VERSION ""

NS_ :

BS_:

BU_: PowertrainControlModule AtmosphericSensor SafetyRestraintSystem2 Aftertreatment_2_GasOutlet Aftertreatment_2_GasIntake DieselPartFilterControl Turbocharger SafetyRestraintSystem1 CabDisplay2 Aftertreatment_1_GasOutlet Aftertreatment_1_GasIntake OnBoardDataLogger OffBoardDiagnosticTool2 OffBoardDiagnosticTool1 FileServer ParkingBrakeController SeatController2 FanDriveController SteeringColumnUnit CommunicationUnitRadio CommunicationUnitSatellite CommunicationUnitCellular PropulsionBatteryCharger ChassisController2 ChassisController1 EngineValveControl AuxiliaryHeater2 AuxiliaryHeater1 ClutchUnit RampControl InformationSystem1 SuspensionSystemController2 OilSensor VehicleDynamicStability ExhaustEmissionController TransmissionDisplay2 TransmissionDisplay1 ClimateControl2 WaterPumpController RearAxleSteeringController LightingOperatorControl SeatController1 IgnitionController2 IgnitionController1 TirePressureController CabController2 CabController1 PneumaticSystemController SuspensionSystemController1 HydraulicPumpController EnduranceBrakingSystem RetarderExhaustEngine2 OnBoardDiagnosticUnit HeadwayController RetarderExhaustEngine1 CabDisplay1 ManagementComputer VirtualTerminal OffVehicleGateway PowerTakeOffFront HitchControl AuxiliaryValveControl BodyController TractorTrailerBridge1 StarterSystem ElectricalSystem VehicleSecurity VehicleNavigation AerodynamicControl ElectricalChargingSystem ClimateControl1 TripRecorder InstrumentCluster SuspensionDriveAxle2 SuspensionDriveAxle1 SuspensionSteerAxle SteeringController FuelSystem CruiseControl RetarderDriveline RetarderEngine BrakesDriveAxle2 BrakesDriveAxle1 BrakesSystemController BrakesSteerAxle AxleDrive2 AxleDrive1 AxleSteering PowerTakeOff ShiftConsoleSecondary ShiftConsolePrimary Transmission2 Transmission1 Engine2 Engine1
VAL_TABLE_ FMI 22 "Data Drifted Low" 21 "Data Drifted High" 20 "Received Network Data In Error" 0 "Above normal (most severe)" 1 "Below normal (most severe)" 2 "Data erratic" 3 "Voltage above normal" 4 "Voltage below normal" 5 "Current below normal" 6 "Current above normal" 7 "Mechanical system not responding" 8 "Abnormal frequency" 9 "Abnormal update rate" 10 "Abnormal rate of change" 11 "Root cause not known" 12 "Bad intelligent device" 13 "Out of calibration" 14 "Special intstructions" 15 "Above normal (least severe)" 16 "Above normal (moderately severe)" 17 "Below normal (least severe)" 18 "Below normal (moderately severe)" 19 "Received network data in error" 31 "Condition Exists" ;
VAL_TABLE_ TireLocation_MUX 51 "TirePress_33_MUX_51" 50 "TirePress_32_MUX_50" 49 "TirePress_31_MUX_49" 48 "TirePress_30_MUX_48" 35 "TirePress_23_MUX_35" 34 "TirePress_22_MUX_34" 33 "TirePress_21_MUX_33" 32 "TirePress_20_MUX_32" 19 "TirePress_13_MUX_19" 18 "TirePress_12_MUX_18" 17 "TirePress_11_MUX_17" 16 "TirePress_10_MUX_16" 1 "TirePress_01_MUX_1" 0 "TirePress_00_MUX_0" ;

BO_ 3221225472 VECTOR__INDEPENDENT_SIG_MSG: 0 Vector__XXX
 SG_ NumberOfMembersInWorkingSet : 0|8@1+ (1,0) [0|0] "" Vector__XXX
 SG_ SourceAddress : 0|8@1+ (1,0) [0|0] "" Vector__XXX
 SG_ NncntnuslyMonitoredSystemsStatus : 0|16@1+ (1,0) [0|0] "" Vector__XXX
 SG_ NncntnslyMonitoredSystemsSupport : 0|16@1+ (1,0) [0|0] "" Vector__XXX
 SG_ CntnslyMntrdSystmsSupport_Status : 0|8@1+ (1,0) [0|0] "" Vector__XXX
 SG_ AETCTorqueValue : 0|16@1+ (1,0) [0|64255] "Nm" Vector__XXX
 SG_ TrailerWeight : 0|16@1+ (2,0) [0|128510] "kg" Vector__XXX
 SG_ ReferenceTirePressSetting : 0|8@1+ (8,0) [0|2000] "kPa" Vector__XXX
 SG_ ReferenceTirePress : 0|8@1+ (8,0) [0|2000] "kPa" Vector__XXX
 SG_ TirePressThresholdDetection : 0|3@1+ (1,0) [0|7] "" Vector__XXX
 SG_ TireAirLeakageRate : 0|16@1+ (0.1,0) [0|6425.5] "Pa/s" Vector__XXX
 SG_ CTIWheelEndElectricalFault : 0|2@1+ (1,0) [0|3] "" Vector__XXX
 SG_ CTITireStatus : 0|2@1+ (1,0) [0|3] "" Vector__XXX
 SG_ CTIWheelSensorStatus : 0|2@1+ (1,0) [0|3] "" Vector__XXX
 SG_ TireTemp : 0|16@1+ (0.03125,-273) [-273|1734.96875] "deg C" Vector__XXX
 SG_ TirePress : 0|8@1+ (4,0) [0|1000] "kPa" Vector__XXX
 SG_ EngTurningGearEngaged : 0|2@1+ (1,0) [0|3] "" Vector__XXX
 SG_ AETCSpeedValue : 0|16@1+ (0.125,0) [0|8031.875] "rpm" Vector__XXX

BO_ 2566658558 PLST1: 8 Vector__XXX
 SG_ TotalHaulCycleCount : 32|32@1+ (1,0) [0|4211081215] "" Vector__XXX
 SG_ TotalDeliveredPayloadWeight : 0|32@1+ (100,0) [0|421108121500] "kg" Vector__XXX

BO_ 2566658302 PLST2: 8 Vector__XXX
 SG_ TotalPayloadTransactionCount : 0|32@1+ (1,0) [0|4211081215] "" Vector__XXX

BO_ 2499549182 PLT1: 8 Vector__XXX

BO_ 2499548926 PLT2: 8 Vector__XXX

BO_ 2499548670 VEP6: 8 Vector__XXX

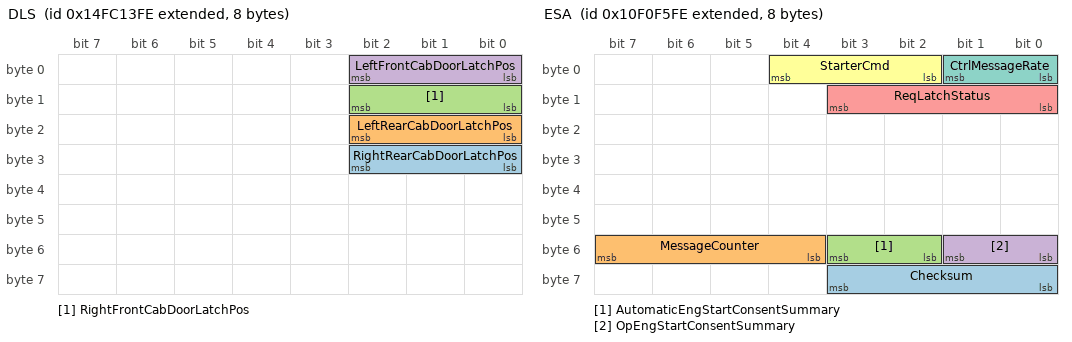
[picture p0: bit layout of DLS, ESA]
BO_ 2499548158 DLS: 8 Vector__XXX
 SG_ RightRearCabDoorLatchPos : 24|3@1+ (1,0) [0|7] "" Vector__XXX
 SG_ LeftRearCabDoorLatchPos : 16|3@1+ (1,0) [0|7] "" Vector__XXX
 SG_ RightFrontCabDoorLatchPos : 8|3@1+ (1,0) [0|7] "" Vector__XXX
 SG_ LeftFrontCabDoorLatchPos : 0|3@1+ (1,0) [0|7] "" Vector__XXX

BO_ 2499547902 CDC: 8 Vector__XXX
 SG_ MirrorRight2HeatCmd : 54|2@1+ (1,0) [0|3] "" Vector__XXX
 SG_ MirrorLeft2HeatCmd : 52|2@1+ (1,0) [0|3] "" Vector__XXX
 SG_ MirrorRight1HeatCmd : 50|2@1+ (1,0) [0|3] "" Vector__XXX
 SG_ MirrorLeft1HeatCmd : 48|2@1+ (1,0) [0|3] "" Vector__XXX
 SG_ MirrorRight2VerticalCmd : 46|2@1+ (1,0) [0|3] "" Vector__XXX
 SG_ MirrorRight2HorizontalCmd : 44|2@1+ (1,0) [0|3] "" Vector__XXX
 SG_ MirrorLeft2VerticalCmd : 42|2@1+ (1,0) [0|3] "" Vector__XXX
 SG_ MirrorLeft2HorizontalCmd : 40|2@1+ (1,0) [0|3] "" Vector__XXX
 SG_ MirrorRight1VerticalCmd : 38|2@1+ (1,0) [0|3] "" Vector__XXX
 SG_ MirrorRight1HorizontalCmd : 36|2@1+ (1,0) [0|3] "" Vector__XXX
 SG_ MirrorLeft1VerticalCmd : 34|2@1+ (1,0) [0|3] "" Vector__XXX
 SG_ MirrorLeft1HorizontalCmd : 32|2@1+ (1,0) [0|3] "" Vector__XXX
 SG_ RightRearWindowPosCmd : 27|3@1+ (1,0) [0|7] "" Vector__XXX
 SG_ LeftRearWindowPosCmd : 24|3@1+ (1,0) [0|7] "" Vector__XXX
 SG_ RightFrontWindowPosCmd : 19|3@1+ (1,0) [0|7] "" Vector__XXX
 SG_ LeftFrontWindowPosCmd : 16|3@1+ (1,0) [0|7] "" Vector__XXX
 SG_ RemoteCabDoorLockReq : 8|3@1+ (1,0) [0|7] "" Vector__XXX
 SG_ DoorsLockActCmd : 0|3@1+ (1,0) [0|7] "" Vector__XXX

BO_ 2566656510 TGFI: 8 Vector__XXX
 SG_ EngTotalGasIdleFuelVolumeUsed : 32|32@1+ (0.5,0) [0|2105540607.5] "m³" Vector__XXX
 SG_ EngTotalGasFuelVolumeUsed : 0|32@1+ (0.5,0) [0|2105540607.5] "m³" Vector__XXX

BO_ 2565929214 ADASIS3: 8 Vector__XXX

BO_ 2565928958 ADASIS2: 8 Vector__XXX

BO_ 2565928702 ADASIS1: 8 Vector__XXX

BO_ 2431710718 ESA: 8 Vector__XXX
 SG_ Checksum : 56|4@1+ (1,0) [0|15] "" Vector__XXX
 SG_ MessageCounter : 52|4@1+ (1,0) [0|15] "" Vector__XXX
 SG_ AutomaticEngStartConsentSummary : 50|2@1+ (1,0) [0|3] "" Vector__XXX
 SG_ OpEngStartConsentSummary : 48|2@1+ (1,0) [0|3] "" Vector__XXX
 SG_ ReqLatchStatus : 8|4@1+ (1,0) [0|15] "" Vector__XXX
 SG_ StarterCmd : 2|3@1+ (1,0) [0|7] "" Vector__XXX
 SG_ CtrlMessageRate : 0|2@1+ (1,0) [0|3] "" Vector__XXX

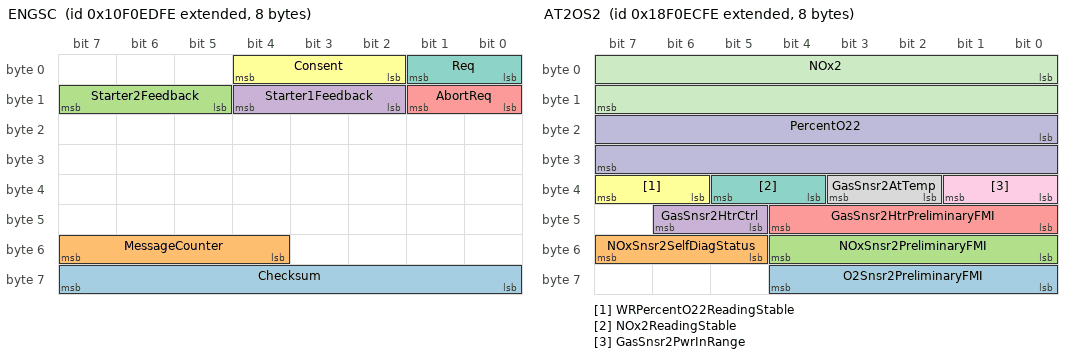
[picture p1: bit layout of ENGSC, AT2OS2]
BO_ 2431708670 ENGSC: 8 Vector__XXX
 SG_ Checksum : 56|8@1+ (1,0) [0|255] "" Vector__XXX
 SG_ MessageCounter : 52|4@1+ (1,0) [0|15] "" Vector__XXX
 SG_ Starter2Feedback : 13|3@1+ (1,0) [0|7] "" Vector__XXX
 SG_ Starter1Feedback : 10|3@1+ (1,0) [0|7] "" Vector__XXX
 SG_ AbortReq : 8|2@1+ (1,0) [0|3] "" Vector__XXX
 SG_ Consent : 2|3@1+ (1,0) [0|7] "" Vector__XXX
 SG_ Req : 0|2@1+ (1,0) [0|3] "" Vector__XXX

BO_ 2566661118 LFC2: 8 Vector__XXX
 SG_ EngTotalDieselFuelDemand : 0|32@1+ (0.5,0) [0|2105540607.5] "L" Vector__XXX

BO_ 2633769726 EEC19: 8 Vector__XXX
 SG_ TotalEngEnergy : 0|32@1+ (1,0) [0|4211081215] "kWh" Vector__XXX

BO_ 2565926142 AT2OS2: 8 Vector__XXX
 SG_ O2Snsr2PreliminaryFMI : 56|5@1+ (1,0) [0|31] "" Vector__XXX
 SG_ NOxSnsr2SelfDiagStatus : 53|3@1+ (1,0) [0|7] "" Vector__XXX
 SG_ NOxSnsr2PreliminaryFMI : 48|5@1+ (1,0) [0|31] "" Vector__XXX
 SG_ GasSnsr2HtrCtrl : 45|2@1+ (1,0) [0|3] "" Vector__XXX
 SG_ GasSnsr2HtrPreliminaryFMI : 40|5@1+ (1,0) [0|31] "" Vector__XXX
 SG_ WRPercentO22ReadingStable : 38|2@1+ (1,0) [0|3] "" Vector__XXX
 SG_ NOx2ReadingStable : 36|2@1+ (1,0) [0|3] "" Vector__XXX
 SG_ GasSnsr2AtTemp : 34|2@1+ (1,0) [0|3] "" Vector__XXX
 SG_ GasSnsr2PwrInRange : 32|2@1+ (1,0) [0|3] "" Vector__XXX
 SG_ PercentO22 : 16|16@1+ (0.000514,-12) [-12|21.02707] "%" Vector__XXX
 SG_ NOx2 : 0|16@1+ (0.05,-200) [-200|3012.75] "ppm" Vector__XXX

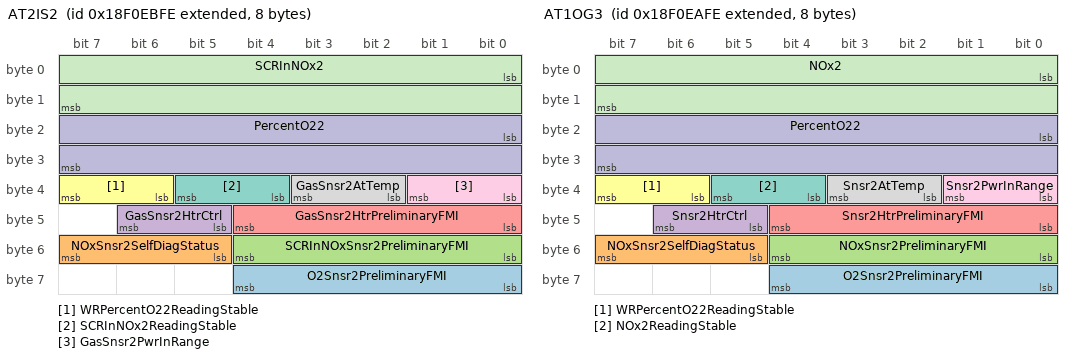
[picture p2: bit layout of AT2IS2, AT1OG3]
BO_ 2565925886 AT2IS2: 8 Vector__XXX
 SG_ O2Snsr2PreliminaryFMI : 56|5@1+ (1,0) [0|31] "" Vector__XXX
 SG_ NOxSnsr2SelfDiagStatus : 53|3@1+ (1,0) [0|7] "" Vector__XXX
 SG_ SCRInNOxSnsr2PreliminaryFMI : 48|5@1+ (1,0) [0|31] "" Vector__XXX
 SG_ GasSnsr2HtrCtrl : 45|2@1+ (1,0) [0|3] "" Vector__XXX
 SG_ GasSnsr2HtrPreliminaryFMI : 40|5@1+ (1,0) [0|31] "" Vector__XXX
 SG_ WRPercentO22ReadingStable : 38|2@1+ (1,0) [0|3] "" Vector__XXX
 SG_ SCRInNOx2ReadingStable : 36|2@1+ (1,0) [0|3] "" Vector__XXX
 SG_ GasSnsr2AtTemp : 34|2@1+ (1,0) [0|3] "" Vector__XXX
 SG_ GasSnsr2PwrInRange : 32|2@1+ (1,0) [0|3] "" Vector__XXX
 SG_ PercentO22 : 16|16@1+ (0.000514,-12) [-12|21.02707] "%" Vector__XXX
 SG_ SCRInNOx2 : 0|16@1+ (0.05,-200) [-200|3012.75] "ppm" Vector__XXX

BO_ 2565925630 AT1OG3: 8 Vector__XXX
 SG_ O2Snsr2PreliminaryFMI : 56|5@1+ (1,0) [0|31] "" Vector__XXX
 SG_ NOxSnsr2SelfDiagStatus : 53|3@1+ (1,0) [0|7] "" Vector__XXX
 SG_ NOxSnsr2PreliminaryFMI : 48|5@1+ (1,0) [0|31] "" Vector__XXX
 SG_ Snsr2HtrCtrl : 45|2@1+ (1,0) [0|3] "" Vector__XXX
 SG_ Snsr2HtrPreliminaryFMI : 40|5@1+ (1,0) [0|31] "" Vector__XXX
 SG_ WRPercentO22ReadingStable : 38|2@1+ (1,0) [0|3] "" Vector__XXX
 SG_ NOx2ReadingStable : 36|2@1+ (1,0) [0|3] "" Vector__XXX
 SG_ Snsr2AtTemp : 34|2@1+ (1,0) [0|3] "" Vector__XXX
 SG_ Snsr2PwrInRange : 32|2@1+ (1,0) [0|3] "" Vector__XXX
 SG_ PercentO22 : 16|16@1+ (0.000514,-12) [-12|21.02707] "%" Vector__XXX
 SG_ NOx2 : 0|16@1+ (0.05,-200) [-200|3012.75] "ppm" Vector__XXX

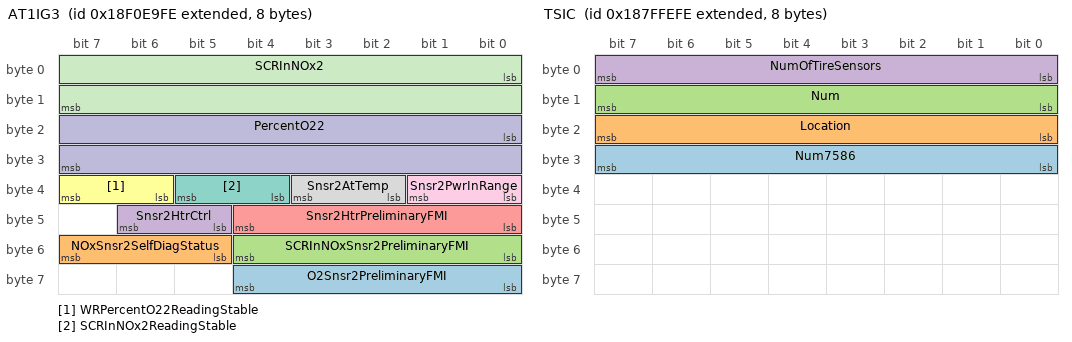
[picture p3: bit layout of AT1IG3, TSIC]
BO_ 2565925374 AT1IG3: 8 Vector__XXX
 SG_ O2Snsr2PreliminaryFMI : 56|5@1+ (1,0) [0|31] "" Vector__XXX
 SG_ NOxSnsr2SelfDiagStatus : 53|3@1+ (1,0) [0|7] "" Vector__XXX
 SG_ SCRInNOxSnsr2PreliminaryFMI : 48|5@1+ (1,0) [0|31] "" Vector__XXX
 SG_ Snsr2HtrCtrl : 45|2@1+ (1,0) [0|3] "" Vector__XXX
 SG_ Snsr2HtrPreliminaryFMI : 40|5@1+ (1,0) [0|31] "" Vector__XXX
 SG_ WRPercentO22ReadingStable : 38|2@1+ (1,0) [0|3] "" Vector__XXX
 SG_ SCRInNOx2ReadingStable : 36|2@1+ (1,0) [0|3] "" Vector__XXX
 SG_ Snsr2AtTemp : 34|2@1+ (1,0) [0|3] "" Vector__XXX
 SG_ Snsr2PwrInRange : 32|2@1+ (1,0) [0|3] "" Vector__XXX
 SG_ PercentO22 : 16|16@1+ (0.000514,-12) [-12|21.02707] "%" Vector__XXX
 SG_ SCRInNOx2 : 0|16@1+ (0.05,-200) [-200|3012.75] "ppm" Vector__XXX

BO_ 2364598526 TFAC2: 8 Vector__XXX
 SG_ FuelAct4CtrlCmd : 48|16@1+ (0.0025,0) [0|160.6375] "%" Vector__XXX
 SG_ FuelAct3CtrlCmd : 32|16@1+ (0.0025,0) [0|100] "%" Vector__XXX

BO_ 2558525182 TSIC: 8 Vector__XXX
 SG_ Num7586 : 24|8@1+ (1,0) [0|255] "" Vector__XXX
 SG_ Location : 16|8@1+ (1,0) [0|0] "" Vector__XXX
 SG_ Num : 8|8@1+ (1,0) [0|250] "" Vector__XXX
 SG_ NumOfTireSensors : 0|8@1+ (1,0) [0|250] "" Vector__XXX

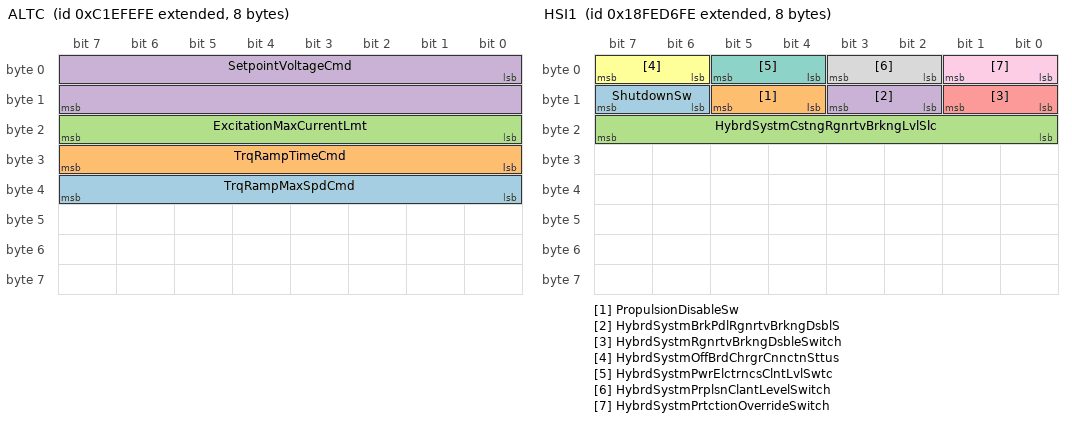
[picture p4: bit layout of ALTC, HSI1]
BO_ 2350841598 ALTC: 8 Vector__XXX
 SG_ TrqRampMaxSpdCmd : 32|8@1+ (32,0) [0|8000] "rpm" Vector__XXX
 SG_ TrqRampTimeCmd : 24|8@1+ (0.1,0) [0.1|25] "s" Vector__XXX
 SG_ ExcitationMaxCurrentLmt : 16|8@1+ (0.25,0) [0|62.5] "A" Vector__XXX
 SG_ SetpointVoltageCmd : 0|16@1+ (0.001,0) [0|64.255] "V" Vector__XXX

BO_ 2566838014 HSI1: 8 Vector__XXX
 SG_ ShutdownSw : 14|2@1+ (1,0) [0|3] "" Vector__XXX
 SG_ PropulsionDisableSw : 12|2@1+ (1,0) [0|3] "" Vector__XXX
 SG_ HybrdSystmCstngRgnrtvBrkngLvlSlc : 16|8@1+ (0.4,0) [0|100] "%" Vector__XXX
 SG_ HybrdSystmBrkPdlRgnrtvBrkngDsblS : 10|2@1+ (1,0) [0|3] "" Vector__XXX
 SG_ HybrdSystmRgnrtvBrkngDsbleSwitch : 8|2@1+ (1,0) [0|3] "" Vector__XXX
 SG_ HybrdSystmOffBrdChrgrCnnctnSttus : 6|2@1+ (1,0) [0|3] "" Vector__XXX
 SG_ HybrdSystmPwrElctrncsClntLvlSwtc : 4|2@1+ (1,0) [0|3] "" Vector__XXX
 SG_ HybrdSystmPrplsnClantLevelSwitch : 2|2@1+ (1,0) [0|3] "" Vector__XXX
 SG_ HybrdSystmPrtctionOverrideSwitch : 0|2@1+ (1,0) [0|3] "" Vector__XXX

BO_ 2566761726 EFI: 8 Vector__XXX
 SG_ EngIdleFuelFlowRateThreshold : 8|32@1+ (0.001,0) [0|4211081.215] "L/h" Vector__XXX
 SG_ NmbrOfFlCnsmptnMntrngTransducers : 0|8@1+ (1,0) [0|250] "" Vector__XXX

BO_ 2566756350 LFI3: 8 Vector__XXX
 SG_ EngFuelReturnTemp : 8|8@1+ (1,-40) [-40|210] "°C" Vector__XXX
 SG_ EngFuelSupplyTemp : 0|8@1+ (1,-40) [-40|210] "°C" Vector__XXX

BO_ 2566756094 LFI2: 8 Vector__XXX
 SG_ EngFuelReturnFlowRate : 32|32@1+ (0.001,0) [0|4211081.215] "L/h" Vector__XXX
 SG_ EngFuelSupplyFlowRate : 0|32@1+ (0.001,0) [0|4211081.215] "L/h" Vector__XXX

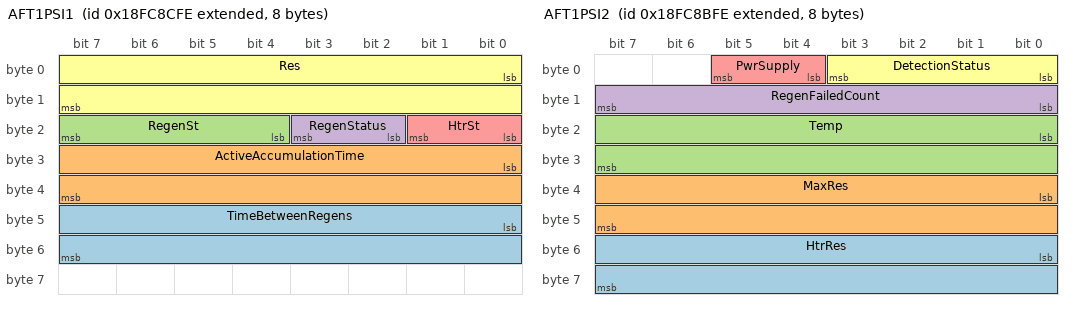
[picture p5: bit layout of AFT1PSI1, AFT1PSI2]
BO_ 2566687998 AFT1PSI1: 8 Vector__XXX
 SG_ TimeBetweenRegens : 40|16@1+ (6,0) [0|385530] "s" Vector__XXX
 SG_ ActiveAccumulationTime : 24|16@1+ (6,0) [0|385530] "s" Vector__XXX
 SG_ RegenSt : 20|4@1+ (1,0) [0|15] "" Vector__XXX
 SG_ RegenStatus : 18|2@1+ (1,0) [0|3] "" Vector__XXX
 SG_ HtrSt : 16|2@1+ (1,0) [0|3] "" Vector__XXX
 SG_ Res : 0|16@1+ (1,0) [0|62500] "kohm" Vector__XXX

BO_ 2566687742 AFT1PSI2: 8 Vector__XXX
 SG_ HtrRes : 48|16@1+ (0.1,0) [0|6425.5] "ohm" Vector__XXX
 SG_ MaxRes : 32|16@1+ (250,0) [0|62500] "kohm" Vector__XXX
 SG_ Temp : 16|16@1+ (0.03125,-273) [-273|1734.96875] "°C" Vector__XXX
 SG_ RegenFailedCount : 8|8@1+ (1,0) [0|250] "" Vector__XXX
 SG_ PwrSupply : 4|2@1+ (1,0) [0|3] "" Vector__XXX
 SG_ DetectionStatus : 0|4@1+ (1,0) [0|15] "" Vector__XXX

BO_ 2365348350 ELS: 8 Vector__XXX
 SG_ EngLoadShareStatus : 2|4@1+ (1,0) [0|15] "" Vector__XXX
 SG_ EngUnloadStatus : 0|2@1+ (1,0) [0|3] "" Vector__XXX

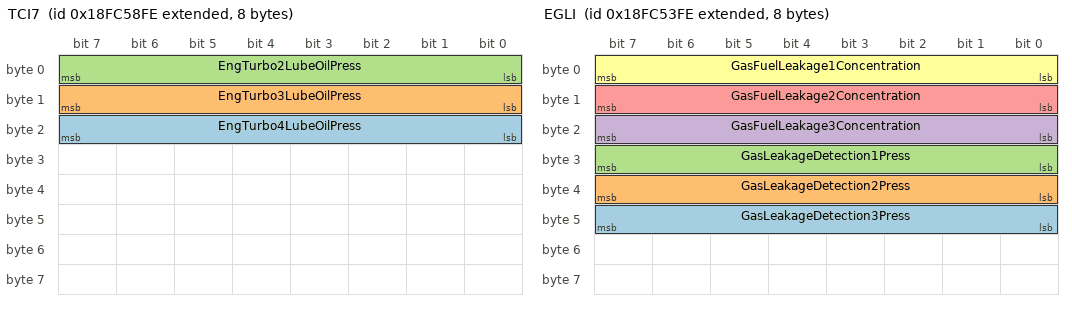
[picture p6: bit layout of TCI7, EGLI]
BO_ 2566674686 TCI7: 8 Vector__XXX
 SG_ EngTurbo4LubeOilPress : 16|8@1+ (4,0) [0|1000] "kPa" Vector__XXX
 SG_ EngTurbo3LubeOilPress : 8|8@1+ (4,0) [0|1000] "kPa" Vector__XXX
 SG_ EngTurbo2LubeOilPress : 0|8@1+ (4,0) [0|1000] "kPa" Vector__XXX

BO_ 2566674430 SCROII1: 8 Vector__XXX
 SG_ DslExhstFldQalityMalfunctionTime : 32|32@1+ (1,0) [0|4211081215] "s" Vector__XXX
 SG_ DieselExhaustFluidTank1EmptyTime : 0|32@1+ (1,0) [0|4211081215] "s" Vector__XXX

BO_ 2566674174 SCROII2: 8 Vector__XXX
 SG_ SCROperatorInducementTotalTime : 32|32@1+ (1,0) [0|4211081215] "s" Vector__XXX
 SG_ AFTSCRMalfunctionTime : 0|32@1+ (1,0) [0|4211081215] "s" Vector__XXX

BO_ 2566673406 EGLI: 8 Vector__XXX
 SG_ GasLeakageDetection3Press : 40|8@1+ (4,0) [0|100] "kPa" Vector__XXX
 SG_ GasLeakageDetection2Press : 32|8@1+ (4,0) [0|100] "kPa" Vector__XXX
 SG_ GasLeakageDetection1Press : 24|8@1+ (4,0) [0|100] "kPa" Vector__XXX
 SG_ GasFuelLeakage3Concentration : 16|8@1+ (0.5,0) [0|100] "%" Vector__XXX
 SG_ GasFuelLeakage2Concentration : 8|8@1+ (0.5,0) [0|100] "%" Vector__XXX
 SG_ GasFuelLeakage1Concentration : 0|8@1+ (0.5,0) [0|100] "%" Vector__XXX

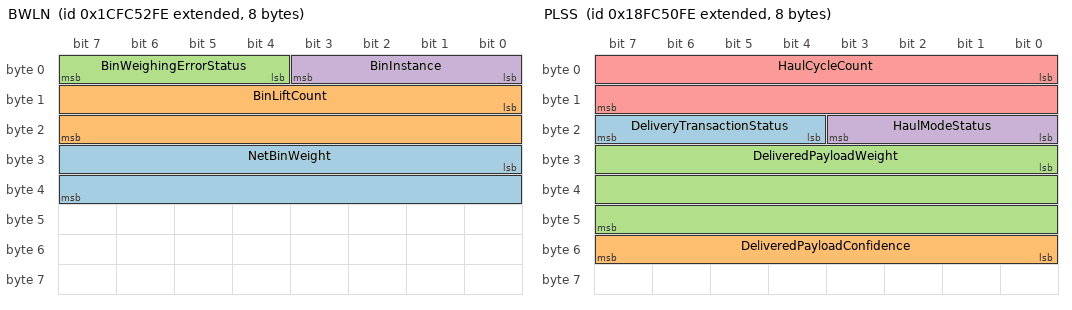
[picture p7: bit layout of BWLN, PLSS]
BO_ 2633782014 BWLN: 8 Vector__XXX
 SG_ NetBinWeight : 24|16@1+ (2,0) [0|128510] "kg" Vector__XXX
 SG_ BinLiftCount : 8|16@1+ (1,0) [0|64255] "" Vector__XXX
 SG_ BinWeighingErrorStatus : 4|4@1+ (1,0) [0|15] "" Vector__XXX
 SG_ BinInstance : 0|4@1+ (1,0) [0|15] "" Vector__XXX

BO_ 2365346302 ASC7: 8 Vector__XXX
 SG_ LiftAxle2Status : 3|3@1+ (1,0) [0|7] "" Vector__XXX
 SG_ LiftAxle1Status : 0|3@1+ (1,0) [0|7] "" Vector__XXX

BO_ 2566672638 PLSS: 8 Vector__XXX
 SG_ DeliveryTransactionStatus : 20|4@1+ (1,0) [0|15] "" Vector__XXX
 SG_ DeliveredPayloadConfidence : 48|8@1+ (0.5,0) [0|100] "%" Vector__XXX
 SG_ DeliveredPayloadWeight : 24|24@1+ (2,0) [0|32899070] "kg" Vector__XXX
 SG_ HaulModeStatus : 16|4@1+ (1,0) [0|15] "" Vector__XXX
 SG_ HaulCycleCount : 0|16@1+ (1,0) [0|64255] "" Vector__XXX

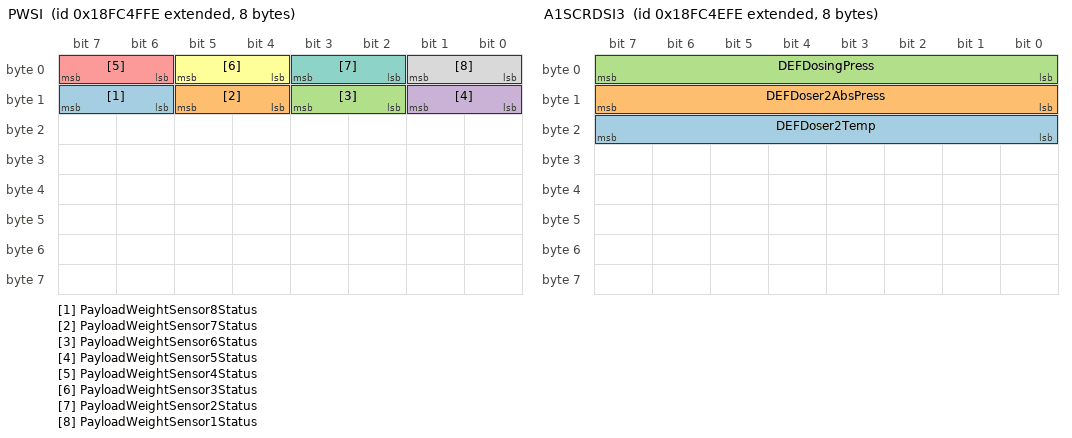
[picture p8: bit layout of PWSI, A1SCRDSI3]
BO_ 2566672382 PWSI: 8 Vector__XXX
 SG_ PayloadWeightSensor8Status : 14|2@1+ (1,0) [0|3] "" Vector__XXX
 SG_ PayloadWeightSensor7Status : 12|2@1+ (1,0) [0|3] "" Vector__XXX
 SG_ PayloadWeightSensor6Status : 10|2@1+ (1,0) [0|3] "" Vector__XXX
 SG_ PayloadWeightSensor5Status : 8|2@1+ (1,0) [0|3] "" Vector__XXX
 SG_ PayloadWeightSensor4Status : 6|2@1+ (1,0) [0|3] "" Vector__XXX
 SG_ PayloadWeightSensor3Status : 4|2@1+ (1,0) [0|3] "" Vector__XXX
 SG_ PayloadWeightSensor2Status : 2|2@1+ (1,0) [0|3] "" Vector__XXX
 SG_ PayloadWeightSensor1Status : 0|2@1+ (1,0) [0|3] "" Vector__XXX

BO_ 2566672126 A1SCRDSI3: 8 Vector__XXX
 SG_ DEFDoser2Temp : 16|8@1+ (1,-40) [-40|210] "°C" Vector__XXX
 SG_ DEFDoser2AbsPress : 8|8@1+ (8,0) [0|2000] "kPa" Vector__XXX
 SG_ DEFDosingPress : 0|8@1+ (4,0) [0|1000] "kPa" Vector__XXX

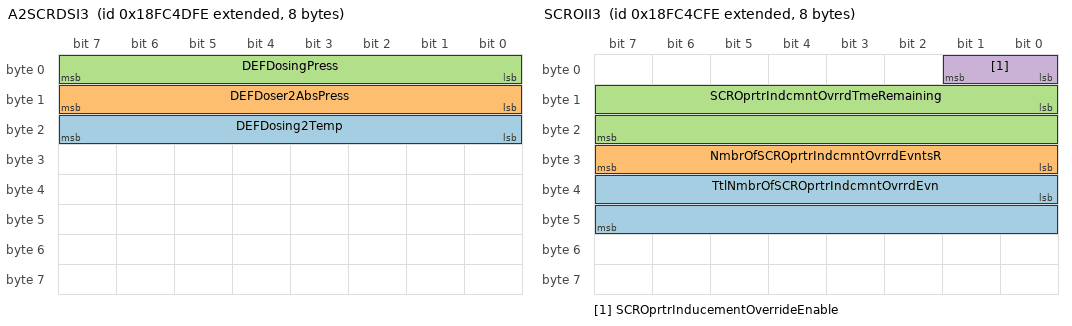
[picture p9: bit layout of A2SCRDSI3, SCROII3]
BO_ 2566671870 A2SCRDSI3: 8 Vector__XXX
 SG_ DEFDosing2Temp : 16|8@1+ (1,-40) [-40|210] "°C" Vector__XXX
 SG_ DEFDoser2AbsPress : 8|8@1+ (8,0) [0|2000] "kPa" Vector__XXX
 SG_ DEFDosingPress : 0|8@1+ (4,0) [0|1000] "kPa" Vector__XXX

BO_ 2566671614 SCROII3: 8 Vector__XXX
 SG_ TtlNmbrOfSCROprtrIndcmntOvrrdEvn : 32|16@1+ (1,0) [0|64255] "" Vector__XXX
 SG_ NmbrOfSCROprtrIndcmntOvrrdEvntsR : 24|8@1+ (1,0) [0|250] "" Vector__XXX
 SG_ SCROprtrIndcmntOvrrdTmeRemaining : 8|16@1+ (1,0) [0|64255] "s" Vector__XXX
 SG_ SCROprtrInducementOverrideEnable : 0|2@1+ (1,0) [0|3] "" Vector__XXX

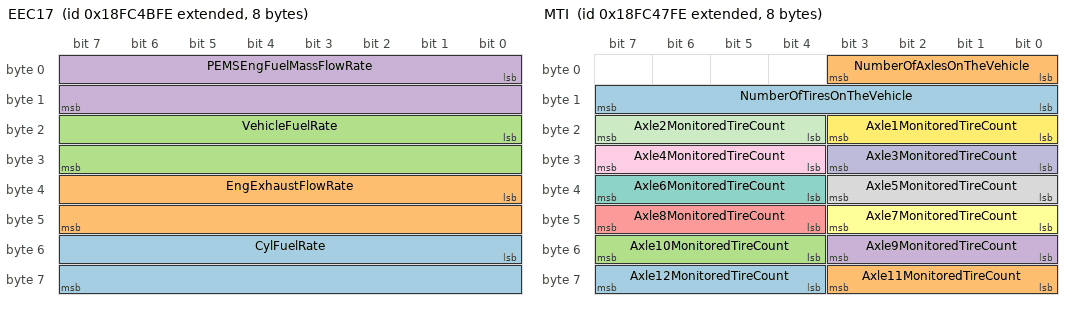
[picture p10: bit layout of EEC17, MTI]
BO_ 2566671358 EEC17: 8 Vector__XXX
 SG_ CylFuelRate : 48|16@1+ (0.03125,0) [0|2007.96875] "mg/stroke" Vector__XXX
 SG_ EngExhaustFlowRate : 32|16@1+ (0.2,0) [0|12851] "kg/h" Vector__XXX
 SG_ VehicleFuelRate : 16|16@1+ (0.02,0) [0|1285.1] "g/s" Vector__XXX
 SG_ PEMSEngFuelMassFlowRate : 0|16@1+ (0.02,0) [0|1285.1] "g/s" Vector__XXX

BO_ 2566671102 SCRSC: 8 Vector__XXX
 SG_ SCRSystemCleaningForcedStatus : 53|3@1+ (1,0) [0|7] "" Vector__XXX
 SG_ SCRSystmClnngAtmtcIntationConfig : 48|2@1+ (1,0) [0|3] "" Vector__XXX
 SG_ SCRSystmClnngInhbtdDTVhclSpdBlwA : 46|2@1+ (1,0) [0|3] "" Vector__XXX
 SG_ SCRSystmClnngInhbtdDTEngNtWrmdUp : 44|2@1+ (1,0) [0|3] "" Vector__XXX
 SG_ SCRSystmClnngInhbtdDTPrmnntSystm : 42|2@1+ (1,0) [0|3] "" Vector__XXX
 SG_ SCRSystmClnngInhbtdDTTmprrySystm : 40|2@1+ (1,0) [0|3] "" Vector__XXX
 SG_ SCRSystmClnngInhbtdDTSystmTmeout : 38|2@1+ (1,0) [0|3] "" Vector__XXX
 SG_ SCRSystmClnngInhbtdDTSystmFltAct : 36|2@1+ (1,0) [0|3] "" Vector__XXX
 SG_ SCRSystmClnngInhbtdDTLwExhstTemp : 34|2@1+ (1,0) [0|3] "" Vector__XXX
 SG_ SCRSystmClnngInhbtdDTPrkngBrkNtS : 32|2@1+ (1,0) [0|3] "" Vector__XXX
 SG_ SCRSystmClnngInhbtdDTVhclSpdAbvA : 30|2@1+ (1,0) [0|3] "" Vector__XXX
 SG_ SCRSystmClnngInhbtdDTOtOfNeutral : 28|2@1+ (1,0) [0|3] "" Vector__XXX
 SG_ SCRSystmClnngInhbtdDTAcclPdlOffI : 26|2@1+ (1,0) [0|3] "" Vector__XXX
 SG_ SCRSystmClnngInhbtdDeToPTOActive : 24|2@1+ (1,0) [0|3] "" Vector__XXX
 SG_ SCRSystmClnngInhbtdDTSrvcBrkActv : 22|2@1+ (1,0) [0|3] "" Vector__XXX
 SG_ SCRSystmClnngInhbtdDTCltchDsnggd : 20|2@1+ (1,0) [0|3] "" Vector__XXX
 SG_ SCRSystmClnngInhbtdDTInhbtSwitch : 18|2@1+ (1,0) [0|3] "" Vector__XXX
 SG_ SCRSystemCleaningInhibitedStatus : 16|2@1+ (1,0) [0|3] "" Vector__XXX
 SG_ SCRSystemCleaningStatus : 10|2@1+ (1,0) [0|3] "" Vector__XXX
 SG_ SCRSystemCleaningLampCmd : 0|3@1+ (1,0) [0|7] "" Vector__XXX

BO_ 2566670846 AT1HI2: 8 Vector__XXX
 SG_ SCRSysAvgDistBetweenCleanEvents : 160|32@1+ (0.125,0) [0|526385151.875] "km" Vector__XXX
 SG_ SCRSysAvgTimeBetweenCleanEvents : 128|32@1+ (1,0) [0|4211081215] "s" Vector__XXX
 SG_ SCRSysTotalSysCleanManReq : 96|32@1+ (1,0) [0|4211081215] "" Vector__XXX
 SG_ SCRSysTotalSysCleanInhReq : 64|32@1+ (1,0) [0|4211081215] "" Vector__XXX
 SG_ SCRSysTotalSysCleanEvents : 32|32@1+ (1,0) [0|4211081215] "" Vector__XXX
 SG_ SCRSysTotalCleanTime : 0|32@1+ (1,0) [0|4211081215] "s" Vector__XXX

BO_ 2566670590 AT2HI2: 8 Vector__XXX
 SG_ SCRSysAvgDistBetweenCleanEvents : 160|32@1+ (0.125,0) [0|526385151.875] "km" Vector__XXX
 SG_ SCRSysAvgTimeBetweenCleanEvents : 128|32@1+ (1,0) [0|4211081215] "s" Vector__XXX
 SG_ SCRSysTotalSysCleanManReq : 96|32@1+ (1,0) [0|4211081215] "" Vector__XXX
 SG_ SCRSysTotalSysCleanInhReq : 64|32@1+ (1,0) [0|4211081215] "" Vector__XXX
 SG_ SCRSysTotalSysCleanEvents : 32|32@1+ (1,0) [0|4211081215] "" Vector__XXX
 SG_ SCRSysTotalSysCleanTime : 0|32@1+ (1,0) [0|4211081215] "s" Vector__XXX

BO_ 2566670334 MTI: 8 Vector__XXX
 SG_ Axle12MonitoredTireCount : 60|4@1+ (1,0) [0|13] "" Vector__XXX
 SG_ Axle11MonitoredTireCount : 56|4@1+ (1,0) [0|13] "" Vector__XXX
 SG_ Axle10MonitoredTireCount : 52|4@1+ (1,0) [0|13] "" Vector__XXX
 SG_ Axle9MonitoredTireCount : 48|4@1+ (1,0) [0|13] "" Vector__XXX
 SG_ Axle8MonitoredTireCount : 44|4@1+ (1,0) [0|13] "" Vector__XXX
 SG_ Axle7MonitoredTireCount : 40|4@1+ (1,0) [0|13] "" Vector__XXX
 SG_ Axle6MonitoredTireCount : 36|4@1+ (1,0) [0|13] "" Vector__XXX
 SG_ Axle5MonitoredTireCount : 32|4@1+ (1,0) [0|13] "" Vector__XXX
 SG_ Axle4MonitoredTireCount : 28|4@1+ (1,0) [0|13] "" Vector__XXX
 SG_ Axle3MonitoredTireCount : 24|4@1+ (1,0) [0|13] "" Vector__XXX
 SG_ Axle2MonitoredTireCount : 20|4@1+ (1,0) [0|13] "" Vector__XXX
 SG_ Axle1MonitoredTireCount : 16|4@1+ (1,0) [0|13] "" Vector__XXX
 SG_ NumberOfTiresOnTheVehicle : 8|8@1+ (1,0) [0|250] "" Vector__XXX
 SG_ NumberOfAxlesOnTheVehicle : 0|4@1+ (1,0) [0|13] "" Vector__XXX

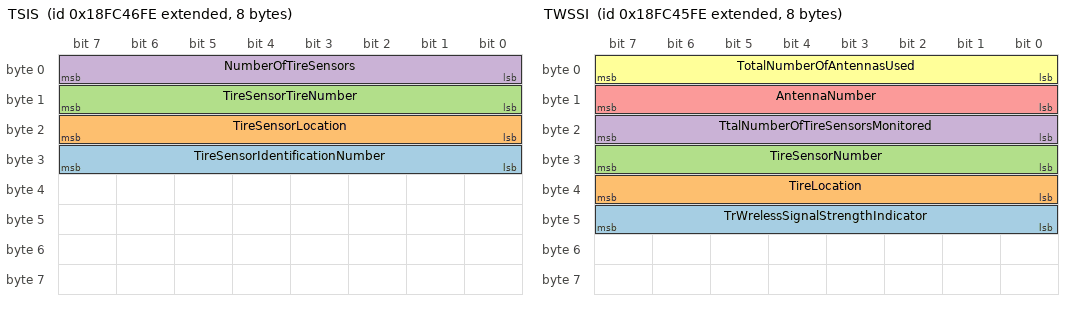
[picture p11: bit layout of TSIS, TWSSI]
BO_ 2566670078 TSIS: 8 Vector__XXX
 SG_ TireSensorIdentificationNumber : 24|8@1+ (1,0) [0|255] "" Vector__XXX
 SG_ TireSensorLocation : 16|8@1+ (1,0) [0|255] "" Vector__XXX
 SG_ TireSensorTireNumber : 8|8@1+ (1,0) [0|250] "" Vector__XXX
 SG_ NumberOfTireSensors : 0|8@1+ (1,0) [0|250] "" Vector__XXX

BO_ 2566669822 TWSSI: 8 Vector__XXX
 SG_ TrWrelessSignalStrengthIndicator : 40|8@1+ (0.5,-125) [-125|0] "dBm" Vector__XXX
 SG_ TireLocation : 32|8@1+ (1,0) [0|0] "" Vector__XXX
 SG_ TireSensorNumber : 24|8@1+ (1,0) [0|250] "" Vector__XXX
 SG_ TtalNumberOfTireSensorsMonitored : 16|8@1+ (1,0) [0|250] "" Vector__XXX
 SG_ AntennaNumber : 8|8@1+ (1,0) [0|250] "" Vector__XXX
 SG_ TotalNumberOfAntennasUsed : 0|8@1+ (1,0) [0|250] "" Vector__XXX

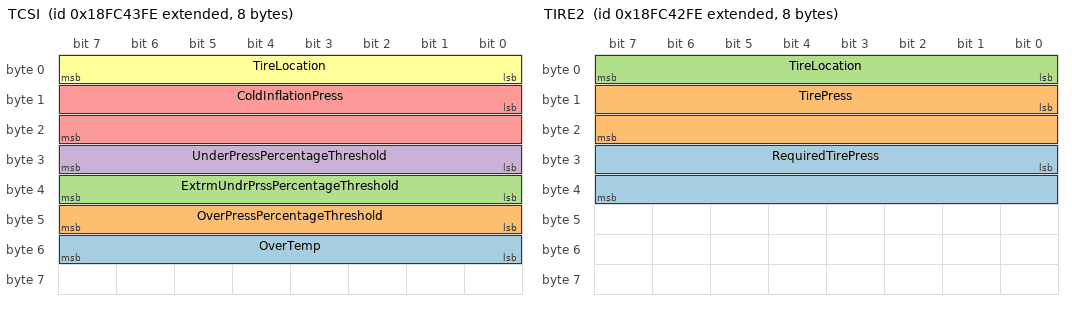
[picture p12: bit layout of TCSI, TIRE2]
BO_ 2566669310 TCSI: 8 Vector__XXX
 SG_ OverTemp : 48|8@1+ (1,-40) [-40|210] "°C" Vector__XXX
 SG_ OverPressPercentageThreshold : 40|8@1+ (0.5,0) [0|125] "%" Vector__XXX
 SG_ ExtrmUndrPrssPercentageThreshold : 32|8@1+ (0.5,0) [0|125] "%" Vector__XXX
 SG_ UnderPressPercentageThreshold : 24|8@1+ (0.5,0) [0|125] "%" Vector__XXX
 SG_ ColdInflationPress : 8|16@1+ (1,0) [0|64255] "kPa" Vector__XXX
 SG_ TireLocation : 0|8@1+ (1,0) [0|0] "" Vector__XXX

BO_ 2566669054 TIRE2: 8 Vector__XXX
 SG_ RequiredTirePress : 24|16@1+ (1,0) [0|64255] "kPa" Vector__XXX
 SG_ TirePress : 8|16@1+ (1,0) [0|64255] "kPa" Vector__XXX
 SG_ TireLocation : 0|8@1+ (1,0) [0|0] "" Vector__XXX

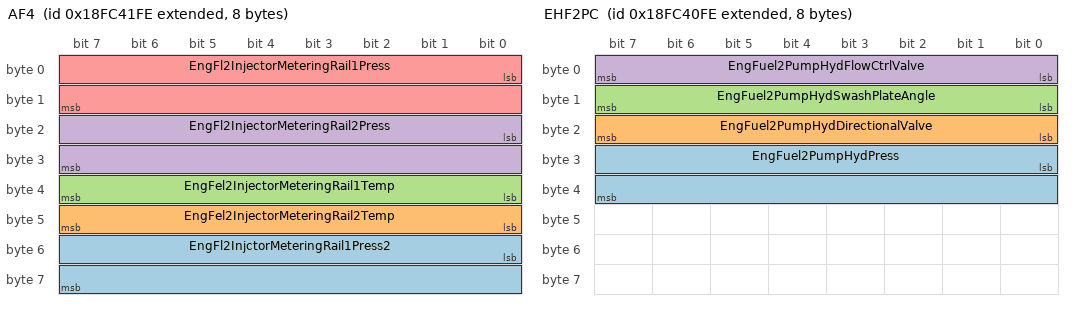
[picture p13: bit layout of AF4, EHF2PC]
BO_ 2566668798 AF4: 8 Vector__XXX
 SG_ EngFl2InjctorMeteringRail1Press2 : 48|16@1+ (2,0) [0|128510] "kPa" Vector__XXX
 SG_ EngFel2InjectorMeteringRail2Temp : 40|8@1+ (1,-40) [-40|210] "°C" Vector__XXX
 SG_ EngFel2InjectorMeteringRail1Temp : 32|8@1+ (1,-40) [-40|210] "°C" Vector__XXX
 SG_ EngFl2InjectorMeteringRail2Press : 16|16@1+ (2,0) [0|128510] "kPa" Vector__XXX
 SG_ EngFl2InjectorMeteringRail1Press : 0|16@1+ (2,0) [0|128510] "kPa" Vector__XXX

BO_ 2566668542 EHF2PC: 8 Vector__XXX
 SG_ EngFuel2PumpHydPress : 24|16@1+ (2,0) [0|128510] "kPa" Vector__XXX
 SG_ EngFuel2PumpHydDirectionalValve : 16|8@1+ (0.4,0) [0|100] "%" Vector__XXX
 SG_ EngFuel2PumpHydSwashPlateAngle : 8|8@1+ (0.4,0) [0|100] "%" Vector__XXX
 SG_ EngFuel2PumpHydFlowCtrlValve : 0|8@1+ (0.4,0) [0|100] "%" Vector__XXX

BO_ 2566668286 ETCC2: 8 Vector__XXX
 SG_ EngStagedTurboSolenoidStatus : 0|8@1+ (0.4,0) [0|100] "%" Vector__XXX

BO_ 2566668030 HEDPI: 8 Vector__XXX
 SG_ HtExchngerDebrisPurgeApproaching : 2|2@1+ (1,0) [0|3] "" Vector__XXX
 SG_ HeatExchangerDebrisPurgeStatus : 0|2@1+ (1,0) [0|3] "" Vector__XXX

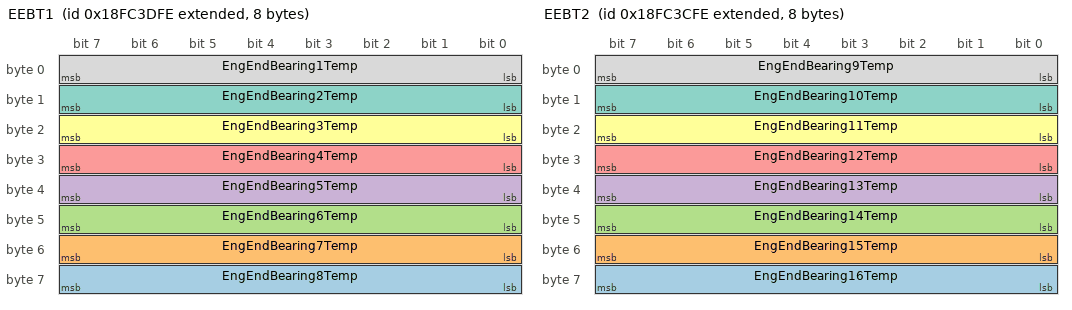
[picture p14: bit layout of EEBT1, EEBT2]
BO_ 2566667774 EEBT1: 8 Vector__XXX
 SG_ EngEndBearing8Temp : 56|8@1+ (1,-40) [-40|210] "°C" Vector__XXX
 SG_ EngEndBearing7Temp : 48|8@1+ (1,-40) [-40|210] "°C" Vector__XXX
 SG_ EngEndBearing6Temp : 40|8@1+ (1,-40) [-40|210] "°C" Vector__XXX
 SG_ EngEndBearing5Temp : 32|8@1+ (1,-40) [-40|210] "°C" Vector__XXX
 SG_ EngEndBearing4Temp : 24|8@1+ (1,-40) [-40|210] "°C" Vector__XXX
 SG_ EngEndBearing3Temp : 16|8@1+ (1,-40) [-40|210] "°C" Vector__XXX
 SG_ EngEndBearing2Temp : 8|8@1+ (1,-40) [-40|210] "°C" Vector__XXX
 SG_ EngEndBearing1Temp : 0|8@1+ (1,-40) [-40|210] "°C" Vector__XXX

BO_ 2566667518 EEBT2: 8 Vector__XXX
 SG_ EngEndBearing16Temp : 56|8@1+ (1,-40) [-40|210] "°C" Vector__XXX
 SG_ EngEndBearing15Temp : 48|8@1+ (1,-40) [-40|210] "°C" Vector__XXX
 SG_ EngEndBearing14Temp : 40|8@1+ (1,-40) [-40|210] "°C" Vector__XXX
 SG_ EngEndBearing13Temp : 32|8@1+ (1,-40) [-40|210] "°C" Vector__XXX
 SG_ EngEndBearing12Temp : 24|8@1+ (1,-40) [-40|210] "°C" Vector__XXX
 SG_ EngEndBearing11Temp : 16|8@1+ (1,-40) [-40|210] "°C" Vector__XXX
 SG_ EngEndBearing10Temp : 8|8@1+ (1,-40) [-40|210] "°C" Vector__XXX
 SG_ EngEndBearing9Temp : 0|8@1+ (1,-40) [-40|210] "°C" Vector__XXX

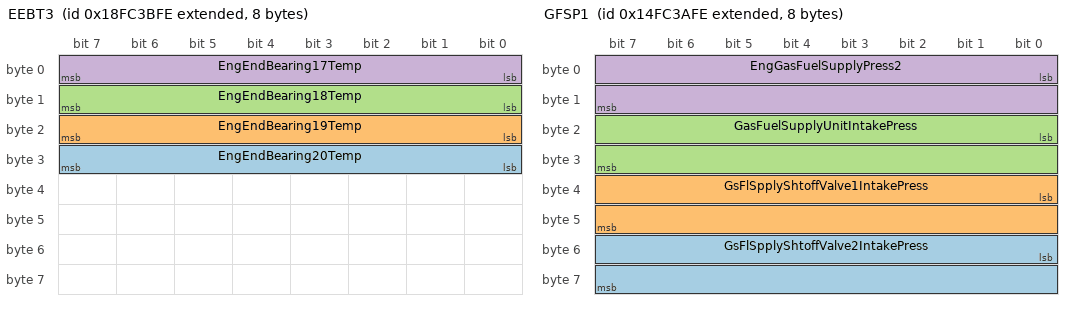
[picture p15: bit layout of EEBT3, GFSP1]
BO_ 2566667262 EEBT3: 8 Vector__XXX
 SG_ EngEndBearing20Temp : 24|8@1+ (1,-40) [-40|210] "°C" Vector__XXX
 SG_ EngEndBearing19Temp : 16|8@1+ (1,-40) [-40|210] "°C" Vector__XXX
 SG_ EngEndBearing18Temp : 8|8@1+ (1,-40) [-40|210] "°C" Vector__XXX
 SG_ EngEndBearing17Temp : 0|8@1+ (1,-40) [-40|210] "°C" Vector__XXX

BO_ 2499558142 GFSP1: 8 Vector__XXX
 SG_ GsFlSpplyShtoffValve2IntakePress : 48|16@1+ (0.5,0) [0|32127.5] "kPa" Vector__XXX
 SG_ GsFlSpplyShtoffValve1IntakePress : 32|16@1+ (0.5,0) [0|32127.5] "kPa" Vector__XXX
 SG_ GasFuelSupplyUnitIntakePress : 16|16@1+ (0.5,0) [0|32127.5] "kPa" Vector__XXX
 SG_ EngGasFuelSupplyPress2 : 0|16@1+ (0.5,0) [0|32127.5] "kPa" Vector__XXX

BO_ 2499557886 GFSP2: 8 Vector__XXX
 SG_ PlantInertGasSupplyOutletPress : 16|16@1+ (0.5,0) [0|32127.5] "kPa" Vector__XXX
 SG_ PlantGasFuelSupplyOutletPress : 0|16@1+ (0.5,0) [0|32127.5] "kPa" Vector__XXX

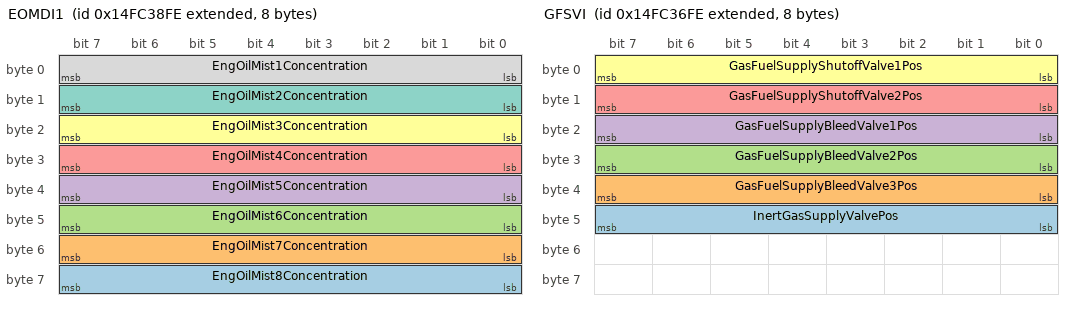
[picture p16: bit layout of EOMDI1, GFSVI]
BO_ 2499557630 EOMDI1: 8 Vector__XXX
 SG_ EngOilMist8Concentration : 56|8@1+ (1,0) [0|250] "%" Vector__XXX
 SG_ EngOilMist7Concentration : 48|8@1+ (1,0) [0|250] "%" Vector__XXX
 SG_ EngOilMist6Concentration : 40|8@1+ (1,0) [0|250] "%" Vector__XXX
 SG_ EngOilMist5Concentration : 32|8@1+ (1,0) [0|250] "%" Vector__XXX
 SG_ EngOilMist4Concentration : 24|8@1+ (1,0) [0|250] "%" Vector__XXX
 SG_ EngOilMist3Concentration : 16|8@1+ (1,0) [0|250] "%" Vector__XXX
 SG_ EngOilMist2Concentration : 8|8@1+ (1,0) [0|250] "%" Vector__XXX
 SG_ EngOilMist1Concentration : 0|8@1+ (1,0) [0|250] "%" Vector__XXX

BO_ 2499557374 EOMDI2: 8 Vector__XXX
 SG_ EngOilMist10Concentration : 8|8@1+ (1,0) [0|250] "%" Vector__XXX
 SG_ EngOilMist9Concentration : 0|8@1+ (1,0) [0|250] "%" Vector__XXX

BO_ 2499557118 GFSVI: 8 Vector__XXX
 SG_ InertGasSupplyValvePos : 40|8@1+ (0.4,0) [0|100] "%" Vector__XXX
 SG_ GasFuelSupplyBleedValve3Pos : 32|8@1+ (0.4,0) [0|100] "%" Vector__XXX
 SG_ GasFuelSupplyBleedValve2Pos : 24|8@1+ (0.4,0) [0|100] "%" Vector__XXX
 SG_ GasFuelSupplyBleedValve1Pos : 16|8@1+ (0.4,0) [0|100] "%" Vector__XXX
 SG_ GasFuelSupplyShutoffValve2Pos : 8|8@1+ (0.4,0) [0|100] "%" Vector__XXX
 SG_ GasFuelSupplyShutoffValve1Pos : 0|8@1+ (0.4,0) [0|100] "%" Vector__XXX

BO_ 2566665726 AT2P1I: 8 Vector__XXX
 SG_ TwoMotorSpd : 8|16@1+ (0.5,0) [0|32127.5] "rpm" Vector__XXX
 SG_ Htr : 0|8@1+ (0.4,0) [0|100] "%" Vector__XXX

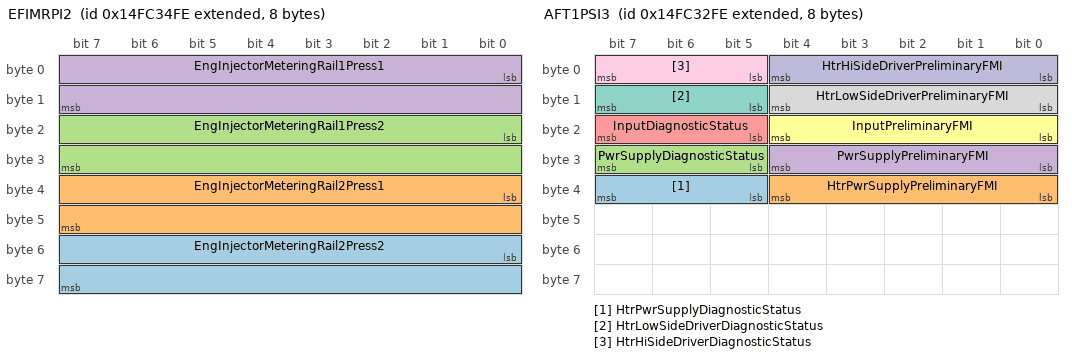
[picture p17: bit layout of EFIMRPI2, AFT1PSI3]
BO_ 2499556606 EFIMRPI2: 8 Vector__XXX
 SG_ EngInjectorMeteringRail2Press2 : 48|16@1+ (5,0) [0|321275] "kPa" Vector__XXX
 SG_ EngInjectorMeteringRail2Press1 : 32|16@1+ (5,0) [0|321275] "kPa" Vector__XXX
 SG_ EngInjectorMeteringRail1Press2 : 16|16@1+ (5,0) [0|321275] "kPa" Vector__XXX
 SG_ EngInjectorMeteringRail1Press1 : 0|16@1+ (5,0) [0|321275] "kPa" Vector__XXX

BO_ 2499556350 EFIMRPI3: 8 Vector__XXX
 SG_ EngInjctrMtringRail2DesiredPress : 16|16@1+ (5,0) [0|321275] "kPa" Vector__XXX
 SG_ EngInjctrMtringRail1DesiredPress : 0|16@1+ (5,0) [0|321275] "kPa" Vector__XXX

BO_ 2499556094 AFT1PSI3: 8 Vector__XXX
 SG_ HtrPwrSupplyDiagnosticStatus : 37|3@1+ (1,0) [0|7] "" Vector__XXX
 SG_ HtrPwrSupplyPreliminaryFMI : 32|5@1+ (1,0) [0|31] "" Vector__XXX
 SG_ PwrSupplyDiagnosticStatus : 29|3@1+ (1,0) [0|7] "" Vector__XXX
 SG_ PwrSupplyPreliminaryFMI : 24|5@1+ (1,0) [0|31] "" Vector__XXX
 SG_ InputDiagnosticStatus : 21|3@1+ (1,0) [0|7] "" Vector__XXX
 SG_ InputPreliminaryFMI : 16|5@1+ (1,0) [0|31] "" Vector__XXX
 SG_ HtrLowSideDriverDiagnosticStatus : 13|3@1+ (1,0) [0|7] "" Vector__XXX
 SG_ HtrLowSideDriverPreliminaryFMI : 8|5@1+ (1,0) [0|31] "" Vector__XXX
 SG_ HtrHiSideDriverDiagnosticStatus : 5|3@1+ (1,0) [0|7] "" Vector__XXX
 SG_ HtrHiSideDriverPreliminaryFMI : 0|5@1+ (1,0) [0|31] "" Vector__XXX

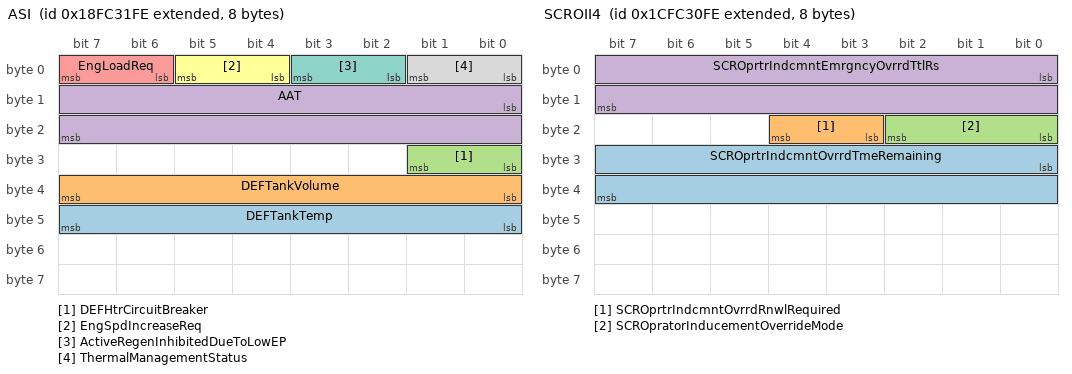
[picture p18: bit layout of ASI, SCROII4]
BO_ 2566664702 ASI: 8 Vector__XXX
 SG_ DEFTankTemp : 40|8@1+ (1,-40) [-40|210] "°C" Vector__XXX
 SG_ DEFTankVolume : 32|8@1+ (0.4,0) [0|100] "%" Vector__XXX
 SG_ DEFHtrCircuitBreaker : 24|2@1+ (1,0) [0|3] "" Vector__XXX
 SG_ AAT : 8|16@1+ (0.03125,-273) [-273|1734.96875] "°C" Vector__XXX
 SG_ EngLoadReq : 6|2@1+ (1,0) [0|3] "" Vector__XXX
 SG_ EngSpdIncreaseReq : 4|2@1+ (1,0) [0|3] "" Vector__XXX
 SG_ ActiveRegenInhibitedDueToLowEP : 2|2@1+ (1,0) [0|3] "" Vector__XXX
 SG_ ThermalManagementStatus : 0|2@1+ (1,0) [0|3] "" Vector__XXX

BO_ 2633773310 SCROII4: 8 Vector__XXX
 SG_ SCROprtrIndcmntOvrrdTmeRemaining : 24|16@1+ (1,0) [0|64255] "min" Vector__XXX
 SG_ SCROprtrIndcmntOvrrdRnwlRequired : 19|2@1+ (1,0) [0|3] "" Vector__XXX
 SG_ SCROpratorInducementOverrideMode : 16|3@1+ (1,0) [0|7] "" Vector__XXX
 SG_ SCROprtrIndcmntEmrgncyOvrrdTtlRs : 0|16@1+ (1,0) [0|64255] "" Vector__XXX

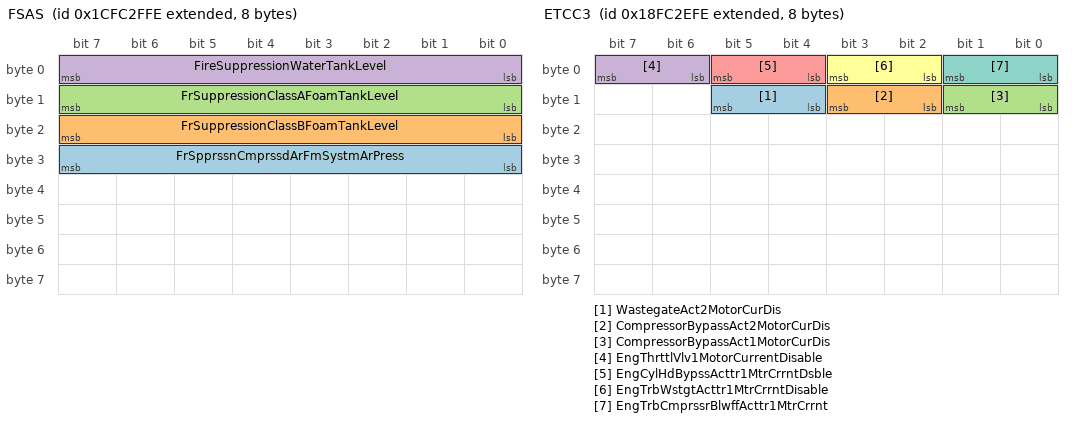
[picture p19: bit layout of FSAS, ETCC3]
BO_ 2633773054 FSAS: 8 Vector__XXX
 SG_ FrSpprssnCmprssdArFmSystmArPress : 24|8@1+ (8,0) [0|2000] "kPa" Vector__XXX
 SG_ FrSuppressionClassBFoamTankLevel : 16|8@1+ (0.4,0) [0|100] "%" Vector__XXX
 SG_ FrSuppressionClassAFoamTankLevel : 8|8@1+ (0.4,0) [0|100] "%" Vector__XXX
 SG_ FireSuppressionWaterTankLevel : 0|8@1+ (0.4,0) [0|100] "%" Vector__XXX

BO_ 2566663934 ETCC3: 8 Vector__XXX
 SG_ WastegateAct2MotorCurDis : 12|2@1+ (1,0) [0|3] "" Vector__XXX
 SG_ CompressorBypassAct2MotorCurDis : 10|2@1+ (1,0) [0|3] "" Vector__XXX
 SG_ CompressorBypassAct1MotorCurDis : 8|2@1+ (1,0) [0|3] "" Vector__XXX
 SG_ EngThrttlVlv1MotorCurrentDisable : 6|2@1+ (1,0) [0|3] "" Vector__XXX
 SG_ EngCylHdBypssActtr1MtrCrrntDsble : 4|2@1+ (1,0) [0|3] "" Vector__XXX
 SG_ EngTrbWstgtActtr1MtrCrrntDisable : 2|2@1+ (1,0) [0|3] "" Vector__XXX
 SG_ EngTrbCmprssrBlwffActtr1MtrCrrnt : 0|2@1+ (1,0) [0|3] "" Vector__XXX

BO_ 2566663678 AF5: 8 Vector__XXX
 SG_ EngFl2InjectorMeteringRail1Temp2 : 32|8@1+ (1,-40) [-40|210] "°C" Vector__XXX
 SG_ LNGTank2VaporPress : 16|16@1+ (0.1,0) [0|6425.5] "kPa" Vector__XXX
 SG_ LNGTank1VaporPress : 0|16@1+ (0.1,0) [0|6425.5] "kPa" Vector__XXX

CM_ BU_ PowertrainControlModule "Electronic control module in charge of controlling and coordinating the operation of a hybrid propulsion system.";
CM_ BU_ HitchControl "Straight truck hitch (NOT Agricultural hitch – it is in IG 2) ";
CM_ BO_ 3221225472 "This is a message for not used signals, created by Vector CANdb++ DBC OLE DB Provider.";
CM_ SG_ 3221225472 NumberOfMembersInWorkingSet "The number of members in a particular Working Set.";
CM_ SG_ 3221225472 SourceAddress "Instance of a Source Address listed a Network Message data field.";
CM_ SG_ 3221225472 NncntnuslyMonitoredSystemsStatus "Identifies the non-continuously monitored systems status. Each bit identifies whether a particular test is complete for a given controller.
";
CM_ SG_ 3221225472 NncntnslyMonitoredSystemsSupport "Identifies the non-continuously monitored systems support.
";
CM_ SG_ 3221225472 CntnslyMntrdSystmsSupport_Status "Identifies the continuously monitored system support and status.
";
CM_ SG_ 3221225472 AETCTorqueValue "Engine torque value of the data points in PGN 64912 – Advertised Engine Torque Curve (AETC).";
CM_ SG_ 3221225472 TrailerWeight "Total mass of freight-carrying vehicle designed to be pulled by truck, including the weight of the contents.";
CM_ SG_ 3221225472 ReferenceTirePressSetting "Reference value of the tire pressure setting as basis for the tire pressure monitoring ...";
CM_ SG_ 3221225472 ReferenceTirePress "Reference value of the tire pressure as basis for the tire pressure monitoring ...";
CM_ SG_ 3221225472 TirePressThresholdDetection "Signal indicating the pressure level of the tire.  The levels defined represent different pressure conditions of the tire: 000 Extreme over pressure - The tire pressure is at a level where the safety of the vehicle may be jeopardised.";
CM_ SG_ 3221225472 TireAirLeakageRate "The pressure loss rate of a tire.";
CM_ SG_ 3221225472 CTIWheelEndElectricalFault "Indicates the status of electrical fault on CTI wheel interface.";
CM_ SG_ 3221225472 CTITireStatus "Indicates the status of the tire.";
CM_ SG_ 3221225472 CTIWheelSensorStatus "Indicates whether the wheel is being monitored by the CTI controller.";
CM_ SG_ 3221225472 TireTemp "Temperature at the surface of the tire sidewall.";
CM_ SG_ 3221225472 TirePress "Pressure at which air is contained in cavity formed by tire and rim.";
CM_ SG_ 3221225472 EngTurningGearEngaged "Status signal which indicates that the turning gear is engaged.  The turning gear is used to turn the flywheel/crankshaft, ...";
CM_ SG_ 3221225472 AETCSpeedValue "Engine speed value of the data points in PGN 64912 – Advertised Engine Torque Curve (AETC).";
CM_ BO_ 2566658558 "Payload System Totals 1
Payload measurement system accumulators related to the haul cycle productivity.";
CM_ SG_ 2566658558 TotalHaulCycleCount "The total accumulated number of haul cycles over the life of the product.
This should be a monotonically increasing number that sums Haul Cycle Count (SPN 6847). If transactions are supported via Payload Delivery Transaction Status (SPN 7702) then ...";
CM_ SG_ 2566658558 TotalDeliveredPayloadWeight "The accumulated delivered payload mass over the life of the product.
This should be a monotonically increasing number that sums delivered payload weights (SPN 6849) If transactions are supported (Payload Delivery Transaction Status, SPN 7702) then ...";
CM_ BO_ 2566658302 "Payload System Totals 2
Payload measurement system accumulators.";
CM_ SG_ 2566658302 TotalPayloadTransactionCount "The accumulated number of completed payload delivery transactions over the life of the product.
If transaction status monitoring is supported via Payload Delivery Transaction Status (SPN 7702) then total payload transaction count may increment when ...";
CM_ BO_ 2499549182 "Payload Temperature 1
Payload temperatures";
CM_ BO_ 2499548926 "Payload Temperature 2
Payload temperatures";
CM_ BO_ 2499548670 "Vehicle Electrical Power 6
Voltage and current measurements for batteries 3 and 4.";
CM_ BO_ 2499548158 "Door Latch Status
This message provides status of the cabin door  latches. Doors are numbered left to right, front to back.";
CM_ SG_ 2499548158 RightRearCabDoorLatchPos "Status of the right rear cab door latch. Door latches may have 3 positions indicating fully open, 1st detent or 'ajar', and 2nd detent or fully closed.
000 = Door Latch Open
001 = Door Latch Fully Closed/Latched
010 = Door Latch Ajar
011 = ...";
CM_ SG_ 2499548158 LeftRearCabDoorLatchPos "Status of the left rear cab door latch. Door latches may have 3 positions indicating fully open, 1st detent or 'ajar', and 2nd detent or fully closed.
000 = Door Latch Open
001 = Door Latch Fully Closed/Latched
010 = Door Latch Ajar
011 = ...";
CM_ SG_ 2499548158 RightFrontCabDoorLatchPos "Status of the right front cab door latch (passenger door for left-hand steer vehicles). Door latches may have 3 positions indicating fully open, 1st detent or 'ajar', and 2nd detent or fully closed.
000 = Door Latch Open
001 = Door Latch Fully ...";
CM_ SG_ 2499548158 LeftFrontCabDoorLatchPos "Status of the left front cab door latch (driver door for left-hand steer vehicles). Door latches may have 3 positions indicating fully open, 1st detent or 'ajar', and 2nd detent or fully closed.
000 = Door Latch Open
001 = Door Latch Fully ...";
CM_ BO_ 2499547902 "Cab Door Control
This message requests or commands the cabin door functionality; door latches, windows, and mirrors. Doors are numbered left to right, front to back.";
CM_ SG_ 2499547902 MirrorRight2HeatCmd "Command to activate heater for second mirror on the right side (passenger side for left-hand steer vehicle).  Mirror heat may be expected to latch in the 'on' state upon receipt of the command, stay on while the command is 'take no action' and turn ...";
CM_ SG_ 2499547902 MirrorLeft2HeatCmd "Command to activate heater for second mirror on the left side (driver side for left-hand steer vehicle).  Mirror heat may be expected to latch in the 'on' state upon receipt of the command, stay on while the command is 'take no action' and turn off ...";
CM_ SG_ 2499547902 MirrorRight1HeatCmd "Command to activate heater for primary mirror on the right side (passenger side for left-hand steer vehicle).  Mirror heat may be expected to latch in the 'on' state upon receipt of the command, stay on while the command is 'take no action' and turn ...";
CM_ SG_ 2499547902 MirrorLeft1HeatCmd "Command to activate heater for primary mirror on the left side (driver side for left-hand steer vehicle).  Mirror heat may be expected to latch in the 'on' state upon receipt of the command, stay on while the command is 'take no action' and turn off ...";
CM_ SG_ 2499547902 MirrorRight2VerticalCmd "Commands vertical position change of the second mirror on the right side (passenger side for lefthand steer vehicles).

00 = Move up
01 = Move down
10 = Reserved
11 = Take no action";
CM_ SG_ 2499547902 MirrorRight2HorizontalCmd "Commands horizontal position change of the second mirror on the right side (passenger side for lefthand steer vehicles).

00 = Move left
01 = Move right
10 = Reserved
11 = Take no action";
CM_ SG_ 2499547902 MirrorLeft2VerticalCmd "Commands vertical position change of the second mirror on the left side (driver side for left-hand steer vehicles). 

00 = Move up
01 = Move down
10 = Reserved
11 = Take no action";
CM_ SG_ 2499547902 MirrorLeft2HorizontalCmd "Commands horizontal position change of the second mirror on the left side (driver side for left-hand steer vehicles).

00 = Move left
01 = Move right
10 = Reserved
11 = Take no action";
CM_ SG_ 2499547902 MirrorRight1VerticalCmd "Commands vertical position change of the primary mirror on the right side (passenger side for lefthand steer vehicles).

00 = Move up
01 = Move down
10 = Reserved
11 = Take no action";
CM_ SG_ 2499547902 MirrorRight1HorizontalCmd "Commands horizontal position change of the primary mirror on the right side (passenger side for lefthand steer vehicles).

00 = Move left
01 = Move right
10 = Reserved
11 = Take no action";
CM_ SG_ 2499547902 MirrorLeft1VerticalCmd "Commands vertical position change of the primary mirror on the left side (driver side for left-hand steer vehicles).

00 = Move up
01 = Move down
10 = Reserved
11 = Take no action";
CM_ SG_ 2499547902 MirrorLeft1HorizontalCmd "Commands horizontal position change of the primary mirror on the left side (driver side for left-hand steer vehicles).

00 = Move left
01 = Move right
10 = Reserved
11 = Take no action";
CM_ SG_ 2499547902 RightRearWindowPosCmd "Commands position change of the right rear window.

000 = Window move up
001 = Window move down
010 = Window auto up
011 = Window auto down
100 = Reserved
101 = Reserved
110 = Reserved
111 = Take no action";
CM_ SG_ 2499547902 LeftRearWindowPosCmd "Commands position change of left rear window.

000 = Window move up
001 = Window move down
010 = Window auto up
011 = Window auto down
100 = Reserved
101 = Reserved
110 = Reserved
111 = Take no action";
CM_ SG_ 2499547902 RightFrontWindowPosCmd "Commands position change of right front window (passenger door window on left-hand steer vehicles).
000 = Window move up
001 = Window move down
010 = Window auto up
011 = Window auto down
100 = Reserved
101 = Reserved
110 = Reserved
111 = ...";
CM_ SG_ 2499547902 LeftFrontWindowPosCmd "Commands position change of left front window (driver door window on left-hand steer vehicles).
000 = Window move up
001 = Window move down
010 = Window auto up
011 = Window auto down
100 = Reserved
101 = Reserved
110 = Reserved
111 = Take ...";
CM_ SG_ 2499547902 RemoteCabDoorLockReq "Request to the cab door lock controller from Remote Keyless Entry or or other external device to lock or unlock doors.
This parameter is different from Cab Doors Lock Actuation Command (SPN xxxx) because this is a request to actuate door locks ...";
CM_ SG_ 2499547902 DoorsLockActCmd "Commands cab door latch state change: lock or unlock.
000 = Unlock left front cab door latch (driver door on LH steer vehicles)
001 = Unlock right front cab door latch (front passenger door for LH steer vehicles)
010 = Unlock left rear cab door ...";
CM_ BO_ 2566656510 "Total Gaseous Fuel Information
Reports the total fuel information of systems using gaseous fuel.";
CM_ SG_ 2566656510 EngTotalGasIdleFuelVolumeUsed "Accumulated volume of engine gaseous fuel used during vehicle operation under idle conditions, in standard cubic meters.";
CM_ SG_ 2566656510 EngTotalGasFuelVolumeUsed "Accumulated volume of engine gaseous fuel used during vehicle operation, in standard cubic meters.

See SPN 1040 for alternate units.";
CM_ BO_ 2565929214 "Advanced Driver Assistance Systems Interface Specification 3
Refer to ADASIS for specific message and parameter definitions. See the ADASIS1  (PGN xxx) for more information.";
CM_ BO_ 2565928958 "Advanced Driver Assistance Systems Interface Specification 2
Refer to ADASIS for specific message and parameter  definitions. See ADASIS1 (PGN 61686) for more information.";
CM_ BO_ 2565928702 "Advanced Driver Assistance Systems Interface Specification 1
Advanced Driver Assistance Systems Interface Specification (ADASIS) defines parameters that describe the upcoming vehicle's environment, including the attributes about the current ...";
CM_ BO_ 2431710718 "Engine Start Arbitrator
Message from the engine start arbitrator, used to manage engine starts.
Default broadcast rate of 20 ms unless the arbitrator is transmitting Engine Start Control Message Rate (SPN 7752) indicating a switch to 250 ms or on ...";
CM_ SG_ 2431710718 Checksum "Checksum to allow detection of data integrity issues. The receiving node shall calculate the checksum and compare its calculated value with the received checksum. In case of a mismatch the message shall be discarded.
The message checksum is ...";
CM_ SG_ 2431710718 MessageCounter "Message counter to allow detection of data integrity issues. The counter is incremented every time a device sends out the Engine Start Control message. When the counter has reached a value of 15 it starts over at 0 for the next message cycle ...";
CM_ SG_ 2431710718 AutomaticEngStartConsentSummary "Arbitrator's summary of the consent statuses of all devices which the arbitrator considers for automatic start requests. The purpose of this parameter is for requesters to determine if an automatic start request would be honored at the current time.
 ...";
CM_ SG_ 2431710718 OpEngStartConsentSummary "Arbitrator's summary of the consent statuses of all devices which the arbitrator considers for operator start requests. The purpose of this parameter is for requesters to determine if an operator start request would be honored at the current time.
 ...";
CM_ SG_ 2431710718 ReqLatchStatus "Indicates the arbitrator's latch status for engine start requests. All 'unlatched' states shall transition to state '0 - Start Request not received' after 1000 ms unless a different state becomes more appropriate in the meantime. While this time may ...";
CM_ SG_ 2431710718 StarterCmd "Command from the arbitrator to the engine starter controller(s).
The arbitrator takes input from consenters and requesters to initiate an engine start. This signal is used by the arbitrator to command the first or second starter instance.
Starter ...";
CM_ SG_ 2431710718 CtrlMessageRate "This signal is sent by the arbitrator to control the rate at which other participants send the Engine Start Control Message (ENGSC). The arbitrator sets this signal to the slower rate after the first engine start attempt after initial power-up is ...";
CM_ BO_ 2431708670 "Engine Start Control
Message used to manage engine starts.
Default broadcast rate of 20 ms unless the sending  device has received Engine Start Control Message Rate (SPN 7752j) from the engine start arbitrator indicating a  switch to 250 ms or on ...";
CM_ SG_ 2431708670 Checksum "Checksum to allow detection of data integrity issues. The receiving node shall calculate the checksum and compare its calculated value with the received checksum. In case of a mismatch the message shall be discarded.
The message checksum is ...";
CM_ SG_ 2431708670 MessageCounter "Message counter to allow detection of data integrity issues. The counter is incremented every time a device sends out the Engine Start Control message. When the counter has reached a value of 15 it starts over at 0 for the next message cycle ...";
CM_ SG_ 2431708670 Starter2Feedback "Feedback of the current state of second engine starter. This signal is intended to be used by the arbitrator as feedback to its command signal (SPN 7753).
Additional details regarding the starter state may be available in SPN 1675.
000 = Starter ...";
CM_ SG_ 2431708670 Starter1Feedback "Feedback of the current state of first engine starter. This signal is intended to be used by the arbitrator as feedback to its command signal (SPN 7753).
Additional details regarding the starter state may be available in SPN 1675.
000 = Starter ...";
CM_ SG_ 2431708670 AbortReq "Indicates the sender's desire to abort an engine start. This signal is used by requesters and consenters to request that the arbitrator cancel an engine start that is in progress.
The sender of this signal may increase the broadcast rate ...";
CM_ SG_ 2431708670 Consent "Indicates the sender's consent to start the engine for different start types. An operator-requested engine start is a start that is initiated directly by the operator (i.e. via the key switch). An automatic engine start is one that is initiated by a ...";
CM_ SG_ 2431708670 Req "Indicates the sender's desire to start the engine. The engine start arbitrator latches this signal and, if possible, completes the engine start regardless of a change of state of this signal. Use Engine Start Abort Request (SPN 7747) to un-latch the ...";
CM_ BO_ 2566661118 "Fuel Consumption (Liquid) 2
Engine fuel consumption accumulators.";
CM_ SG_ 2566661118 EngTotalDieselFuelDemand "Accumulated amount of liquid fuel that would have been used during engine operation, including actual diesel fuel used and the diesel fuel that was displaced by gaseous fuel.

This is the cumulative value of SPN 7596.";
CM_ BO_ 2633769726 "Electronic Engine Controller 19
Engine related parameters";
CM_ SG_ 2633769726 TotalEngEnergy "The total amount of energy delivered by the engine. It is accumulated over the life of the engine.";
CM_ BO_ 2565926142 "Aftertreatment 2 Outlet Sensor 2
The purpose of this PGN is to group the aftertreatment outlet sensor data for bank 2.  These values include the NOx, %O2, status of the sensors with respect to the power being supplied and the heating element, ...";
CM_ SG_ 2565926142 O2Snsr2PreliminaryFMI "Used to identify the applicable J1939-73 FMI detected in the aftertreatment outlet oxygen second sensor by the manufacturer's sensor control software in exhaust bank 2.  When there is no failure FMI 31 is sent.  In the case of multiple failures the ...";
CM_ SG_ 2565926142 NOxSnsr2SelfDiagStatus "Self-diagnosis result status for second NOx sensor ATO2 (Aftertreatment Outlet Bank 2)
000 Diagnosis not active
001 NOx Sensor ATO2 Self Diagnosis active flag
010 NOx Sensor ATO2 Self Diagnosis Result Complete
011 NOx Sensor ATO2 Self Diagnosis ...";
CM_ SG_ 2565926142 NOxSnsr2PreliminaryFMI "Used to identify the applicable J1939-73 FMI detected in the aftertreatment outlet NOx second sensor by the manufacturer's sensor control software in exhaust bank 2.  When there is no failure FMI 31 is sent.  In the case of multiple failures the ...";
CM_ SG_ 2565926142 GasSnsr2HtrCtrl "Indicates the heater status in the warm-up process.  Upon receiving a power-up command, the gas second sensor ramps up according to a manufacturer defined profile.  The Preheat 1, Preheat 2, and Automatic messages are regions within this profile in ...";
CM_ SG_ 2565926142 GasSnsr2HtrPreliminaryFMI "Used to identify the applicable J1939-73 FMI detected in the heater of the outlet exhaust gas second sensor, either NOx or O2, by the manufacturer's sensor control software in exhaust bank 2.  When there is no failure FMI 31 is sent.  In the case of ...";
CM_ SG_ 2565926142 WRPercentO22ReadingStable "Indicates that the percent oxygen reading of the aftertreatment outlet gas second sensor, either NOx or O2, is stable as determined by the manufacturer's control software in exhaust bank 2.
For a single exhaust bank system, refer to parameters in ...";
CM_ SG_ 2565926142 NOx2ReadingStable "Indicates that the NOx reading of the aftertreatment outlet NOx second sensor is stable as determined by the manufacturer's control software in exhaust bank 2.
For a single exhaust bank system, refer to parameters in PGNs 61454, 61455, 64946, ...";
CM_ SG_ 2565926142 GasSnsr2AtTemp "Indicates that the heater element of the aftertreatment outlet gas second sensor, either NOx or O2, is within the manufacturer's specified range for accurate measurements in exhaust bank 2.
For a single exhaust bank system, refer to parameters in ...";
CM_ SG_ 2565926142 GasSnsr2PwrInRange "Indicates that the power supplied to the aftertreatment outlet gas second sensor, either NOx or O2, is within the manufacturer's specification in exhaust bank 2.
For a single exhaust bank system, refer to parameters in PGNs 61454, 61455, 64946, ...";
CM_ SG_ 2565926142 PercentO22 "The actual oxidation factor (percent oxygen) of the gas within the exhaust stream.  For positive values, the parameter represents the percent oxygen in excess of the amount required for stoichiometric combustion.  For negative values, the parameter ...";
CM_ SG_ 2565926142 NOx2 "The amount of combined NO and NO2 in the exhaust entering the aftertreatment system measured by the second NOx sensor at the aftertreatment outlet, represented in NOx molecule parts per million non-NOx molecules in exhaust bank 2.
For a single ...";
CM_ BO_ 2565925886 "Aftertreatment 2 Intake Sensor 2
The purpose of this PGN is to group the aftertreatment intake sensor data for bank 2.  These values include the NOx, %O2, status of the sensors with respect to the power being supplied and the heating element, ...";
CM_ SG_ 2565925886 O2Snsr2PreliminaryFMI "Used to identify the applicable J1939-73 FMI detected in the aftertreatment intake oxygen second sensor by the manufacturer's sensor control software in exhaust bank 2.  When there is no failure FMI 31 is sent.  In the case of multiple failures the ...";
CM_ SG_ 2565925886 NOxSnsr2SelfDiagStatus "Self-diagnosis result status for NOx second sensor ATI2 (Aftertreatment Intake Bank 2)
000 Diagnosis not active
001 NOx Sensor ATI2 Self Diagnosis active flag
010 NOx Sensor ATI2 Self Diagnosis Result Complete
011 NOx Sensor ATI2 Self Diagnosis ...";
CM_ SG_ 2565925886 SCRInNOxSnsr2PreliminaryFMI "Used to identify the applicable J1939-73 FMI detected in the aftertreatment intake NOx second sensor by the manufacturer's sensor control software in exhaust bank 2.  When there is no failure FMI 31 is sent.  In the case of multiple failures the ...";
CM_ SG_ 2565925886 GasSnsr2HtrCtrl "Indicates the heater status in the warm-up process.  Upon receiving a power-up command, the second gas sensor ramps up according to a manufacturer defined profile.  The Preheat 1, Preheat 2, and Automatic messages are regions within this profile in ...";
CM_ SG_ 2565925886 GasSnsr2HtrPreliminaryFMI "Used to identify the applicable J1939-73 FMI detected in the heater of the intake exhaust gas second sensor, either NOx or O2, by the manufacturer's sensor control software in exhaust bank 2.  When there is no failure FMI 31 is sent.  In the case of ...";
CM_ SG_ 2565925886 WRPercentO22ReadingStable "Indicates that the percent oxygen reading of the aftertreatment intake gas second sensor, either NOx or O2, is stable as determined by the manufacturer's control software in exhaust bank 2.
For a single exhaust bank system, refer to parameters in ...";
CM_ SG_ 2565925886 SCRInNOx2ReadingStable "Indicates that the NOx reading of the aftertreatment intake NOx second sensor is stable as determined by the manufacturer's control software in exhaust bank 2.
For a single exhaust bank system, refer to parameters in PGNs 61454, 61455, 64946, ...";
CM_ SG_ 2565925886 GasSnsr2AtTemp "Indicates that the heater element of the aftertreatment intake gas second sensor, either NOx or O2, is within the manufacturer's specified range for accurate measurements in exhaust bank 2.
For a single exhaust bank system, refer to parameters in ...";
CM_ SG_ 2565925886 GasSnsr2PwrInRange "Indicates that the power supplied to the aftertreatment intake gas second sensor, either NOx or O2, is within the manufacturer's specification in exhaust bank 2.
For a single exhaust bank system, refer to parameters in PGNs 61454, 61455, 64946, ...";
CM_ SG_ 2565925886 PercentO22 "The actual oxidation factor (percent oxygen) of the gas within the exhaust stream.  For positive values, the parameter represents the percent oxygen in excess of the amount required for stoichiometric combustion.  For negative values, the parameter ...";
CM_ SG_ 2565925886 SCRInNOx2 "The amount of combined NO and NO2 in the exhaust entering the aftertreatment system measured by the second NOx sensor at the aftertreatment intake, represented in NOx molecule parts per million non-NOx molecules in exhaust bank 2.
For a single ...";
CM_ BO_ 2565925630 "Aftertreatment 1 Outlet Gas 3
The purpose of this PGN is to group the aftertreatment outlet sensor data for bank 1.  These values include the NOx, %O2, Status of the sensors with respect to the power being supplied and the heating element, errors ...";
CM_ SG_ 2565925630 O2Snsr2PreliminaryFMI "Used to identify the applicable J1939-73 FMI detected in the aftertreatment outlet oxygen second sensor by the manufacturer's sensor control software in exhaust bank 1.  When there is no failure FMI 31 is sent.  In the case of multiple failures the ...";
CM_ SG_ 2565925630 NOxSnsr2SelfDiagStatus "Self-diagnosis result status for NOx second sensor ATO1 (Aftertreatment Outlet Bank 1)
000 Diagnosis not active
001 NOx Sensor ATO1 Self Diagnosis active flag
010 NOx Sensor ATO1 Self Diagnosis Result Complete
011 NOx Sensor ATO1 Self Diagnosis ...";
CM_ SG_ 2565925630 NOxSnsr2PreliminaryFMI "Used to identify the applicable J1939-73 FMI detected in the aftertreatment outlet NOx second sensor by the manufacturer's sensor control software in exhaust bank 1.  When there is no failure FMI 31 is sent.  In the case of multiple failures the ...";
CM_ SG_ 2565925630 Snsr2HtrCtrl "Indicates the heater status in the warm-up process.  Upon receiving a power-up command, the gas second sensor ramps up according to a manufacturer defined profile.  The Preheat 1, Preheat 2, and Automatic messages are regions within this profile in ...";
CM_ SG_ 2565925630 Snsr2HtrPreliminaryFMI "Used to identify the applicable J1939-73 FMI detected in the heater of the outlet exhaust gas second sensor, either NOx or O2, by the manufacturer's sensor control software in exhaust bank 1.  When there is no failure FMI 31 is sent.  In the case of ...";
CM_ SG_ 2565925630 WRPercentO22ReadingStable "Indicates that the percent oxygen reading of the aftertreatment outlet gas second sensor, either NOx or O2, is stable as determined by the manufacturer's control software in exhaust bank 1.
00 - Not stable
01 - Stable
10 - Error
11 - Not ...";
CM_ SG_ 2565925630 NOx2ReadingStable "Indicates that the NOx reading of the aftertreatment outlet NOx second sensor is stable as determined by the manufacturer's control software in exhaust bank 1.

00 - Not stable
01 - Stable
10 - Error
11 - Not available";
CM_ SG_ 2565925630 Snsr2AtTemp "Indicates that the heater element of the aftertreatment outlet gas second sensor, either NOx or O2, is within the manufacturer's specified range for accurate measurements in exhaust bank 1.
00 - Not in range
01 - In range
10 - Error
11 - Not ...";
CM_ SG_ 2565925630 Snsr2PwrInRange "Indicates that the second measurement of power supplied to the aftertreatment outlet gas sensor, either NOx or O2, is within the manufacturer's specification in exhaust bank 1. This parameter reports the status as reported by the sensor.
00 - Not ...";
CM_ SG_ 2565925630 PercentO22 "The second measurement of the actual oxidation factor (percent oxygen) of the gas within the exhaust stream.  For positive values, the parameter represents the percent oxygen in excess of the amount required for stoichiometric combustion.  For ...";
CM_ SG_ 2565925630 NOx2 "The second measurement of the amount of combined NO and NO2 in the exhaust exiting the aftertreatment system measured by a NOx sensor at the aftertreatment outlet, represented in NOx molecule parts per million non-NOx molecules in exhaust bank 1.";
CM_ BO_ 2565925374 "Aftertreatment 1 Intake Gas 3
The purpose of this PGN is to group the aftertreatment intake sensor data for bank 1.  These values include the NOx, %O2, Status of the sensors with respect to the power being supplied and the heating element, errors ...";
CM_ SG_ 2565925374 O2Snsr2PreliminaryFMI "Used to identify the second applicable J1939-73 FMI detected in the aftertreatment intake oxygen sensor by the manufacturer's sensor control software in exhaust bank 1.  When there is no failure FMI 31 is sent.  In the case of multiple failures the ...";
CM_ SG_ 2565925374 NOxSnsr2SelfDiagStatus "Self-diagnosis result status for the second NOx sensor ATI1 (Aftertreatment Intake Bank 1)
000 Diagnosis not active
001 NOx Sensor ATI1 Self Diagnosis active flag
010 NOx Sensor ATI1 Self Diagnosis Result Complete
011 NOx Sensor ATI1 Self ...";
CM_ SG_ 2565925374 SCRInNOxSnsr2PreliminaryFMI "Used to identify the applicable J1939-73 FMI detected in the aftertreatment intake NOx second sensor by the manufacturer's sensor control software in exhaust bank 1.  When there is no failure FMI 31 is sent.  In the case of multiple failures the ...";
CM_ SG_ 2565925374 Snsr2HtrCtrl "Indicates the heater status in the warm-up process.  Upon receiving a power-up command, the second gas sensor ramps up according to a manufacturer defined profile.  The Preheat 1, Preheat 2, and Automatic messages are regions within this profile in ...";
CM_ SG_ 2565925374 Snsr2HtrPreliminaryFMI "Used to identify the second applicable J1939-73 FMI detected in the heater of the intake exhaust gas sensor, either NOx or O2, by the manufacturer's sensor control software in exhaust bank 1.  When there is no failure FMI 31 is sent.  In the case of ...";
CM_ SG_ 2565925374 WRPercentO22ReadingStable "Indicates that the second measurement of the percent oxygen reading of the aftertreatment intake gas sensor, either NOx or O2, is stable as determined by the manufacturer's control software in exhaust bank 1.
00 - Not stable
01 - Stable
10 - ...";
CM_ SG_ 2565925374 SCRInNOx2ReadingStable "Indicates that the NOx reading of the aftertreatment intake NOx second sensor is stable as determined by the manufacturer's control software in exhaust bank 1.

00 - Not stable
01 - Stable
10 - Error
11 - Not available";
CM_ SG_ 2565925374 Snsr2AtTemp "Indicates that the heater element of the aftertreatment intake gas second sensor, either NOx or O2, is within the manufacturer's specified range for accurate measurements in exhaust bank 1.
00 - Not in range
01 - In range
10 - Error
11 - Not ...";
CM_ SG_ 2565925374 Snsr2PwrInRange "Indicates that the second measurement of power supplied to the aftertreatment intake gas sensor, either NOx or O2, is within the manufacturer's specification in exhaust bank 1.  This parameter reports the status as reported by the sensor.
00 - Not ...";
CM_ SG_ 2565925374 PercentO22 "The second measurement of the actual oxidation factor (Percent Oxygen) of the gas within the exhaust stream. For positive values, the parameter represents the percent oxygen in excess of the amount required for stoichiometric combustion. For ...";
CM_ SG_ 2565925374 SCRInNOx2 "The second measurement of the amount of combined NO and NO2 in the exhaust entering the aftertreatment system measured by a NOx sensor at the aftertreatment intake, represented in NOx molecule parts per million non-NOx molecules in exhaust bank 1 ...";
CM_ BO_ 2364598526 "Engine Throttle / Fuel Actuator Control Command 2
Used to control networked electronic throttle control actuator and/or fuel control actuator valves.
Otherwise, this PGN can be used to monitor commanded % positioning to electronic throttle control ...";
CM_ SG_ 2364598526 FuelAct4CtrlCmd "The control command to fuel actuator 4, normalized to percent, where 0% represents fully closed and 100% represents fully open.  Typically, this fuel actuator is used to regulate low pressure natural gas flow rate, mixing into the air flow, which ...";
CM_ SG_ 2364598526 FuelAct3CtrlCmd "The control command to fuel actuator 3, normalized to percent, where 0% represents fully closed and 100% represents fully open.  Typically, this fuel actuator is used to regulate low pressure natural gas flow rate, mixing into the air flow, which ...";
CM_ BO_ 2558525182 "Tire Sensor Identification Command
The tire sensor identification number command for each monitored tire.
The command will be used to program sensor identification numbers for individual tire. Since there are multiple tire sensors to report, the ...";
CM_ SG_ 2558525182 Num7586 "The identification number of tire sensor for the tire specified in the tire sensor tire number (SPN 7584) or tire sensor location (SPN 7585).";
CM_ SG_ 2558525182 Location "The location of monitored tire that corresponds with the tire sensor identification number SPN 7586. In order to specify the monitored tire by tire number, use the tire number SPN 7584.
The high order 4 bits indicate the vehicle axle position of ...";
CM_ SG_ 2558525182 Num "The number of the monitored tire that corresponds with the tire sensor identification number SPN 7586. In order to specify the monitored tire by location, use the tire location SPN 7585.

The value 0xFF indicates this SPN is not used.";
CM_ SG_ 2558525182 NumOfTireSensors "Total count of monitored tire sensor identification numbers represented in this instance of the parameter group.";
CM_ BO_ 2350841598 "Alternator Control
Parameters to control the alternator.";
CM_ SG_ 2350841598 TrqRampMaxSpdCmd "The Alternator Torque Ramp Time Command (SPN 7591) is applied if the alternator speed is less than Alternator Torque Ramp Maximum Speed Command (SPN 7592). If the alternator speed is greater than Alternator Torque Ramp Maximum Speed Command, then ...";
CM_ SG_ 2350841598 TrqRampTimeCmd "Sets the torque ramp rate in which the alternator can respond to a change in electrical load. 100% represents the reference engine torque (SPN 544).
This value will be applied if the alternator speed is less than Alternator Torque Ramp Maximum ...";
CM_ SG_ 2350841598 ExcitationMaxCurrentLmt "Command sent to alternator to set the maximum excitation current of the alternator.";
CM_ SG_ 2350841598 SetpointVoltageCmd "Setpoint voltage command to alternator. The setpoint voltage is the point that is regulated by the alternator. This may or may not be the output of the alternator.";
CM_ BO_ 2566838014 "Hybrid System Inputs 1
This message can be sent by any controller that has hybrid system related information.";
CM_ SG_ 2566838014 ShutdownSw "When the operator enables this switch, all hybrid system functionality is disabled including propulsion, regenerative braking, and hybrid powered accessories.  For electric hybrids, the hybrid system shall be placed in an electrically off state ...";
CM_ SG_ 2566838014 PropulsionDisableSw "When the operator enables this switch, the propulsion aspect of hybrid system operation will be disabled.  However, hybrid powered accessories may be on and the engine may still run.  Regenerative braking is allowed unless disabled by SPN 7552 ...";
CM_ SG_ 2566838014 HybrdSystmCstngRgnrtvBrkngLvlSlc "Indicates the coasting regenerative braking level selector position.  Coasting regenerative braking occurs when neither the accelerator nor the brake pedal are depressed.
The coasting regenerative braking level is the position of the driver's ...";
CM_ SG_ 2566838014 HybrdSystmBrkPdlRgnrtvBrkngDsblS "Indicates the brake pedal regenerative braking disable switch position.  This switch allows the operator to disable regenerative braking (e.g. such as during slippery road conditions) that is controlled by brake pedal application.   Regenerative ...";
CM_ SG_ 2566838014 HybrdSystmRgnrtvBrkngDsbleSwitch "Indicates the regenerative braking disable switch position.  This switch gives the operator the ability to disable all regenerative braking from all inputs (e.g. such as during slippery road conditions).
00 = Regenerative Braking Disable Switch is ...";
CM_ SG_ 2566838014 HybrdSystmOffBrdChrgrCnnctnSttus "Indicates the off-board plug-in charger connection status.  One of the uses of this signal is to protect against vehicle motion while a charger is plugged in.
00 = Off-board charger is not connected
01 = Off-board charger is connected
10 = Error
 ...";
CM_ SG_ 2566838014 HybrdSystmPwrElctrncsClntLvlSwtc "Indicates the coolant level switch position in the hybrid system power electronics (e.g. Inverters, DC/DC converters) cooling system.

00 = Coolant Level is not sufficient
01 = Coolant Level is sufficient
10 = Error
11 = Not Available";
CM_ SG_ 2566838014 HybrdSystmPrplsnClantLevelSwitch "Indicates the coolant level switch position in the hybrid system propulsion (e.g. electric motor, generator) cooling system.

00 = Coolant Level is not sufficient
01 = Coolant Level is sufficient
10 = Error
11 = Not Available";
CM_ SG_ 2566838014 HybrdSystmPrtctionOverrideSwitch "Indicates the Protection Override switch position.  This switch allows the operator to override hybrid system protection features and failure modes allowing hybrid system to continue to operate if possible.
00 = Not Active
01 = Active
10 = Error
 ...";
CM_ BO_ 2566761726 "Engine Fuel Information
Configuration information for engine fuel system.";
CM_ SG_ 2566761726 EngIdleFuelFlowRateThreshold "A configuration value that indicates the maximum flow rate for engine idle operation.";
CM_ SG_ 2566761726 NmbrOfFlCnsmptnMntrngTransducers "The number of fuel consumption monitoring transducers installed in the fuel consumption monitoring system.";
CM_ BO_ 2566756350 "Fuel Information 3 (Liquid)
Message for reporting information associated with liquid fuel.";
CM_ SG_ 2566756350 EngFuelReturnTemp "The temperature of the fuel flowing through a fuel return line from the engine back to the fuel tank.";
CM_ SG_ 2566756350 EngFuelSupplyTemp "The temperature of the fuel flowing through a fuel supply line from the fuel tank to the engine.";
CM_ BO_ 2566756094 "Fuel Information 2 (Liquid)
Message for reporting information associated with liquid fuel.";
CM_ SG_ 2566756094 EngFuelReturnFlowRate "The rate of fuel flowing through a fuel return line carrying fuel from the engine back to fuel tank.";
CM_ SG_ 2566756094 EngFuelSupplyFlowRate "The rate of fuel flowing through a fuel supply line carrying fuel from the fuel tank to the engine.";
CM_ BO_ 2566687998 "Aftertreatment 1 Particulate Sensor Information 1
This message contains information for the particulate sensor in bank 1 of a 2 bank system or the particulate sensor in a single bank system.

This sensor is downstream of the DPF.";
CM_ SG_ 2566687998 TimeBetweenRegens "This is the time between the last two successful regenerations of the particulate sensor for the current power cycle. This parameter reflects the time when the engine was running, not a duration based on a real time clock. If two successful ...";
CM_ SG_ 2566687998 ActiveAccumulationTime "This is the amount of time since the last successful regeneration completed.  The sensor has been accumulating particulate matter since that time.";
CM_ SG_ 2566687998 RegenSt "Indicates if the particulate sensor regeneration is currently active, and if so, the reason for the regeneration.
0000 - Regeneration is not active
0001 - Regneration is active and has been initiated by request via SPN 6783
0010 - Regeneration is ...";
CM_ SG_ 2566687998 RegenStatus "The status of the most recent attempt of this power cycle to activate the particulate sensor regeneration process. This will not be updated until the regeneration is no longer active, as indicated by SPN 6774.
Power cycle refers to the time that ...";
CM_ SG_ 2566687998 HtrSt "The states of the particulate sensor heater.  The heater will change states from 11 to 10, 10 to 01, and 01 to 00 in a typical heating event.
00 - Heater is in closed loop control
01 - Heater is being held at a specified level
10 - Heater is in ...";
CM_ SG_ 2566687998 Res "This sensor is located in the exhaust stream somewhere after the DPF, but not necessarily immediately after the DPF.  It provides a resistance value that can be used to determine particulate matter in the exhaust stream. The value in this parameter ...";
CM_ BO_ 2566687742 "Aftertreatment 1 Particulate Sensor Information 2
This message contains information for the particulate sensor in bank 1 of a 2 bank system or the particulate sensor in a single bank system.

This sensor is downstream of the DPF.";
CM_ SG_ 2566687742 HtrRes "The resistance of the particulate sensor heater.";
CM_ SG_ 2566687742 MaxRes "This is the maximum resistance that the particulate sensor can measure.";
CM_ SG_ 2566687742 Temp "Temperature of the particulate sensor.";
CM_ SG_ 2566687742 RegenFailedCount "This is the number of times that the particulate sensor regeneration process has been attempted but failed to complete this power cycle.";
CM_ SG_ 2566687742 PwrSupply "State signal which indicates when the Aftertreatment 1 particulate sensor has power applied to it. Note that this is referring to the power supplied to the sensor, not the power supplied to the controller connected to the sensor.
00 - Off
01 - On
 ...";
CM_ SG_ 2566687742 DetectionStatus "Detection status of the particulate sensor
0000 - Initialization for particulate matter detection
0001 - Waiting for dew point (see SPN 6784)
0010 - Particulate matter detection
0011 - Heater is active for particulate sensor regeneration
0100 - ...";
CM_ BO_ 2365348350 "Engine Load Sharing Information
This PGN contains information relating to integrated engine load sharing status values.";
CM_ SG_ 2365348350 EngLoadShareStatus "This signal indicates that the status of an engine load sharing feature.

0000 - Offline
0001 - Master
0010 - Slave
0011 - Loading
0100 - Unloading
0101 -1101 - Reserved
1110 - Error
1111 - Unavailable";
CM_ SG_ 2365348350 EngUnloadStatus "This signal indicates the status of an external request to unload the engine, such as the external unload request switch.

00 - Not Requested
01 - Requested
10 - Error
11 - Not Available";
CM_ BO_ 2566674686 "Turbocharger Information 7
Turbocharger Information";
CM_ SG_ 2566674686 EngTurbo4LubeOilPress "Gage pressure of oil in the lubrication system for the 4th turbocharger.";
CM_ SG_ 2566674686 EngTurbo3LubeOilPress "Gage pressure of oil in the lubrication system for the 3rd turbocharger.";
CM_ SG_ 2566674686 EngTurbo2LubeOilPress "Gage pressure of oil in the lubrication system for the 2nd turbocharger.";
CM_ BO_ 2566674430 "SCR Operator Inducement Information 1
Contains timers that indicate how long specific causes for inducement have been active.";
CM_ SG_ 2566674430 DslExhstFldQalityMalfunctionTime "Indicates the amount of time an error has been active due to detection of low Diesel Exhaust Fluid Quality. This will accumulate over the life of the product and will never be reset.";
CM_ SG_ 2566674430 DieselExhaustFluidTank1EmptyTime "Indicates the time the Diesel Exhaust Fluid Tank 1 Level is indicated as empty. This will accumulate over the life of the product and will never be reset.";
CM_ BO_ 2566674174 "SCR Operator Inducement Information 2
Contains parameters that are related to SCR inducement.";
CM_ SG_ 2566674174 SCROperatorInducementTotalTime "Indicates the time that operator inducement has been active. This will accumulate over the life of the product and will never be reset.";
CM_ SG_ 2566674174 AFTSCRMalfunctionTime "Indicates the amount of time an error condition has been active due to a malfunction in the Aftertreatment SCR system.
The source of the malfunction condition could be a component failure, detection of tampering, or other reason that prevents ...";
CM_ BO_ 2566673406 "Engine Gaseous Leakage Information
Used to transmit the gaseous fuel leakage information determined by the engine monitoring system.";
CM_ SG_ 2566673406 GasLeakageDetection3Press "Pressure measured in gas leakage detection point 3. Measured media is of the gas, meaning it could be air, inert gas, fuel air mixture or charge air mixture, depending on the failure mode detected. The third measurement point is in a separate leak ...";
CM_ SG_ 2566673406 GasLeakageDetection2Press "Pressure measured in gas leakage detection point 2. Measured media is of the gas, meaning it could be air, inert gas, fuel air mixture or charge air mixture, depending on the failure mode detected. The second measurement point is either another ...";
CM_ SG_ 2566673406 GasLeakageDetection1Press "Pressure measured in gas leakage detection point 1. Measured media is of the gas, meaning it could be air, inert gas, fuel air mixture or charge air mixture, depending on the failure mode detected. The measurement point is typically in the engine ...";
CM_ SG_ 2566673406 GasFuelLeakage3Concentration "Percentage of detected gaseous fuel leak compared to the lower explosion limit (LEL). 100% means the measured value is on the lower explosion limit. 0% means no detected gaseous fuel in measurement point. The third measurement point is in a separate ...";
CM_ SG_ 2566673406 GasFuelLeakage2Concentration "Percentage of detected gaseous fuel leak compared to the lower explosion limit (LEL). 100% means the measured value is on the lower explosion limit. 0% means no detected gaseous fuel in measurement point. The second  measurement point is either ...";
CM_ SG_ 2566673406 GasFuelLeakage1Concentration "Percentage of detected gaseous fuel leak compared to the lower explosion limit (LEL). 100% means the measured value is on the lower explosion limit. 0% means no detected gaseous fuel in measurement point. The measurement point is typically in the ...";
CM_ BO_ 2633782014 "Bin Weight and Lift Count
Used to transmit bin weights.

Note:  This PGN is transmitted for as many Bin Instances as exist on the vehicle.";
CM_ SG_ 2633782014 NetBinWeight "Mass of bin contents at most recent unload";
CM_ SG_ 2633782014 BinLiftCount "Increments with each lift, whether or not net bin weight changes.  The count rolls over at data range limit.

The count can be reset using SPN 6898 in PGN 56832.";
CM_ SG_ 2633782014 BinWeighingErrorStatus "Bin weighing error status

0 = No error
1 = Bad lift cycle
2 = Weighing error: bin lifted, not emptied
3 = Weighing error: empty bin lifted, emptied
4 - 14 = Reserved
15 = Not available / not applicable";
CM_ SG_ 2633782014 BinInstance "Gives the instance of the bin on the vehicle whose parameters are transmitted in the remainder of the PGN, with the first or only bin as instance 1.";
CM_ BO_ 2365346302 "Air Suspension Control 7
Used for suspension control information";
CM_ SG_ 2365346302 LiftAxle2Status "Indicates the status of a tag axle 2.  Numbering of lift/tag axles starts at front axle.  SPN 1822 may be used if less detail is acceptable.
000 - Down (tag axle is laden)
001 - Unloading (load is being transferred from the tag axle)
010 - ...";
CM_ SG_ 2365346302 LiftAxle1Status "Indicates the status of a tag axle 1.  Numbering of lift/tag axles starts at front axle.  SPN 1743 may be used if less detail is acceptable.
000 - Down (tag axle is laden)
001 - Unloading (load is being transferred from the tag axle)
010 - ...";
CM_ BO_ 2566672638 "Payload System Status
Status Information for Payload Measurement Systems.
 
This provides the last haul cycle payload information to the operator.";
CM_ SG_ 2566672638 DeliveryTransactionStatus "The current state of the payload delivery transaction.
When a transaction is in progress, a receiving node may monitor Haul Cycle Count (SPN 6847) and Delivered Payload Weight (SPN 6849) in order to track the progress of a transaction, where the ...";
CM_ SG_ 2566672638 DeliveredPayloadConfidence "The level of confidence of the delivered payload weight measurement. Higher confidence values indicate greater probability the delivered payload weight is the actual weight and providing feedback on the potential for improving system accuracy.";
CM_ SG_ 2566672638 DeliveredPayloadWeight "The delivered payload mass during the last haul cycle. This is the amount of material moved and delivered by a machine is a key work cycle parameter.
Delivered payload weight is defined as the last loaded weight less the carry back weight (material ...";
CM_ SG_ 2566672638 HaulModeStatus "The current operating state of the haul cycle.
0000 - Not in Haul Mode
0001 - Loading -- Payload is being added to the machine
0010 - Approaching Loaded -- Machine is near its maximum capacity
0011 - Loaded -- Loading operation has been ...";
CM_ SG_ 2566672638 HaulCycleCount "A counter incremented by 1 with each instance of a new haul cycle, defined as a dump to dump cycle. The counter shall increment from 0 to 64255, rolling over to 0 on the next increment after 64255.";
CM_ BO_ 2566672382 "Payload Weight Sensor Information
Staus Information on each Payload sensor in a payload measurement system";
CM_ SG_ 2566672382 PayloadWeightSensor8Status "Status of the payload system sensor 8 measurement.

00 = Sensor fully functional
01 = Sensor degraded
10 = Error (Sensor failed)
11 = Not available";
CM_ SG_ 2566672382 PayloadWeightSensor7Status "Status of the payload system sensor 7 measurement.

00 = Sensor fully functional
01 = Sensor degraded
10 = Error (Sensor failed)
11 = Not available";
CM_ SG_ 2566672382 PayloadWeightSensor6Status "Status of the payload system sensor 6 measurement.

00 = Sensor fully functional
01 = Sensor degraded
10 = Error (Sensor failed)
11 = Not available";
CM_ SG_ 2566672382 PayloadWeightSensor5Status "Status of the payload system sensor 5 measurement.

00 = Sensor fully functional
01 = Sensor degraded
10 = Error (Sensor failed)
11 = Not available";
CM_ SG_ 2566672382 PayloadWeightSensor4Status "Status of the payload system sensor 4 measurement.

00 = Sensor fully functional
01 = Sensor degraded
10 = Error (Sensor failed)
11 = Not available";
CM_ SG_ 2566672382 PayloadWeightSensor3Status "Status of the payload system sensor 3 measurement.

00 = Sensor fully functional
01 = Sensor degraded
10 = Error (Sensor failed)
11 = Not available";
CM_ SG_ 2566672382 PayloadWeightSensor2Status "Status of the payload system sensor 2 measurement.

00 = Sensor fully functional
01 = Sensor degraded
10 = Error (Sensor failed)
11 = Not available";
CM_ SG_ 2566672382 PayloadWeightSensor1Status "Status of the payload system sensor 1 measurement.

00 = Sensor fully functional
01 = Sensor degraded
10 = Error (Sensor failed)
11 = Not available";
CM_ BO_ 2566672126 "Aftertreatment 1 SCR Dosing System Information 3
This message contains additional  SCR dosing system information for aftertreatment system 1 (or bank 1).";
CM_ SG_ 2566672126 DEFDoser2Temp "The temperature (measured closest to dosing valve) of the second DEF dosing unit for aftertreatment system 1 (exhaust bank 1).";
CM_ SG_ 2566672126 DEFDoser2AbsPress "The SCR doser 2 diesel exhaust fluid absolute pressure (measured closest to dosing valve) for aftertreatment system 1 (exhaust bank 1).";
CM_ SG_ 2566672126 DEFDosingPress "The SCR dosing diesel exhaust fluid gage pressure (measured closest to dosing valve) for aftertreatment system 1 (exhaust bank 1). This is the gage equivalent to SPN 4334.";
CM_ BO_ 2566671870 "Aftertreatment 2 SCR Dosing System Information 3
This message contains additional  SCR dosing system information for aftertreatment system 2 (or bank 2).";
CM_ SG_ 2566671870 DEFDosing2Temp "The temperature (measured closest to dosing valve) of the second DEF dosing unit for aftertreatment system 2 (exhaust bank 2).";
CM_ SG_ 2566671870 DEFDoser2AbsPress "The SCR doser 2 diesel exhaust fluid absolute pressure (measured closest to dosing valve) for aftertreatment system 2 (exhaust bank 2).";
CM_ SG_ 2566671870 DEFDosingPress "The SCR dosing diesel exhaust fluid gage pressure (measured closest to dosing valve) for aftertreatment system 2 (exhaust bank 2). This is the gage equivalent to SPN 4387.";
CM_ BO_ 2566671614 "SCR Operator Inducement Information 3
Contains parameters related to overriding the operator inducement.";
CM_ SG_ 2566671614 TtlNmbrOfSCROprtrIndcmntOvrrdEvn "Indicates total number of operator inducement override events activated throughout the lifetime of engine operation.
This number will remain at the maximum value once it is reached.
See EU Commission directive 2012/46/EU. Appendix 1 Section 5.5 ...";
CM_ SG_ 2566671614 NmbrOfSCROprtrIndcmntOvrrdEvntsR "During an operator inducement event, the operator may be able to override the inducement multiple times. This parameter indicates the remaining number of times that the currently active inducement can be overridden during an operator inducement ...";
CM_ SG_ 2566671614 SCROprtrIndcmntOvrrdTmeRemaining "This parameter is used to indicate the time remaining during an operator inducement override event.  See also SPN 7344 for an alternate SLOT.
When an operator inducement is not active, this parameter indicates the maximum time that an operator ...";
CM_ SG_ 2566671614 SCROprtrInducementOverrideEnable "Indicates if an operator inducement derate is allowed to be overridden.

Note: Inducement override is only allowed under certain conditions approved by EPA/ARB.

00 Override not allowed
01 Override allowed
10 SAE Reserved
11 Not available";
CM_ BO_ 2566671358 "Electronic Engine Controller 17
This message includes some parameters that are used to support PEMS.
Manufacturers that support this PGN shall support both PEMS Engine Fuel Mass Flow Rate (SPN 6893) and Vehicle Fuel Rate (SPN 6894) even if the ...";
CM_ SG_ 2566671358 CylFuelRate "Cylinder fuel rate shall indicate the amount of fuel injected into the cylinder for combustion during the most recent intake stroke of the engine.

NOTE: Cylinder fuel rate shall indicate zero mg/stroke when the engine is not running.";
CM_ SG_ 2566671358 EngExhaustFlowRate "Engine Exhaust Flow Rate shall indicate the measured/calculated exhaust gas mass flow upstream of the aftertreatment system.
Engine Exhaust Flow Rate shall be calculated as the average exhaust flow rate over the last 1000 milliseconds prior to the ...";
CM_ SG_ 2566671358 VehicleFuelRate "Vehicle Fuel Rate shall indicate the amount of fuel consumed by the engine and fuel injected directly into the aftertreatment system per unit of time, in grams per second.
Vehicle Fuel Rate shall be calculated as the sum of the fuel consumed over ...";
CM_ SG_ 2566671358 PEMSEngFuelMassFlowRate "PEMS Engine Fuel Mass Flow Rate shall indicate the amount of fuel consumed by the engine per unit of time (does not include fuel injected directly into the aftertreatment system, but does include fuel injected into the engine cylinders for the ...";
CM_ BO_ 2566671102 "SCR System Cleaning
Contains information about cleaning the SCR system in the aftertreatment system.
If there are aftertreatment systems on two banks, this PGN represents the composite information from both banks.
NOTE: This message will be ...";
CM_ SG_ 2566671102 SCRSystemCleaningForcedStatus "Indicates the forced execution status of SCR system cleaning.
000 Not Active
001 Active - Forced by Switch (See SPN 3696)
010 Active - Forced by Service Tool
011 Reserved for SAE Assignment
100 Reserved for SAE Assignment
101 Reserved for SAE ...";
CM_ SG_ 2566671102 SCRSystmClnngAtmtcIntationConfig "Indicates the configuration of SCR system cleaning automatic initiation.

00 not enabled
01 enabled
10 reserved for SAE assignment
11 not available";
CM_ SG_ 2566671102 SCRSystmClnngInhbtdDTVhclSpdBlwA "Indicates the state of SCR system cleaning inhibition due to the vehicle speed being less than the allowed vehicle speed.
00 not inhibited
01 inhibited
10 reserved for SAE assignment
11 not available
This SPN indicates the reason for the SCR ...";
CM_ SG_ 2566671102 SCRSystmClnngInhbtdDTEngNtWrmdUp "Indicates the state of SCR system cleaning inhibition due to the engine not being warmed up.
00 not inhibited
01 inhibited
10 reserved for SAE assignment
11 not available
This SPN indicates the reason for the SCR system cleaning event not being ...";
CM_ SG_ 2566671102 SCRSystmClnngInhbtdDTPrmnntSystm "Indicates the state of SCR system cleaning inhibition due to a permanent system lockout.
00 not inhibited
01 inhibited
10 reserved for SAE assignment
11 not available
This SPN indicates the reason for the SCR system cleaning event not being ...";
CM_ SG_ 2566671102 SCRSystmClnngInhbtdDTTmprrySystm "Indicates the state of SCR system cleaning inhibition due to a temporary system lockout.
00 not inhibited
01 inhibited
10 reserved for SAE assignment
11 not available
This SPN indicates the reason for the SCR system cleaning event not being ...";
CM_ SG_ 2566671102 SCRSystmClnngInhbtdDTSystmTmeout "Indicates the state of SCR system cleaning inhibition due to a system timeout.
00 not inhibited
01 inhibited
10 reserved for SAE assignment
11 not available
This SPN indicates the reason for the SCR system cleaning event not being initiated or ...";
CM_ SG_ 2566671102 SCRSystmClnngInhbtdDTSystmFltAct "Indicates the state of SCR system cleaning inhibition due to a system fault being active.
00 not inhibited
01 inhibited
10 reserved for SAE assignment
11 not available
This SPN indicates the reason for the SCR system cleaning event not being ...";
CM_ SG_ 2566671102 SCRSystmClnngInhbtdDTLwExhstTemp "Indicates the state of SCR system cleaning inhibition due to the exhaust temperature being too low.  This implies that the SCR system is too cold for cleaning.
00 not inhibited
01 inhibited
10 reserved for SAE assignment
11 not available
This ...";
CM_ SG_ 2566671102 SCRSystmClnngInhbtdDTPrkngBrkNtS "Indicates the state of SCR system cleaning inhibition due to the parking brake being not set.
00 not inhibited
01 inhibited
10 reserved for SAE assignment
11 not available
This SPN indicates the reason for the SCR system cleaning event not ...";
CM_ SG_ 2566671102 SCRSystmClnngInhbtdDTVhclSpdAbvA "Indicates the state of SCR system cleaning inhibition due to the vehicle speed being above an allowed limit.
00 not inhibited
01 inhibited
10 reserved for SAE assignment
11 not available
This SPN indicates the reason for the SCR system cleaning ...";
CM_ SG_ 2566671102 SCRSystmClnngInhbtdDTOtOfNeutral "Indicates the state of SCR system cleaning inhibition due to the accelerator pedal being out of neutral.
00 not inhibited
01 inhibited
10 reserved for SAE assignment
11 not available
This SPN indicates the reason for the SCR system cleaning ...";
CM_ SG_ 2566671102 SCRSystmClnngInhbtdDTAcclPdlOffI "Indicates the state of SCR system cleaning inhibition due to the accelerator pedal being off idle.
00 not inhibited
01 inhibited
10 reserved for SAE assignment
11 not available
This SPN indicates the reason for the SCR system cleaning event not ...";
CM_ SG_ 2566671102 SCRSystmClnngInhbtdDeToPTOActive "Indicates the state of SCR system cleaning inhibition due to the PTO being active.
00 not inhibited
01 inhibited
10 reserved for SAE assignment
11 not available
This SPN indicates the reason for the SCR system cleaning event not being initiated ...";
CM_ SG_ 2566671102 SCRSystmClnngInhbtdDTSrvcBrkActv "Indicates the state of SCR system cleaning inhibition due to the service brake being active.
00 not inhibited
01 inhibited
10 reserved for SAE assignment
11 not available
This SPN indicates the reason for the SCR system cleaning event not being ...";
CM_ SG_ 2566671102 SCRSystmClnngInhbtdDTCltchDsnggd "Indicates the state of SCR system cleaning event inhibition due to the clutch being disengaged.
00 not inhibited
01 inhibited
10 reserved for SAE assignment
11 not available
This SPN indicates the reason for the SCR system cleaning event not ...";
CM_ SG_ 2566671102 SCRSystmClnngInhbtdDTInhbtSwitch "Indicates the state of SCR system cleaning inhibition due to the SCR system cleaning Inhibit Switch.
00 not inhibited
01 inhibited
10 reserved for SAE assignment
11 not available
This SPN indicates the reason for the SCR system cleaning event ...";
CM_ SG_ 2566671102 SCRSystemCleaningInhibitedStatus "Indicates the state of SCR system cleaning inhibition.
00 not inhibited
01 inhibited
10 reserved for SAE assignment
11 not available
This SPN indicates the reason for the SCR system cleaning event not being initiated or being exited prior to ...";
CM_ SG_ 2566671102 SCRSystemCleaningStatus "Indicates the state of SCR system cleaning.  This is an aggregate of bank 1 and bank 2.  It is a system status and not individual bank status.
00 not active
01 active
10 SCR system cleaning is needed - automatically initiated SCR system cleaning ...";
CM_ SG_ 2566671102 SCRSystemCleaningLampCmd "Command to control the SCR system cleaning lamp.
000 Off
001 On - solid
010 reserved for SAE assignment
011 reserved for SAE assignment
100 On - fast blink (1 HZ)
101 reserved for SAE assignment
110 reserved for SAE assignment
111 not ...";
CM_ BO_ 2566670846 "Aftertreatment 1 Historical Information 2
Contains information about the history of the aftertreatment 1 system";
CM_ SG_ 2566670846 SCRSysAvgDistBetweenCleanEvents "Indicates the average distance since last reset between cleaning events for the SCR system in bank 1.

If the manufacturer allows this parameter to be reset, this distance is the average since last reset.";
CM_ SG_ 2566670846 SCRSysAvgTimeBetweenCleanEvents "Indicates the average time since last reset between cleaning events for the SCR system in bank 1.
 
If the manufacturer allows this parameter to be reset, this time is the average since last reset.";
CM_ SG_ 2566670846 SCRSysTotalSysCleanManReq "Total number of manual cleaning requests on the SCR system in bank 1 by the operator over the lifetime of the device.";
CM_ SG_ 2566670846 SCRSysTotalSysCleanInhReq "Total number of cleaning inhibit requests on the SCR system in bank 1 by the operator over the lifetime of the device.";
CM_ SG_ 2566670846 SCRSysTotalSysCleanEvents "Total number of cleaning events that have occurred on the SCR system in bank 1 over the lifetime of the device.";
CM_ SG_ 2566670846 SCRSysTotalCleanTime "Total amount of time that a cleaning event has been active in the SCR system in bank 1 over the lifetime of the device.";
CM_ BO_ 2566670590 "Aftertreatment 2 Historical Information 2
Contains information about the history of the aftertreatment 2 system";
CM_ SG_ 2566670590 SCRSysAvgDistBetweenCleanEvents "Indicates the average distance since last reset between cleaning events for the SCR system in bank 2.

If the manufacturer allows this parameter to be reset, this distance is the average since last reset.";
CM_ SG_ 2566670590 SCRSysAvgTimeBetweenCleanEvents "Indicates the average time since last reset between cleaning events for the SCR system in bank 2.

If the manufacturer allows this parameter to be reset, this time is the average since last reset.";
CM_ SG_ 2566670590 SCRSysTotalSysCleanManReq "Total number of manual cleaning requests on the SCR system in bank 2 by the operator over the lifetime of the device.";
CM_ SG_ 2566670590 SCRSysTotalSysCleanInhReq "Total number of cleaning inhibit requests on the SCR system in bank 2 by the operator over the lifetime of the device.";
CM_ SG_ 2566670590 SCRSysTotalSysCleanEvents "Total number of cleaning events that have occurred on the SCR system in bank 2 over the lifetime of the device.";
CM_ SG_ 2566670590 SCRSysTotalSysCleanTime "Total amount of time that a cleaning event has been active in the SCR system in bank 2 over the lifetime of the device.";
CM_ BO_ 2566670334 "Monitored Tire Information
Used by the tire monitoring system to report the number of tires, number of axles and number of tires on each axle it is monitoring on a specific vehicle. The axle number increments from front to rear of the vehicle per ...";
CM_ SG_ 2566670334 Axle12MonitoredTireCount "The number of tires on Axle 12 which are monitored by the tire monitor controller. The axle number increments from front to rear of the vehicle when facing the vehicle in the forward vehicle travel orientation. If the axle is not monitored by the ...";
CM_ SG_ 2566670334 Axle11MonitoredTireCount "The number of tires on Axle 11 which are monitored by the tire monitor controller. The axle number increments from front to rear of the vehicle when facing the vehicle in the forward vehicle travel orientation. If the axle is not monitored by the ...";
CM_ SG_ 2566670334 Axle10MonitoredTireCount "The number of tires on Axle 10 which are monitored by the tire monitor controller. The axle number increments from front to rear of the vehicle when facing the vehicle in the forward vehicle travel orientation. If the axle is not monitored by the ...";
CM_ SG_ 2566670334 Axle9MonitoredTireCount "The number of tires on Axle 9 which are monitored by the tire monitor controller. The axle number increments from front to rear of the vehicle when facing the vehicle in the forward vehicle travel orientation. If the axle is not monitored by the ...";
CM_ SG_ 2566670334 Axle8MonitoredTireCount "The number of tires on Axle 8 which are monitored by the tire monitor controller. The axle number increments from front to rear of the vehicle when facing the vehicle in the forward vehicle travel orientation. If the axle is not monitored by the ...";
CM_ SG_ 2566670334 Axle7MonitoredTireCount "The number of tires on Axle 7 which are monitored by the tire monitor controller. The axle number increments from front to rear of the vehicle when facing the vehicle in the forward vehicle travel orientation. If the axle is not monitored by the ...";
CM_ SG_ 2566670334 Axle6MonitoredTireCount "The number of tires on Axle 6 which are monitored by the tire monitor controller. The axle number increments from front to rear of the vehicle when facing the vehicle in the forward vehicle travel orientation. If the axle is not monitored by the ...";
CM_ SG_ 2566670334 Axle5MonitoredTireCount "The number of tires on Axle 5 which are monitored by the tire monitor controller. The axle number increments from front to rear of the vehicle when facing the vehicle in the forward vehicle travel orientation. If the axle is not monitored by the ...";
CM_ SG_ 2566670334 Axle4MonitoredTireCount "The number of tires on Axle 4 which are monitored by the tire monitor controller. The axle number increments from front to rear of the vehicle when facing the vehicle in the forward vehicle travel orientation. If the axle is not monitored by the ...";
CM_ SG_ 2566670334 Axle3MonitoredTireCount "The number of tires on Axle 3 which are monitored by the tire monitor controller. The axle number increments from front to rear of the vehicle when facing the vehicle in the forward vehicle travel orientation. If the axle is not monitored by the ...";
CM_ SG_ 2566670334 Axle2MonitoredTireCount "The number of tires on Axle 2 which are monitored by the tire monitor controller. The axle number increments from front to rear of the vehicle when facing the vehicle in the forward vehicle travel orientation. If the axle is not monitored by the ...";
CM_ SG_ 2566670334 Axle1MonitoredTireCount "The number of tires on Axle 1 which are monitored by the tire monitor controller. The axle number increments from front to rear of the vehicle when facing the vehicle in the forward vehicle travel orientation. If the axle is not monitored by the ...";
CM_ SG_ 2566670334 NumberOfTiresOnTheVehicle "The total number of tires monitored for tire parameters. A maximum of 250 tires is defined.";
CM_ SG_ 2566670334 NumberOfAxlesOnTheVehicle "The number of axles monitored for tire parameters. A maximum of 12 axles is defined.";
CM_ BO_ 2566670078 "Tire Sensor Identification Status
The tire sensor identification number for each monitored tire.
Since there are multiple tire sensors to report, the message format will be a,b,c,d,b,c,d,b,c,d,b,c,d,...etc. where
a = Number of Tire Sensors
b = ...";
CM_ SG_ 2566670078 TireSensorIdentificationNumber "The identification number of the tire specified in the tire number (SPN 6964) or tire location (SPN 6965).";
CM_ SG_ 2566670078 TireSensorLocation "The location of monitored tire that corresponds with the Tire Sensor Identification Number (SPN 6966). In order to specify the monitored tire by tire number, use the Tire Number SPN 6964.
The high order 4 bits indicate the vehicle axle position of ...";
CM_ SG_ 2566670078 TireSensorTireNumber "The number of the monitored tire that corresponds with the Tire Sensor Identification Number (SPN 6966).  In order to specify the monitored tire by location, use the Tire Location SPN 6965.

The value 0xFF indicates this SPN is not used.";
CM_ SG_ 2566670078 NumberOfTireSensors "Total count of monitored tire sensor identification numbers represented in this instance of the parameter group.";
CM_ BO_ 2566669822 "Tire Wireless Signal Strength Indicator
The tire wireless signal strength indicator for each monitored tire. If there are multiple tire sensors with multiple antennas to report, the message format will be ...";
CM_ SG_ 2566669822 TrWrelessSignalStrengthIndicator "The wireless signal strength between the tire pressure sensor and the specified antenna, for the tire specified in the tire sensor number or tire sensor Location.";
CM_ SG_ 2566669822 TireLocation "The location of monitored tire on the vehicle.
The high order 4 bits indicate the vehicle axle position of the tire sensor, counting front to back on the vehicle, with the value 0 representing the front axle on the vehicle.
The low order 4 bits ...";
CM_ SG_ 2566669822 TireSensorNumber "The number of the monitored tire sensor that corresponds with the tire wireless signal strength indicator. The location of the numbered tire is reported in the tire sensor location SPN (SPN 6965). The value 0xFF indicates this SPN is not used.";
CM_ SG_ 2566669822 TtalNumberOfTireSensorsMonitored "Total number of tire sensors monitored for the specified antenna in this instance of the parameter group.";
CM_ SG_ 2566669822 AntennaNumber "Number of the antenna used to communicate signal strength of a group of sensors.  If a single antenna is used this will default to 0x01. When multiple antennas are used, the first antenna will have a value of 1, 2nd antenna will be 2, 3rd antenna ...";
CM_ SG_ 2566669822 TotalNumberOfAntennasUsed "Total count of antennas used in the specified vehicle system.";
CM_ BO_ 2566669310 "Tire Configuration Status Information
Details the attributes for the tire monitoring configuration status of the tires.
NOTE – Multiple instances of this message will be required to transmit data for all tire locations.  When reporting data for ...";
CM_ SG_ 2566669310 OverTemp "The temperature above which the over temperature alert will trigger.";
CM_ SG_ 2566669310 OverPressPercentageThreshold "The percentage deviation from the set cold inflation pressure, for the over tire pressure alert.";
CM_ SG_ 2566669310 ExtrmUndrPrssPercentageThreshold "The percentage deviation from the set cold inflation pressure, for the extreme under tire pressure alert.";
CM_ SG_ 2566669310 UnderPressPercentageThreshold "The percentage deviation from the set cold inflation pressure, for the under tire pressure alert.";
CM_ SG_ 2566669310 ColdInflationPress "The cold inflation pressure of the tire. Cold inflation pressure is the default/reference inflation pressure suggested by the manufacturer for a specific tire.";
CM_ SG_ 2566669310 TireLocation "The location of monitored tire on the vehicle.
The high order 4 bits indicate the vehicle axle position of the tire sensor, counting front to back on the vehicle, with the value 0 representing the front axle on the vehicle.
The low order 4 bits ...";
CM_ BO_ 2566669054 "Tire Condition Message 2
Tire Condition Message 2
NOTE – Multiple instances of this message will be required to transmit data for all tire locations.  When reporting data for multiple tire locations, each successive message, which provides data ...";
CM_ SG_ 2566669054 RequiredTirePress "The required tire pressure at which air is contained in cavity formed by tire and rim.

This pressure of the tire is compensated to meet the specific physical environmental conditions (temperature) of the vehicle.";
CM_ SG_ 2566669054 TirePress "Pressure at which air is contained in cavity formed by tire and rim. See SPN 241 for alternate tire pressure with a lower range and coarser resolution.";
CM_ SG_ 2566669054 TireLocation "Identifies which tire is associated with the parametric data in PGN 64578. Refer to SPN 929 for further details and examples. The low order 4 bits represent a position number, counting left to right when facing in the direction of normal vehicle ...";
CM_ BO_ 2566668798 "Alternate Fuel 4";
CM_ SG_ 2566668798 EngFl2InjctorMeteringRail1Press2 "The second pressure of fuel 2 measured by first rail pressure sensor in the primary, or first, metering rail as delivered from the supply pump to the injector metering intake.";
CM_ SG_ 2566668798 EngFel2InjectorMeteringRail2Temp "The temperature of fuel 2 measured by first rail temperature sensor in the metering rail 2 as delivered from the supply pump to the injector metering intake.";
CM_ SG_ 2566668798 EngFel2InjectorMeteringRail1Temp "The temperature of fuel 2 measured by first rail temperature sensor in the primary, or first, metering rail as delivered from the supply pump to the injector metering intake.";
CM_ SG_ 2566668798 EngFl2InjectorMeteringRail2Press "The pressure of fuel 2 measured by first rail pressure sensor in the metering rail 2 as delivered from the supply pump to the injector metering intake.";
CM_ SG_ 2566668798 EngFl2InjectorMeteringRail1Press "The pressure of fuel 2 measured by first rail pressure sensor in the primary, or first, metering rail as delivered from the supply pump to the injector metering intake.";
CM_ BO_ 2566668542 "Engine Hydraulic Fuel 2 Pump Status
Hydraulically driven engine fuel 2 pump messages.";
CM_ SG_ 2566668542 EngFuel2PumpHydPress "Hydraulic pressure in the lines of the hydraulically driven fuel 2 pump.";
CM_ SG_ 2566668542 EngFuel2PumpHydDirectionalValve "Position of hydraulic directional valve to control application of hydraulic oil flow.  0% is no flow to the appliance; 100% is full flow to the appliance.";
CM_ SG_ 2566668542 EngFuel2PumpHydSwashPlateAngle "Position of hydraulic swash plate angle within hydraulic pump.  0% represents the lowest possible flow, 100% represents the maximum flow.";
CM_ SG_ 2566668542 EngFuel2PumpHydFlowCtrlValve "Position of hydraulic pump flow control valve opening; 0% = fully closed, 100% = fully open.";
CM_ BO_ 2566668286 "Engine Turbocharger Control 2
This PGN contains information on turbocharger commands.";
CM_ SG_ 2566668286 EngStagedTurboSolenoidStatus "Current state of the staged turbocharger solenoid, normalized to percent, 0% represents not actuated and 100% represents fully actuated.";
CM_ BO_ 2566668030 "Heat Exchanger Debris Purge Information
Contains information about purging debris from the heat exchanger.";
CM_ SG_ 2566668030 HtExchngerDebrisPurgeApproaching "Status signal which indicates that purging the debris from the heat exchanger is imminent.

00     Not approaching
01     Approaching
10     SAE reserved
11     Not available";
CM_ SG_ 2566668030 HeatExchangerDebrisPurgeStatus "Indicates whether the system is currently purging debris from the heat exchanger.

00    Inactive
01    Active
10    SAE reserved
11    Not available";
CM_ BO_ 2566667774 "Engine End Bearing Temperature 1
Used to transmit temperature values at end bearings for connecting rods in the engine cylinder";
CM_ SG_ 2566667774 EngEndBearing8Temp "Temperature of end bearing of the connecting rod for cylinder 8 on the engine";
CM_ SG_ 2566667774 EngEndBearing7Temp "Temperature of end bearing of the connecting rod for cylinder 7 on the engine";
CM_ SG_ 2566667774 EngEndBearing6Temp "Temperature of end bearing of the connecting rod for cylinder 6 on the engine";
CM_ SG_ 2566667774 EngEndBearing5Temp "Temperature of end bearing of the connecting rod for cylinder 5 on the engine";
CM_ SG_ 2566667774 EngEndBearing4Temp "Temperature of end bearing of the connecting rod for cylinder 4 on the engine";
CM_ SG_ 2566667774 EngEndBearing3Temp "Temperature of end bearing of the connecting rod for cylinder 3 on the engine";
CM_ SG_ 2566667774 EngEndBearing2Temp "Temperature of end bearing of the connecting rod for cylinder 2 on the engine";
CM_ SG_ 2566667774 EngEndBearing1Temp "Temperature of end bearing of the connecting rod for cylinder 1 on the engine";
CM_ BO_ 2566667518 "Engine End Bearing Temperature 2
Used to transmit temperature values at end bearings for connecting rods in the engine cylinder";
CM_ SG_ 2566667518 EngEndBearing16Temp "Temperature of end bearing of the connecting rod for cylinder 16 on the engine";
CM_ SG_ 2566667518 EngEndBearing15Temp "Temperature of end bearing of the connecting rod for cylinder 15 on the engine";
CM_ SG_ 2566667518 EngEndBearing14Temp "Temperature of end bearing of the connecting rod for cylinder 14 on the engine";
CM_ SG_ 2566667518 EngEndBearing13Temp "Temperature of end bearing of the connecting rod for cylinder 13 on the engine";
CM_ SG_ 2566667518 EngEndBearing12Temp "Temperature of end bearing of the connecting rod for cylinder 12 on the engine";
CM_ SG_ 2566667518 EngEndBearing11Temp "Temperature of end bearing of the connecting rod for cylinder 11 on the engine";
CM_ SG_ 2566667518 EngEndBearing10Temp "Temperature of end bearing of the connecting rod for cylinder 10 on the engine";
CM_ SG_ 2566667518 EngEndBearing9Temp "Temperature of end bearing of the connecting rod for cylinder 9 on the engine";
CM_ BO_ 2566667262 "Engine End Bearing Temperature 3
Used to transmit temperature values at end bearings for connecting rods in the engine cylinder";
CM_ SG_ 2566667262 EngEndBearing20Temp "Temperature of end bearing of the connecting rod for cylinder 20 on the engine";
CM_ SG_ 2566667262 EngEndBearing19Temp "Temperature of end bearing of the connecting rod for cylinder 19 on the engine";
CM_ SG_ 2566667262 EngEndBearing18Temp "Temperature of end bearing of the connecting rod for cylinder 18 on the engine";
CM_ SG_ 2566667262 EngEndBearing17Temp "Temperature of end bearing of the connecting rod for cylinder 17 on the engine";
CM_ BO_ 2499558142 "Gaseous Fuel Supply Pressure 1
Used to transmit information on pressures at various points of Gaseous fuel supplied to the engine.";
CM_ SG_ 2499558142 GsFlSpplyShtoffValve2IntakePress "Pressure of gaseous fuel supply measured at shutoff valve 2 in gaseous fuel supply unit. Shutoff valves are used to regulate gaseous fuel supply to engine.";
CM_ SG_ 2499558142 GsFlSpplyShtoffValve1IntakePress "Pressure of gaseous fuel supply measured at shutoff valve 1 in gaseous fuel supply unit. Shutoff valves are used to regulate gaseous fuel supply to engine.";
CM_ SG_ 2499558142 GasFuelSupplyUnitIntakePress "Pressure of gaseous fuel supply measured at the intake of gaseous fuel supply unit. Gaseous fuel valve unit contains block and bleed valves to regulate the flow of gaseous fuel from the plant to engine.

Gas Supply Unit Intake Pressure";
CM_ SG_ 2499558142 EngGasFuelSupplyPress2 "Second gage pressure measurement of gaseous fuel supply to fuel metering device. If only one sensor is used for gas supply pressure measurement, use SPN 159 instead.";
CM_ BO_ 2499557886 "Gaseous Fuel Supply Pressure 2
Used to transmit information on pressures at various points of Gaseous fuel supplied to the engine.";
CM_ SG_ 2499557886 PlantInertGasSupplyOutletPress "Pressure of the purge gas supplied to the engine. Inert gas is used to remove gaseous fuel build-up in the engines and in the fuel supply lines when gaseous fuel is not in operation.";
CM_ SG_ 2499557886 PlantGasFuelSupplyOutletPress "Pressure of the gaseous fuel supplied from the plant room for one or more engines.  Based on the application, plant room will contain fuel tank for gas, vaporizer and heater and cooler compartments.";
CM_ BO_ 2499557630 "Engine Oil Mist Detection Information 1
Used to transmit oil mist information determined by the engine monitoring system";
CM_ SG_ 2499557630 EngOilMist8Concentration "Percentage of detected oil mist in compartment 8 compared to the lower explosion limit (LEL). 100% means the measured value is on the lower explosion limit,whereas 0% means no detected oil mist in the air.";
CM_ SG_ 2499557630 EngOilMist7Concentration "Percentage of detected oil mist in compartment 7 compared to the lower explosion limit (LEL). 100% means the measured value is on the lower explosion limit,whereas 0% means no detected oil mist in the air.";
CM_ SG_ 2499557630 EngOilMist6Concentration "Percentage of detected oil mist in compartment 6 compared to the lower explosion limit (LEL). 100% means the measured value is on the lower explosion limit,whereas 0% means no detected oil mist in the air.";
CM_ SG_ 2499557630 EngOilMist5Concentration "Percentage of detected oil mist in compartment 5 compared to the lower explosion limit (LEL). 100% means the measured value is on the lower explosion limit,whereas 0% means no detected oil mist in the air.";
CM_ SG_ 2499557630 EngOilMist4Concentration "Percentage of detected oil mist in compartment 4 compared to the lower explosion limit (LEL). 100% means the measured value is on the lower explosion limit,whereas 0% means no detected oil mist in the air.";
CM_ SG_ 2499557630 EngOilMist3Concentration "Percentage of detected oil mist in compartment 3 compared to the lower explosion limit (LEL). 100% means the measured value is on the lower explosion limit,whereas 0% means no detected oil mist in the air.";
CM_ SG_ 2499557630 EngOilMist2Concentration "Percentage of detected oil mist in compartment 2 compared to the lower explosion limit (LEL). 100% means the measured value is on the lower explosion limit,whereas 0% means no detected oil mist in the air.";
CM_ SG_ 2499557630 EngOilMist1Concentration "Percentage of detected oil mist in compartment 1 compared to the lower explosion limit (LEL). 100% means the measured value is on the lower explosion limit, whereas 0% means no detected oil mist in the air. This measurement is typically taken in ...";
CM_ BO_ 2499557374 "Engine Oil Mist Detection Information 2
Used to transmit oil mist information determined by the engine monitoring system";
CM_ SG_ 2499557374 EngOilMist10Concentration "Percentage of detected oil mist in compartment 10 compared to the lower explosion limit (LEL). 100% means the measured value is on the lower explosion limit,whereas 0% means no detected oil mist in the air.";
CM_ SG_ 2499557374 EngOilMist9Concentration "Percentage of detected oil mist in compartment 9 compared to the lower explosion limit (LEL). 100% means the measured value is on the lower explosion limit,whereas 0% means no detected oil mist in the air.";
CM_ BO_ 2499557118 "Gaseous Fuel Supply Valve Information
Used to transmit information on valves on the gaseous fuel supply lines.";
CM_ SG_ 2499557118 InertGasSupplyValvePos "Position of inert gas supply valve used to control the flow of inert gas into the engine to purge the system.

0% represents valve fully closed and 100% represents valve fully open.";
CM_ SG_ 2499557118 GasFuelSupplyBleedValve3Pos "Position of bleed valve 3, which is used to control the flow of gaseous fuel through the fuel supply unit. 0% represents valve fully closed and 100% represents valve fully open.";
CM_ SG_ 2499557118 GasFuelSupplyBleedValve2Pos "Position of bleed valve 2, which is used to control the flow of gaseous fuel through the fuel supply unit. 0% represents valve fully closed and 100% represents valve fully open.";
CM_ SG_ 2499557118 GasFuelSupplyBleedValve1Pos "Position of bleed valve 1, which is used to control the flow of gaseous fuel through the fuel supply unit. 0% represents valve fully closed and 100% represents valve fully open.";
CM_ SG_ 2499557118 GasFuelSupplyShutoffValve2Pos "Position of shutoff valve 2, which is used to control the flow of gaseous fuel through the fuel supply unit. 0% represents valve fully closed and 100% represents valve fully open.";
CM_ SG_ 2499557118 GasFuelSupplyShutoffValve1Pos "Position of shutoff valve 1, which is used to control the flow of gaseous fuel through the fuel supply unit. 0% represents valve fully closed and 100% represents valve fully open.";
CM_ BO_ 2566665726 "Aftertreatment 2 Diesel Exhaust Fluid Pump 1 Information
Contains information on diesel exhaust fluid pumps for aftertreatment system 2.";
CM_ SG_ 2566665726 TwoMotorSpd "Rotational speed of the motor driving the second pump for the diesel exhaust fluid used in aftertreatment system 2 (exhaust bank 2).";
CM_ SG_ 2566665726 Htr "Percentage of heating applied to the aftertreatment 2 diesel exhaust fluid pump heater.  A value of 0% means no heating applied, a value of 100% means full heating applied. The diesel exhaust fluid pump heater warms the diesel exhaust fluid in the ...";
CM_ BO_ 2499556606 "Engine Fuel Injector Metering Rail Pressure Information 2
Transmits the rail pressure information as measured by different rail pressure sensors.";
CM_ SG_ 2499556606 EngInjectorMeteringRail2Press2 "The pressure of fuel measured by second rail pressure sensor in the metering rail 2 as delivered from the supply pump to the injector metering intake.";
CM_ SG_ 2499556606 EngInjectorMeteringRail2Press1 "The pressure of fuel measured by first rail pressure sensor in the metering rail 2 as delivered from the supply pump to the injector metering intake.";
CM_ SG_ 2499556606 EngInjectorMeteringRail1Press2 "The pressure of fuel measured by the second rail pressure sensor in the primary, or first, metering rail as delivered from the supply pump to the injector metering intake.";
CM_ SG_ 2499556606 EngInjectorMeteringRail1Press1 "The pressure of fuel measured by first rail pressure sensor in the primary, or first, metering rail as delivered from the supply pump to the injector metering intake.";
CM_ BO_ 2499556350 "Engine Fuel Injector Metering Rail Pressure Information 3
Transmits rail pressure information.";
CM_ SG_ 2499556350 EngInjctrMtringRail2DesiredPress "The desired pressure of fuel in metering rail 2 as delivered from the supply pump to the injector metering intake.";
CM_ SG_ 2499556350 EngInjctrMtringRail1DesiredPress "The desired pressure of fuel in the primary, or first, metering rail as delivered from the supply pump to the injector metering intake.";
CM_ BO_ 2499556094 "Aftertreatment 1 Particulate Sensor Information 3
This message contains information for the particulate sensor in bank 1 of a 2 bank system or the particulate sensor in a single bank system.";
CM_ SG_ 2499556094 HtrPwrSupplyDiagnosticStatus "The value of this parameter is not retained when power is removed from the particulate sensor.
000 - Tests monitored continuously. There are no enable or pause conditions. See Aftertreatment 1 Particulate Sensor Heater Power Supply Preliminary FMI ...";
CM_ SG_ 2499556094 HtrPwrSupplyPreliminaryFMI "Used to identify the applicable J1939-73 FMI detected in the aftertreatment particulate sensor heater power supply by the manufacturer's sensor control software in exhaust bank 1. When there is no failure FMI 31 is sent. In the case of multiple ...";
CM_ SG_ 2499556094 PwrSupplyDiagnosticStatus "The value of this parameter is not retained when power is removed from the particulate sensor.
000 - Tests monitored continuously. There are no enable or pause conditions. See Aftertreatment 1 Particulate Sensor Power Supply Preliminary FMI (SPN ...";
CM_ SG_ 2499556094 PwrSupplyPreliminaryFMI "Used to identify the applicable J1939-73 FMI detected in the aftertreatment particulate sensor power supply by the manufacturer's sensor control software in exhaust bank 1. When there is no failure FMI 31 is sent. In the case of multiple failures ...";
CM_ SG_ 2499556094 InputDiagnosticStatus "The value of this parameter is not retained when power is removed from the particulate sensor.
000 - Tests monitored continuously. There are no enable or pause conditions. See Aftertreatment 1 Particulate Sensor Input Preliminary FMI (SPN 7325) for ...";
CM_ SG_ 2499556094 InputPreliminaryFMI "Used to identify the applicable J1939-73 FMI detected in the aftertreatment particulate sensor input by the manufacturer's sensor control software in exhaust bank 1. When there is no failure FMI 31 is sent. In the case of multiple failures the most ...";
CM_ SG_ 2499556094 HtrLowSideDriverDiagnosticStatus "The value of this parameter is not retained when power is removed from the particulate sensor.
000 - Tests monitored continuously. There are no enable or pause conditions. See Aftertreatment 1 Particulate Sensor Heater Low Side Driver Preliminary ...";
CM_ SG_ 2499556094 HtrLowSideDriverPreliminaryFMI "Used to identify the applicable J1939-73 FMI detected in the aftertreatment particulate sensor heater high side driver by the manufacturer's sensor control software in exhaust bank 1. When there is no failure FMI 31 is sent. In the case of multiple ...";
CM_ SG_ 2499556094 HtrHiSideDriverDiagnosticStatus "The value of this parameter is not retained when power is removed from the particulate sensor.
000 - Tests monitored continuously. There are no enable or pause conditions. See Aftertreatment 1 Particulate Sensor Heater High Side Driver Preliminary ...";
CM_ SG_ 2499556094 HtrHiSideDriverPreliminaryFMI "Used to identify the applicable J1939-73 FMI detected in the aftertreatment particulate sensor heater high side driver by the manufacturer's sensor control software in exhaust bank 1. When there is no failure FMI 31 is sent. In the case of multiple ...";
CM_ BO_ 2566664702 "Aftertreatment System Information
The state of the aftertreatment system.";
CM_ SG_ 2566664702 DEFTankTemp "The derived diesel exhaust fluid tank temperature in applications with multiple temperature sensors in a single tank. The SPN data will be derived from all temperature sensors in the tank.
Note: This SPN can be derived from any of the ...";
CM_ SG_ 2566664702 DEFTankVolume "The derived diesel exhaust fluid tank volume in applications with multiple level sensors in a single tank. The SPN data will be derived from all level sensors in the tank.
Note: This SPN can be derived from any of the aftertreatment tank level ...";
CM_ SG_ 2566664702 DEFHtrCircuitBreaker "The status of the circuit breaker that is used to heat the diesel exhaust fluid.

00 off
01 on
10 error
11 not available";
CM_ SG_ 2566664702 AAT "Temperature of ambient air near the aftertreatment components such as DEF tank and DEF lines.";
CM_ SG_ 2566664702 EngLoadReq "Indicates whether the aftertreatment desires engine load to be applied. This is meant to notify the operator that the aftertreatment is requesting engine load for thermal purposes.
The operator is expected to add load to the engine to satisfy this ...";
CM_ SG_ 2566664702 EngSpdIncreaseReq "Indicates whether the aftertreatment desires engine speed control in order to increase the engine speed. This is meant to notify the operator that the aftertreatment is requesting an increase in engine speed for thermal purposes.
The operator is ...";
CM_ SG_ 2566664702 ActiveRegenInhibitedDueToLowEP "The state of aftertreatment active regeneration inhibition due to low exhaust pressure.
Aftertreatment Regeneration is a process of increasing the temperature at the exhaust and thereby removing the deposits on aftertreatment components such as DPF ...";
CM_ SG_ 2566664702 ThermalManagementStatus "Indicates whether Aftertreatment Thermal Management process is active.
Aftertreatment Thermal Management indicates that the exhaust temperatures have been controlled for the normal functioning of the aftertreatment system - This is not just limited ...";
CM_ BO_ 2633773310 "SCR Operator Inducement Information 4
Contains parameters that are related to SCR inducement.";
CM_ SG_ 2633773310 SCROprtrIndcmntOvrrdTmeRemaining "Used to indicate the time remaining during an operator inducement override event.  When an operator inducement is active this parameter indicates the remaining time that the currently active operator inducement may be overridden.
See also SPN 6878 ...";
CM_ SG_ 2633773310 SCROprtrIndcmntOvrrdRnwlRequired "Indicates the required operator inducement override renewal state.

00 = Not Required
01 = Required
10 = Error
11 = Not Available";
CM_ SG_ 2633773310 SCROpratorInducementOverrideMode "Indicates the functional mode of SCR operator inducement override.
000          Not Available
001          Available - Not Active
010          Active
011          Active Extended
100          Expired
101-110  Not Defined
111          Not ...";
CM_ SG_ 2633773310 SCROprtrIndcmntEmrgncyOvrrdTtlRs "The total number of times the feature, which allows the operator to override the inducement strategies (as described in SPN 6880) during emergencies, such as hurricanes, has been reset.

This counter can not be reset.";
CM_ BO_ 2633773054 "Fire Suppression Agent Status
Represents the status of various agents used for fire
suppression and solutions.";
CM_ SG_ 2633773054 FrSpprssnCmprssdArFmSystmArPress "Compressed Air Foam System (CAFS) air compressor pressure.";
CM_ SG_ 2633773054 FrSuppressionClassBFoamTankLevel "Liquid level of the Class-B foam agent tank.";
CM_ SG_ 2633773054 FrSuppressionClassAFoamTankLevel "Liquid level of the Class-A foam agent tank.";
CM_ SG_ 2633773054 FireSuppressionWaterTankLevel "Liquid level of the fire apparatus water tank.";
CM_ BO_ 2566663934 "Engine Turbocharger Control 3
Contains command signals to Turbocharger Compressor Blowoff, Wastegate, Cylinder Head Bypass
and Throttle Valve actuators.";
CM_ SG_ 2566663934 WastegateAct2MotorCurDis "Command to disable power to motor in wastegate actuator 2 to prevent unnecessary load on the component.

00 - Do Not Disable
01 - Disable
10 - Reserved
11 - Don't Care/Take No Action";
CM_ SG_ 2566663934 CompressorBypassAct2MotorCurDis "Command to disable power to motor in bypass actuator 2 to prevent unnecessary load on the component.

00 - Do Not Disable
01 - Disable
10 - Reserved
11 - Don't Care/Take No Action";
CM_ SG_ 2566663934 CompressorBypassAct1MotorCurDis "Command to disable power to motor in bypass actuator 1 to prevent unnecessary load on the component.

00 - Do Not Disable
01 - Disable
10 - Reserved
11 - Don't Care/Take No Action";
CM_ SG_ 2566663934 EngThrttlVlv1MotorCurrentDisable "Command to disable power to motor in the actuator to prevent unnecessary load on the component.

00 - Do Not Disable
01 - Disable
10 - Reserved
11 - Don't Care/Take No Action";
CM_ SG_ 2566663934 EngCylHdBypssActtr1MtrCrrntDsble "Command to disable power to motor in the actuator to prevent unnecessary load on the component.

00 - Do Not Disable
01 - Disable
10 - Reserved
11 - Don't Care/Take No Action";
CM_ SG_ 2566663934 EngTrbWstgtActtr1MtrCrrntDisable "Command to disable power to motor in the actuator to prevent unnecessary load on the component.

00 - Do Not Disable
01 - Disable
10 - Reserved
11 - Don't Care/Take No Action";
CM_ SG_ 2566663934 EngTrbCmprssrBlwffActtr1MtrCrrnt "Command to disable power to motor in the actuator to prevent unnecessary load on the component.

00 - Do Not Disable
01 - Disable
10 - Reserved
11 - Don't Care/Take No Action";
CM_ BO_ 2566663678 "Alternate Fuel 5
Information on alternate fuel.";
CM_ SG_ 2566663678 EngFl2InjectorMeteringRail1Temp2 "The second temperature of fuel 2 measured by first rail temperature sensor in the primary, or first, metering rail as delivered from the supply pump to the injector metering intake.";
CM_ SG_ 2566663678 LNGTank2VaporPress "Gage pressure of the vapor in the second tank in a multi-tank system.";
CM_ SG_ 2566663678 LNGTank1VaporPress "Gage pressure of the vapor in the first tank in a multi-tank system (or unique tank if single-tank system).";
BA_DEF_  "DBName" STRING ;
BA_DEF_ SG_  "SigType" ENUM  "Default","Range","RangeSigned","ASCII","Discrete","Control","ReferencePGN","DTC","StringDelimiter","StringLength","StringLengthControl","MessageCounter","MessageChecksum";
BA_DEF_ SG_  "GenSigStartValue" INT 0 2147483647;
BA_DEF_ SG_  "GenSigSendType" ENUM  "Cyclic","OnWrite","OnWriteWithRepetition","OnChange","OnChangeWithRepetition","IfActive","IfActiveWithRepetition","NoSigSendType";
BA_DEF_ SG_  "GenSigILSupport" ENUM  "No","Yes";
BA_DEF_ SG_  "GenSigEVName" STRING ;
BA_DEF_ SG_  "SPN" INT 0 524287;
BA_DEF_ BO_  "TpJ1939VarDlc" ENUM  "No","Yes";
BA_DEF_ BO_  "GenMsgStartDelayTime" INT 0 100000;
BA_DEF_ BO_  "GenMsgILSupport" ENUM  "No","Yes";
BA_DEF_ BO_  "GenMsgDelayTime" INT 0 1000;
BA_DEF_ BO_  "GenMsgRequestable" INT 0 1;
BA_DEF_ BO_  "GenMsgSendType" ENUM  "cyclic","NotUsed","NotUsed","NotUsed","NotUsed","NotUsed","NotUsed","IfActive","noMsgSendType";
BA_DEF_ BO_  "VFrameFormat" ENUM  "StandardCAN","ExtendedCAN","reserved","J1939PG";
BA_DEF_ BO_  "GenMsgCycleTime" INT 0 3600000;
BA_DEF_ BO_  "SendOnChange" ENUM  "No","Yes";
BA_DEF_ BU_  "NmStationAddress" INT 0 255;
BA_DEF_ BU_  "NmJ1939IndustryGroup" INT 0 7;
BA_DEF_ BU_  "NmJ1939System" INT 0 127;
BA_DEF_ BU_  "NmJ1939Function" INT 0 255;
BA_DEF_ BU_  "NmJ1939FunctionInstance" INT 0 7;
BA_DEF_ BU_  "NmJ1939ECUInstance" INT 0 3;
BA_DEF_  "SAE_J1939_DA_SpecVersion" STRING ;
BA_DEF_  "SAE_J1939_81_SpecVersion" STRING ;
BA_DEF_  "DatabaseVersion" STRING ;
BA_DEF_  "BusType" STRING ;
BA_DEF_  "ProtocolType" STRING ;
BA_DEF_  "SAE_J1939_75_SpecVersion" STRING ;
BA_DEF_  "SAE_J1939_21_SpecVersion" STRING ;
BA_DEF_  "SAE_J1939_73_SpecVersion" STRING ;
BA_DEF_  "SAE_J1939_71_SpecVersion" STRING ;
BA_DEF_ SG_  "SystemSignalLongSymbol" STRING ;
BA_DEF_DEF_  "DBName" "";
BA_DEF_DEF_  "SigType" "Default";
BA_DEF_DEF_  "GenSigStartValue" 0;
BA_DEF_DEF_  "GenSigSendType" "NoSigSendType";
BA_DEF_DEF_  "GenSigILSupport" "Yes";
BA_DEF_DEF_  "GenSigEVName" "Env@Nodename_@Signame";
BA_DEF_DEF_  "SPN" 0;
BA_DEF_DEF_  "TpJ1939VarDlc" "No";
BA_DEF_DEF_  "GenMsgStartDelayTime" 0;
BA_DEF_DEF_  "GenMsgILSupport" "Yes";
BA_DEF_DEF_  "GenMsgDelayTime" 0;
BA_DEF_DEF_  "GenMsgRequestable" 1;
BA_DEF_DEF_  "GenMsgSendType" "noMsgSendType";
BA_DEF_DEF_  "VFrameFormat" "J1939PG";
BA_DEF_DEF_  "GenMsgCycleTime" 0;
BA_DEF_DEF_  "SendOnChange" "No";
BA_DEF_DEF_  "NmStationAddress" 254;
BA_DEF_DEF_  "NmJ1939IndustryGroup" 0;
BA_DEF_DEF_  "NmJ1939System" 0;
BA_DEF_DEF_  "NmJ1939Function" 0;
BA_DEF_DEF_  "NmJ1939FunctionInstance" 0;
BA_DEF_DEF_  "NmJ1939ECUInstance" 0;
BA_DEF_DEF_  "SAE_J1939_DA_SpecVersion" "";
BA_DEF_DEF_  "SAE_J1939_81_SpecVersion" "";
BA_DEF_DEF_  "DatabaseVersion" "";
BA_DEF_DEF_  "BusType" "";
BA_DEF_DEF_  "ProtocolType" "";
BA_DEF_DEF_  "SAE_J1939_75_SpecVersion" "";
BA_DEF_DEF_  "SAE_J1939_21_SpecVersion" "";
BA_DEF_DEF_  "SAE_J1939_73_SpecVersion" "";
BA_DEF_DEF_  "SAE_J1939_71_SpecVersion" "";
BA_DEF_DEF_  "SystemSignalLongSymbol" "";
BA_ "SAE_J1939_DA_SpecVersion" "2015-01";
BA_ "SAE_J1939_81_SpecVersion" "2012-05";
BA_ "DatabaseVersion" "8.5";
BA_ "BusType" "CAN";
BA_ "ProtocolType" "J1939";
BA_ "SAE_J1939_75_SpecVersion" "2012-05";
BA_ "SAE_J1939_21_SpecVersion" "2006-10";
BA_ "SAE_J1939_73_SpecVersion" "2012-10";
BA_ "SAE_J1939_71_SpecVersion" "2012-10";
BA_ "DBName" "J1939";
BA_ "NmStationAddress" BU_ PowertrainControlModule 90;
BA_ "NmStationAddress" BU_ AtmosphericSensor 89;
BA_ "NmJ1939Function" BU_ AtmosphericSensor 76;
BA_ "NmStationAddress" BU_ SafetyRestraintSystem2 88;
BA_ "NmJ1939Function" BU_ SafetyRestraintSystem2 132;
BA_ "NmJ1939FunctionInstance" BU_ SafetyRestraintSystem2 1;
BA_ "NmStationAddress" BU_ Aftertreatment_2_GasOutlet 87;
BA_ "NmJ1939Function" BU_ Aftertreatment_2_GasOutlet 68;
BA_ "NmJ1939FunctionInstance" BU_ Aftertreatment_2_GasOutlet 1;
BA_ "NmJ1939ECUInstance" BU_ Aftertreatment_2_GasOutlet 1;
BA_ "NmStationAddress" BU_ Aftertreatment_2_GasIntake 86;
BA_ "NmJ1939Function" BU_ Aftertreatment_2_GasIntake 68;
BA_ "NmJ1939FunctionInstance" BU_ Aftertreatment_2_GasIntake 1;
BA_ "NmStationAddress" BU_ DieselPartFilterControl 85;
BA_ "NmJ1939Function" BU_ DieselPartFilterControl 69;
BA_ "NmStationAddress" BU_ Turbocharger 2;
BA_ "NmJ1939Function" BU_ Turbocharger 133;
BA_ "NmStationAddress" BU_ SafetyRestraintSystem1 83;
BA_ "NmJ1939Function" BU_ SafetyRestraintSystem1 132;
BA_ "NmStationAddress" BU_ CabDisplay2 84;
BA_ "NmJ1939Function" BU_ CabDisplay2 60;
BA_ "NmJ1939FunctionInstance" BU_ CabDisplay2 1;
BA_ "NmStationAddress" BU_ Aftertreatment_1_GasOutlet 82;
BA_ "NmJ1939Function" BU_ Aftertreatment_1_GasOutlet 68;
BA_ "NmJ1939ECUInstance" BU_ Aftertreatment_1_GasOutlet 1;
BA_ "NmStationAddress" BU_ Aftertreatment_1_GasIntake 81;
BA_ "NmJ1939Function" BU_ Aftertreatment_1_GasIntake 68;
BA_ "NmStationAddress" BU_ OnBoardDataLogger 251;
BA_ "NmJ1939Function" BU_ OnBoardDataLogger 130;
BA_ "NmStationAddress" BU_ OffBoardDiagnosticTool2 250;
BA_ "NmJ1939Function" BU_ OffBoardDiagnosticTool2 129;
BA_ "NmJ1939FunctionInstance" BU_ OffBoardDiagnosticTool2 1;
BA_ "NmStationAddress" BU_ OffBoardDiagnosticTool1 249;
BA_ "NmJ1939Function" BU_ OffBoardDiagnosticTool1 129;
BA_ "NmStationAddress" BU_ FileServer 248;
BA_ "NmJ1939Function" BU_ FileServer 61;
BA_ "NmStationAddress" BU_ ParkingBrakeController 80;
BA_ "NmJ1939Function" BU_ ParkingBrakeController 9;
BA_ "NmJ1939FunctionInstance" BU_ ParkingBrakeController 1;
BA_ "NmStationAddress" BU_ SeatController2 79;
BA_ "NmJ1939Function" BU_ SeatController2 40;
BA_ "NmJ1939FunctionInstance" BU_ SeatController2 1;
BA_ "NmStationAddress" BU_ FanDriveController 78;
BA_ "NmJ1939Function" BU_ FanDriveController 58;
BA_ "NmStationAddress" BU_ SteeringColumnUnit 77;
BA_ "NmJ1939Function" BU_ SteeringColumnUnit 57;
BA_ "NmStationAddress" BU_ CommunicationUnitRadio 76;
BA_ "NmJ1939Function" BU_ CommunicationUnitRadio 56;
BA_ "NmStationAddress" BU_ CommunicationUnitSatellite 75;
BA_ "NmJ1939Function" BU_ CommunicationUnitSatellite 55;
BA_ "NmStationAddress" BU_ CommunicationUnitCellular 74;
BA_ "NmJ1939Function" BU_ CommunicationUnitCellular 54;
BA_ "NmStationAddress" BU_ PropulsionBatteryCharger 73;
BA_ "NmJ1939Function" BU_ PropulsionBatteryCharger 31;
BA_ "NmStationAddress" BU_ ChassisController2 72;
BA_ "NmJ1939Function" BU_ ChassisController2 52;
BA_ "NmJ1939FunctionInstance" BU_ ChassisController2 1;
BA_ "NmStationAddress" BU_ ChassisController1 71;
BA_ "NmJ1939Function" BU_ ChassisController1 52;
BA_ "NmStationAddress" BU_ EngineValveControl 70;
BA_ "NmJ1939Function" BU_ EngineValveControl 63;
BA_ "NmStationAddress" BU_ AuxiliaryHeater2 69;
BA_ "NmJ1939Function" BU_ AuxiliaryHeater2 50;
BA_ "NmJ1939FunctionInstance" BU_ AuxiliaryHeater2 1;
BA_ "NmStationAddress" BU_ AuxiliaryHeater1 68;
BA_ "NmJ1939Function" BU_ AuxiliaryHeater1 50;
BA_ "NmStationAddress" BU_ ClutchUnit 67;
BA_ "NmJ1939Function" BU_ ClutchUnit 49;
BA_ "NmStationAddress" BU_ RampControl 66;
BA_ "NmJ1939Function" BU_ RampControl 48;
BA_ "NmStationAddress" BU_ InformationSystem1 65;
BA_ "NmJ1939Function" BU_ InformationSystem1 47;
BA_ "NmStationAddress" BU_ SuspensionSystemController2 64;
BA_ "NmJ1939Function" BU_ SuspensionSystemController2 35;
BA_ "NmJ1939FunctionInstance" BU_ SuspensionSystemController2 1;
BA_ "NmStationAddress" BU_ OilSensor 63;
BA_ "NmJ1939Function" BU_ OilSensor 46;
BA_ "NmStationAddress" BU_ VehicleDynamicStability 62;
BA_ "NmJ1939Function" BU_ VehicleDynamicStability 45;
BA_ "NmStationAddress" BU_ ExhaustEmissionController 61;
BA_ "NmJ1939Function" BU_ ExhaustEmissionController 44;
BA_ "NmStationAddress" BU_ TransmissionDisplay2 60;
BA_ "NmJ1939Function" BU_ TransmissionDisplay2 43;
BA_ "NmJ1939FunctionInstance" BU_ TransmissionDisplay2 1;
BA_ "NmStationAddress" BU_ TransmissionDisplay1 59;
BA_ "NmJ1939Function" BU_ TransmissionDisplay1 43;
BA_ "NmStationAddress" BU_ ClimateControl2 58;
BA_ "NmJ1939Function" BU_ ClimateControl2 21;
BA_ "NmJ1939FunctionInstance" BU_ ClimateControl2 1;
BA_ "NmStationAddress" BU_ WaterPumpController 57;
BA_ "NmJ1939Function" BU_ WaterPumpController 42;
BA_ "NmStationAddress" BU_ RearAxleSteeringController 56;
BA_ "NmJ1939Function" BU_ RearAxleSteeringController 16;
BA_ "NmJ1939FunctionInstance" BU_ RearAxleSteeringController 1;
BA_ "NmStationAddress" BU_ LightingOperatorControl 55;
BA_ "NmJ1939Function" BU_ LightingOperatorControl 41;
BA_ "NmStationAddress" BU_ SeatController1 54;
BA_ "NmJ1939Function" BU_ SeatController1 40;
BA_ "NmStationAddress" BU_ IgnitionController2 53;
BA_ "NmJ1939Function" BU_ IgnitionController2 39;
BA_ "NmJ1939FunctionInstance" BU_ IgnitionController2 1;
BA_ "NmStationAddress" BU_ IgnitionController1 52;
BA_ "NmJ1939Function" BU_ IgnitionController1 39;
BA_ "NmStationAddress" BU_ TirePressureController 51;
BA_ "NmJ1939Function" BU_ TirePressureController 38;
BA_ "NmStationAddress" BU_ CabController2 50;
BA_ "NmJ1939Function" BU_ CabController2 37;
BA_ "NmJ1939FunctionInstance" BU_ CabController2 1;
BA_ "NmStationAddress" BU_ CabController1 49;
BA_ "NmJ1939Function" BU_ CabController1 37;
BA_ "NmStationAddress" BU_ PneumaticSystemController 48;
BA_ "NmJ1939Function" BU_ PneumaticSystemController 36;
BA_ "NmStationAddress" BU_ SuspensionSystemController1 47;
BA_ "NmJ1939Function" BU_ SuspensionSystemController1 35;
BA_ "NmStationAddress" BU_ HydraulicPumpController 46;
BA_ "NmJ1939Function" BU_ HydraulicPumpController 34;
BA_ "NmStationAddress" BU_ EnduranceBrakingSystem 45;
BA_ "NmJ1939Function" BU_ EnduranceBrakingSystem 64;
BA_ "NmStationAddress" BU_ RetarderExhaustEngine2 44;
BA_ "NmJ1939Function" BU_ RetarderExhaustEngine2 12;
BA_ "NmJ1939FunctionInstance" BU_ RetarderExhaustEngine2 1;
BA_ "NmStationAddress" BU_ OnBoardDiagnosticUnit 43;
BA_ "NmJ1939Function" BU_ OnBoardDiagnosticUnit 62;
BA_ "NmStationAddress" BU_ HeadwayController 42;
BA_ "NmJ1939Function" BU_ HeadwayController 32;
BA_ "NmStationAddress" BU_ RetarderExhaustEngine1 41;
BA_ "NmJ1939Function" BU_ RetarderExhaustEngine1 12;
BA_ "NmStationAddress" BU_ CabDisplay1 40;
BA_ "NmJ1939Function" BU_ CabDisplay1 60;
BA_ "NmStationAddress" BU_ ManagementComputer 39;
BA_ "NmJ1939Function" BU_ ManagementComputer 30;
BA_ "NmStationAddress" BU_ VirtualTerminal 38;
BA_ "NmJ1939Function" BU_ VirtualTerminal 29;
BA_ "NmStationAddress" BU_ OffVehicleGateway 37;
BA_ "NmJ1939Function" BU_ OffVehicleGateway 28;
BA_ "NmStationAddress" BU_ PowerTakeOffFront 36;
BA_ "NmJ1939Function" BU_ PowerTakeOffFront 27;
BA_ "NmStationAddress" BU_ HitchControl 35;
BA_ "NmStationAddress" BU_ AuxiliaryValveControl 34;
BA_ "NmJ1939IndustryGroup" BU_ AuxiliaryValveControl 2;
BA_ "NmJ1939System" BU_ AuxiliaryValveControl 1;
BA_ "NmJ1939Function" BU_ AuxiliaryValveControl 129;
BA_ "NmStationAddress" BU_ BodyController 33;
BA_ "NmJ1939Function" BU_ BodyController 26;
BA_ "NmStationAddress" BU_ TractorTrailerBridge1 32;
BA_ "NmJ1939Function" BU_ TractorTrailerBridge1 25;
BA_ "NmStationAddress" BU_ StarterSystem 31;
BA_ "NmJ1939Function" BU_ StarterSystem 59;
BA_ "NmStationAddress" BU_ ElectricalSystem 30;
BA_ "NmJ1939Function" BU_ ElectricalSystem 67;
BA_ "NmStationAddress" BU_ VehicleSecurity 29;
BA_ "NmJ1939Function" BU_ VehicleSecurity 24;
BA_ "NmStationAddress" BU_ VehicleNavigation 28;
BA_ "NmJ1939Function" BU_ VehicleNavigation 23;
BA_ "NmStationAddress" BU_ AerodynamicControl 27;
BA_ "NmJ1939Function" BU_ AerodynamicControl 22;
BA_ "NmStationAddress" BU_ ElectricalChargingSystem 26;
BA_ "NmJ1939Function" BU_ ElectricalChargingSystem 53;
BA_ "NmStationAddress" BU_ ClimateControl1 25;
BA_ "NmJ1939Function" BU_ ClimateControl1 21;
BA_ "NmStationAddress" BU_ TripRecorder 24;
BA_ "NmJ1939Function" BU_ TripRecorder 20;
BA_ "NmStationAddress" BU_ InstrumentCluster 23;
BA_ "NmJ1939Function" BU_ InstrumentCluster 19;
BA_ "NmStationAddress" BU_ SuspensionDriveAxle2 22;
BA_ "NmJ1939Function" BU_ SuspensionDriveAxle2 18;
BA_ "NmJ1939FunctionInstance" BU_ SuspensionDriveAxle2 1;
BA_ "NmStationAddress" BU_ SuspensionDriveAxle1 21;
BA_ "NmJ1939Function" BU_ SuspensionDriveAxle1 18;
BA_ "NmStationAddress" BU_ SuspensionSteerAxle 20;
BA_ "NmJ1939Function" BU_ SuspensionSteerAxle 17;
BA_ "NmStationAddress" BU_ SteeringController 19;
BA_ "NmJ1939Function" BU_ SteeringController 16;
BA_ "NmStationAddress" BU_ FuelSystem 18;
BA_ "NmJ1939Function" BU_ FuelSystem 15;
BA_ "NmStationAddress" BU_ CruiseControl 17;
BA_ "NmJ1939Function" BU_ CruiseControl 14;
BA_ "NmStationAddress" BU_ RetarderDriveline 16;
BA_ "NmJ1939Function" BU_ RetarderDriveline 13;
BA_ "NmStationAddress" BU_ RetarderEngine 15;
BA_ "NmJ1939Function" BU_ RetarderEngine 12;
BA_ "NmStationAddress" BU_ BrakesDriveAxle2 14;
BA_ "NmJ1939Function" BU_ BrakesDriveAxle2 11;
BA_ "NmJ1939FunctionInstance" BU_ BrakesDriveAxle2 1;
BA_ "NmStationAddress" BU_ BrakesDriveAxle1 13;
BA_ "NmJ1939Function" BU_ BrakesDriveAxle1 11;
BA_ "NmStationAddress" BU_ BrakesSystemController 11;
BA_ "NmJ1939Function" BU_ BrakesSystemController 9;
BA_ "NmStationAddress" BU_ BrakesSteerAxle 12;
BA_ "NmJ1939Function" BU_ BrakesSteerAxle 10;
BA_ "NmStationAddress" BU_ AxleDrive2 10;
BA_ "NmJ1939Function" BU_ AxleDrive2 8;
BA_ "NmJ1939FunctionInstance" BU_ AxleDrive2 1;
BA_ "NmStationAddress" BU_ AxleDrive1 9;
BA_ "NmJ1939Function" BU_ AxleDrive1 8;
BA_ "NmStationAddress" BU_ AxleSteering 8;
BA_ "NmJ1939Function" BU_ AxleSteering 7;
BA_ "NmStationAddress" BU_ PowerTakeOff 7;
BA_ "NmJ1939Function" BU_ PowerTakeOff 6;
BA_ "NmStationAddress" BU_ ShiftConsoleSecondary 6;
BA_ "NmJ1939Function" BU_ ShiftConsoleSecondary 5;
BA_ "NmJ1939FunctionInstance" BU_ ShiftConsoleSecondary 1;
BA_ "NmStationAddress" BU_ ShiftConsolePrimary 5;
BA_ "NmJ1939Function" BU_ ShiftConsolePrimary 5;
BA_ "NmStationAddress" BU_ Transmission2 4;
BA_ "NmJ1939Function" BU_ Transmission2 3;
BA_ "NmJ1939FunctionInstance" BU_ Transmission2 1;
BA_ "NmStationAddress" BU_ Transmission1 3;
BA_ "NmJ1939Function" BU_ Transmission1 3;
BA_ "NmStationAddress" BU_ Engine2 1;
BA_ "NmJ1939FunctionInstance" BU_ Engine2 1;
BA_ "NmStationAddress" BU_ Engine1 0;
BA_ "GenMsgSendType" BO_ 2566658558 0;
BA_ "GenMsgCycleTime" BO_ 2566658558 5000;
BA_ "GenMsgSendType" BO_ 2566658302 0;
BA_ "GenMsgCycleTime" BO_ 2566658302 5000;
BA_ "GenMsgSendType" BO_ 2499549182 0;
BA_ "GenMsgCycleTime" BO_ 2499549182 1000;
BA_ "GenMsgSendType" BO_ 2499548926 0;
BA_ "GenMsgCycleTime" BO_ 2499548926 1000;
BA_ "GenMsgSendType" BO_ 2499548670 0;
BA_ "GenMsgCycleTime" BO_ 2499548670 100;
BA_ "GenMsgDelayTime" BO_ 2499548158 100;
BA_ "GenMsgSendType" BO_ 2499548158 0;
BA_ "GenMsgCycleTime" BO_ 2499548158 1000;
BA_ "GenMsgDelayTime" BO_ 2499547902 100;
BA_ "GenMsgSendType" BO_ 2499547902 0;
BA_ "GenMsgCycleTime" BO_ 2499547902 1000;
BA_ "SendOnChange" BO_ 2499547902 1;
BA_ "GenMsgDelayTime" BO_ 2431710718 20;
BA_ "GenMsgDelayTime" BO_ 2431708670 20;
BA_ "GenMsgSendType" BO_ 2565926142 0;
BA_ "GenMsgCycleTime" BO_ 2565926142 50;
BA_ "GenMsgSendType" BO_ 2565925886 0;
BA_ "GenMsgCycleTime" BO_ 2565925886 50;
BA_ "GenMsgSendType" BO_ 2565925630 0;
BA_ "GenMsgCycleTime" BO_ 2565925630 50;
BA_ "GenMsgSendType" BO_ 2565925374 0;
BA_ "GenMsgCycleTime" BO_ 2565925374 50;
BA_ "GenMsgSendType" BO_ 2364598526 0;
BA_ "GenMsgCycleTime" BO_ 2364598526 50;
BA_ "TpJ1939VarDlc" BO_ 2558525182 1;
BA_ "GenMsgSendType" BO_ 2350841598 0;
BA_ "GenMsgCycleTime" BO_ 2350841598 200;
BA_ "GenMsgSendType" BO_ 2566838014 0;
BA_ "GenMsgCycleTime" BO_ 2566838014 1000;
BA_ "GenMsgSendType" BO_ 2566756350 0;
BA_ "GenMsgCycleTime" BO_ 2566756350 1000;
BA_ "GenMsgSendType" BO_ 2566756094 0;
BA_ "GenMsgCycleTime" BO_ 2566756094 1000;
BA_ "GenMsgSendType" BO_ 2566687998 0;
BA_ "GenMsgCycleTime" BO_ 2566687998 200;
BA_ "GenMsgSendType" BO_ 2566687742 0;
BA_ "GenMsgCycleTime" BO_ 2566687742 200;
BA_ "GenMsgDelayTime" BO_ 2365348350 50;
BA_ "GenMsgSendType" BO_ 2365348350 0;
BA_ "GenMsgCycleTime" BO_ 2365348350 500;
BA_ "GenMsgSendType" BO_ 2566674686 0;
BA_ "GenMsgCycleTime" BO_ 2566674686 1000;
BA_ "GenMsgDelayTime" BO_ 2566674430 1000;
BA_ "GenMsgSendType" BO_ 2566674430 0;
BA_ "GenMsgCycleTime" BO_ 2566674430 10000;
BA_ "GenMsgDelayTime" BO_ 2566674174 1000;
BA_ "GenMsgSendType" BO_ 2566674174 0;
BA_ "GenMsgCycleTime" BO_ 2566674174 10000;
BA_ "GenMsgSendType" BO_ 2566673406 0;
BA_ "GenMsgCycleTime" BO_ 2566673406 500;
BA_ "GenMsgDelayTime" BO_ 2633782014 1000;
BA_ "GenMsgSendType" BO_ 2633782014 0;
BA_ "GenMsgCycleTime" BO_ 2633782014 10000;
BA_ "GenMsgSendType" BO_ 2365346302 0;
BA_ "GenMsgCycleTime" BO_ 2365346302 100;
BA_ "GenMsgSendType" BO_ 2566672638 0;
BA_ "GenMsgCycleTime" BO_ 2566672638 1000;
BA_ "GenMsgSendType" BO_ 2566672382 0;
BA_ "GenMsgCycleTime" BO_ 2566672382 1000;
BA_ "GenMsgSendType" BO_ 2566672126 0;
BA_ "GenMsgCycleTime" BO_ 2566672126 500;
BA_ "GenMsgSendType" BO_ 2566671870 0;
BA_ "GenMsgCycleTime" BO_ 2566671870 500;
BA_ "GenMsgDelayTime" BO_ 2566671102 100;
BA_ "GenMsgSendType" BO_ 2566671102 0;
BA_ "GenMsgCycleTime" BO_ 2566671102 1000;
BA_ "TpJ1939VarDlc" BO_ 2566670078 1;
BA_ "GenMsgSendType" BO_ 2566669054 0;
BA_ "GenMsgCycleTime" BO_ 2566669054 10000;
BA_ "GenMsgSendType" BO_ 2566668798 0;
BA_ "GenMsgCycleTime" BO_ 2566668798 500;
BA_ "GenMsgSendType" BO_ 2566668542 0;
BA_ "GenMsgCycleTime" BO_ 2566668542 500;
BA_ "GenMsgSendType" BO_ 2566668030 0;
BA_ "GenMsgCycleTime" BO_ 2566668030 1000;
BA_ "GenMsgSendType" BO_ 2566667774 0;
BA_ "GenMsgCycleTime" BO_ 2566667774 1000;
BA_ "GenMsgSendType" BO_ 2566667518 0;
BA_ "GenMsgCycleTime" BO_ 2566667518 1000;
BA_ "GenMsgSendType" BO_ 2566667262 0;
BA_ "GenMsgCycleTime" BO_ 2566667262 1000;
BA_ "GenMsgSendType" BO_ 2499558142 0;
BA_ "GenMsgCycleTime" BO_ 2499558142 500;
BA_ "GenMsgSendType" BO_ 2499557886 0;
BA_ "GenMsgCycleTime" BO_ 2499557886 500;
BA_ "GenMsgSendType" BO_ 2499557630 0;
BA_ "GenMsgCycleTime" BO_ 2499557630 500;
BA_ "GenMsgSendType" BO_ 2499557374 0;
BA_ "GenMsgCycleTime" BO_ 2499557374 500;
BA_ "GenMsgSendType" BO_ 2499557118 0;
BA_ "GenMsgCycleTime" BO_ 2499557118 500;
BA_ "GenMsgSendType" BO_ 2566665726 0;
BA_ "GenMsgCycleTime" BO_ 2566665726 500;
BA_ "GenMsgSendType" BO_ 2499556606 0;
BA_ "GenMsgCycleTime" BO_ 2499556606 500;
BA_ "GenMsgSendType" BO_ 2499556350 0;
BA_ "GenMsgCycleTime" BO_ 2499556350 500;
BA_ "GenMsgSendType" BO_ 2499556094 0;
BA_ "GenMsgCycleTime" BO_ 2499556094 250;
BA_ "GenMsgDelayTime" BO_ 2566664702 100;
BA_ "GenMsgSendType" BO_ 2566664702 0;
BA_ "GenMsgCycleTime" BO_ 2566664702 1000;
BA_ "GenMsgSendType" BO_ 2633773054 0;
BA_ "GenMsgCycleTime" BO_ 2633773054 1000;
BA_ "GenMsgSendType" BO_ 2566663934 0;
BA_ "GenMsgCycleTime" BO_ 2566663934 500;
BA_ "GenMsgSendType" BO_ 2566663678 0;
BA_ "GenMsgCycleTime" BO_ 2566663678 500;
BA_ "SigType" SG_ 3221225472 NumberOfMembersInWorkingSet 3;
BA_ "SPN" SG_ 3221225472 NumberOfMembersInWorkingSet 2409;
BA_ "SPN" SG_ 3221225472 SourceAddress 5600;
BA_ "SPN" SG_ 3221225472 NncntnuslyMonitoredSystemsStatus 1223;
BA_ "SPN" SG_ 3221225472 NncntnslyMonitoredSystemsSupport 1222;
BA_ "SPN" SG_ 3221225472 CntnslyMntrdSystmsSupport_Status 1221;
BA_ "SigType" SG_ 3221225472 AETCTorqueValue 1;
BA_ "SPN" SG_ 3221225472 AETCTorqueValue 3561;
BA_ "SigType" SG_ 3221225472 TrailerWeight 1;
BA_ "SPN" SG_ 3221225472 TrailerWeight 180;
BA_ "SPN" SG_ 3221225472 ReferenceTirePressSetting 3193;
BA_ "SPN" SG_ 3221225472 ReferenceTirePress 3191;
BA_ "SPN" SG_ 3221225472 TirePressThresholdDetection 2587;
BA_ "SigType" SG_ 3221225472 TireAirLeakageRate 1;
BA_ "SPN" SG_ 3221225472 TireAirLeakageRate 2586;
BA_ "SigType" SG_ 3221225472 CTIWheelEndElectricalFault 4;
BA_ "SPN" SG_ 3221225472 CTIWheelEndElectricalFault 1697;
BA_ "SigType" SG_ 3221225472 CTITireStatus 4;
BA_ "SPN" SG_ 3221225472 CTITireStatus 1698;
BA_ "SigType" SG_ 3221225472 CTIWheelSensorStatus 4;
BA_ "SPN" SG_ 3221225472 CTIWheelSensorStatus 1699;
BA_ "SigType" SG_ 3221225472 TireTemp 1;
BA_ "SPN" SG_ 3221225472 TireTemp 242;
BA_ "SigType" SG_ 3221225472 TirePress 1;
BA_ "SPN" SG_ 3221225472 TirePress 241;
BA_ "SigType" SG_ 3221225472 EngTurningGearEngaged 4;
BA_ "SPN" SG_ 3221225472 EngTurningGearEngaged 1206;
BA_ "SigType" SG_ 3221225472 AETCSpeedValue 1;
BA_ "SPN" SG_ 3221225472 AETCSpeedValue 3560;
BA_ "SigType" SG_ 2566658558 TotalHaulCycleCount 1;
BA_ "SPN" SG_ 2566658558 TotalHaulCycleCount 7700;
BA_ "SigType" SG_ 2566658558 TotalDeliveredPayloadWeight 1;
BA_ "SPN" SG_ 2566658558 TotalDeliveredPayloadWeight 7699;
BA_ "SigType" SG_ 2566658302 TotalPayloadTransactionCount 1;
BA_ "SPN" SG_ 2566658302 TotalPayloadTransactionCount 7701;
BA_ "SPN" SG_ 2499548158 RightRearCabDoorLatchPos 7726;
BA_ "SPN" SG_ 2499548158 LeftRearCabDoorLatchPos 7725;
BA_ "SPN" SG_ 2499548158 RightFrontCabDoorLatchPos 7724;
BA_ "SPN" SG_ 2499548158 LeftFrontCabDoorLatchPos 7723;
BA_ "SigType" SG_ 2499547902 MirrorRight2HeatCmd 5;
BA_ "SPN" SG_ 2499547902 MirrorRight2HeatCmd 7744;
BA_ "SigType" SG_ 2499547902 MirrorLeft2HeatCmd 5;
BA_ "SPN" SG_ 2499547902 MirrorLeft2HeatCmd 7743;
BA_ "SigType" SG_ 2499547902 MirrorRight1HeatCmd 5;
BA_ "SPN" SG_ 2499547902 MirrorRight1HeatCmd 7742;
BA_ "SigType" SG_ 2499547902 MirrorLeft1HeatCmd 5;
BA_ "SPN" SG_ 2499547902 MirrorLeft1HeatCmd 7741;
BA_ "SigType" SG_ 2499547902 MirrorRight2VerticalCmd 5;
BA_ "SPN" SG_ 2499547902 MirrorRight2VerticalCmd 7740;
BA_ "SigType" SG_ 2499547902 MirrorRight2HorizontalCmd 5;
BA_ "SPN" SG_ 2499547902 MirrorRight2HorizontalCmd 7739;
BA_ "SigType" SG_ 2499547902 MirrorLeft2VerticalCmd 5;
BA_ "SPN" SG_ 2499547902 MirrorLeft2VerticalCmd 7738;
BA_ "SigType" SG_ 2499547902 MirrorLeft2HorizontalCmd 5;
BA_ "SPN" SG_ 2499547902 MirrorLeft2HorizontalCmd 7737;
BA_ "SigType" SG_ 2499547902 MirrorRight1VerticalCmd 5;
BA_ "SPN" SG_ 2499547902 MirrorRight1VerticalCmd 7736;
BA_ "SigType" SG_ 2499547902 MirrorRight1HorizontalCmd 5;
BA_ "SPN" SG_ 2499547902 MirrorRight1HorizontalCmd 7735;
BA_ "SigType" SG_ 2499547902 MirrorLeft1VerticalCmd 5;
BA_ "SPN" SG_ 2499547902 MirrorLeft1VerticalCmd 7734;
BA_ "SigType" SG_ 2499547902 MirrorLeft1HorizontalCmd 5;
BA_ "SPN" SG_ 2499547902 MirrorLeft1HorizontalCmd 7733;
BA_ "SPN" SG_ 2499547902 RightRearWindowPosCmd 7732;
BA_ "SPN" SG_ 2499547902 LeftRearWindowPosCmd 7731;
BA_ "SPN" SG_ 2499547902 RightFrontWindowPosCmd 7730;
BA_ "SPN" SG_ 2499547902 LeftFrontWindowPosCmd 7729;
BA_ "SPN" SG_ 2499547902 RemoteCabDoorLockReq 7728;
BA_ "SPN" SG_ 2499547902 DoorsLockActCmd 7727;
BA_ "SigType" SG_ 2566656510 EngTotalGasIdleFuelVolumeUsed 1;
BA_ "SPN" SG_ 2566656510 EngTotalGasIdleFuelVolumeUsed 7456;
BA_ "SigType" SG_ 2566656510 EngTotalGasFuelVolumeUsed 1;
BA_ "SPN" SG_ 2566656510 EngTotalGasFuelVolumeUsed 7455;
BA_ "SPN" SG_ 2431710718 Checksum 7758;
BA_ "SPN" SG_ 2431710718 MessageCounter 7757;
BA_ "SigType" SG_ 2431710718 AutomaticEngStartConsentSummary 5;
BA_ "SPN" SG_ 2431710718 AutomaticEngStartConsentSummary 7756;
BA_ "SigType" SG_ 2431710718 OpEngStartConsentSummary 5;
BA_ "SPN" SG_ 2431710718 OpEngStartConsentSummary 7755;
BA_ "SPN" SG_ 2431710718 ReqLatchStatus 7754;
BA_ "SPN" SG_ 2431710718 StarterCmd 7753;
BA_ "SigType" SG_ 2431710718 CtrlMessageRate 5;
BA_ "SPN" SG_ 2431710718 CtrlMessageRate 7752;
BA_ "SPN" SG_ 2431708670 Checksum 7751;
BA_ "SPN" SG_ 2431708670 MessageCounter 7750;
BA_ "SPN" SG_ 2431708670 Starter2Feedback 7749;
BA_ "SPN" SG_ 2431708670 Starter1Feedback 7748;
BA_ "SigType" SG_ 2431708670 AbortReq 5;
BA_ "SPN" SG_ 2431708670 AbortReq 7747;
BA_ "SPN" SG_ 2431708670 Consent 7746;
BA_ "SigType" SG_ 2431708670 Req 5;
BA_ "SPN" SG_ 2431708670 Req 7745;
BA_ "SigType" SG_ 2566661118 EngTotalDieselFuelDemand 1;
BA_ "SPN" SG_ 2566661118 EngTotalDieselFuelDemand 7597;
BA_ "SigType" SG_ 2633769726 TotalEngEnergy 1;
BA_ "SPN" SG_ 2633769726 TotalEngEnergy 7608;
BA_ "SPN" SG_ 2565926142 O2Snsr2PreliminaryFMI 7692;
BA_ "SPN" SG_ 2565926142 NOxSnsr2SelfDiagStatus 7691;
BA_ "SPN" SG_ 2565926142 NOxSnsr2PreliminaryFMI 7690;
BA_ "SigType" SG_ 2565926142 GasSnsr2HtrCtrl 5;
BA_ "SPN" SG_ 2565926142 GasSnsr2HtrCtrl 7689;
BA_ "SPN" SG_ 2565926142 GasSnsr2HtrPreliminaryFMI 7688;
BA_ "SigType" SG_ 2565926142 WRPercentO22ReadingStable 5;
BA_ "SPN" SG_ 2565926142 WRPercentO22ReadingStable 7687;
BA_ "SigType" SG_ 2565926142 NOx2ReadingStable 5;
BA_ "SPN" SG_ 2565926142 NOx2ReadingStable 7686;
BA_ "SigType" SG_ 2565926142 GasSnsr2AtTemp 5;
BA_ "SPN" SG_ 2565926142 GasSnsr2AtTemp 7685;
BA_ "SigType" SG_ 2565926142 GasSnsr2PwrInRange 5;
BA_ "SPN" SG_ 2565926142 GasSnsr2PwrInRange 7684;
BA_ "SigType" SG_ 2565926142 PercentO22 1;
BA_ "SPN" SG_ 2565926142 PercentO22 7683;
BA_ "SigType" SG_ 2565926142 NOx2 1;
BA_ "SPN" SG_ 2565926142 NOx2 7682;
BA_ "SPN" SG_ 2565925886 O2Snsr2PreliminaryFMI 7681;
BA_ "SPN" SG_ 2565925886 NOxSnsr2SelfDiagStatus 7680;
BA_ "SPN" SG_ 2565925886 SCRInNOxSnsr2PreliminaryFMI 7679;
BA_ "SigType" SG_ 2565925886 GasSnsr2HtrCtrl 5;
BA_ "SPN" SG_ 2565925886 GasSnsr2HtrCtrl 7678;
BA_ "SPN" SG_ 2565925886 GasSnsr2HtrPreliminaryFMI 7677;
BA_ "SigType" SG_ 2565925886 WRPercentO22ReadingStable 5;
BA_ "SPN" SG_ 2565925886 WRPercentO22ReadingStable 7676;
BA_ "SigType" SG_ 2565925886 SCRInNOx2ReadingStable 5;
BA_ "SPN" SG_ 2565925886 SCRInNOx2ReadingStable 7675;
BA_ "SigType" SG_ 2565925886 GasSnsr2AtTemp 5;
BA_ "SPN" SG_ 2565925886 GasSnsr2AtTemp 7674;
BA_ "SigType" SG_ 2565925886 GasSnsr2PwrInRange 5;
BA_ "SPN" SG_ 2565925886 GasSnsr2PwrInRange 7673;
BA_ "SigType" SG_ 2565925886 PercentO22 1;
BA_ "SPN" SG_ 2565925886 PercentO22 7672;
BA_ "SigType" SG_ 2565925886 SCRInNOx2 1;
BA_ "SPN" SG_ 2565925886 SCRInNOx2 7671;
BA_ "SPN" SG_ 2565925630 O2Snsr2PreliminaryFMI 7670;
BA_ "SPN" SG_ 2565925630 NOxSnsr2SelfDiagStatus 7669;
BA_ "SPN" SG_ 2565925630 NOxSnsr2PreliminaryFMI 7668;
BA_ "SigType" SG_ 2565925630 Snsr2HtrCtrl 5;
BA_ "SPN" SG_ 2565925630 Snsr2HtrCtrl 7667;
BA_ "SPN" SG_ 2565925630 Snsr2HtrPreliminaryFMI 7666;
BA_ "SigType" SG_ 2565925630 WRPercentO22ReadingStable 5;
BA_ "SPN" SG_ 2565925630 WRPercentO22ReadingStable 7665;
BA_ "SigType" SG_ 2565925630 NOx2ReadingStable 5;
BA_ "SPN" SG_ 2565925630 NOx2ReadingStable 7664;
BA_ "SigType" SG_ 2565925630 Snsr2AtTemp 5;
BA_ "SPN" SG_ 2565925630 Snsr2AtTemp 7663;
BA_ "SigType" SG_ 2565925630 Snsr2PwrInRange 5;
BA_ "SPN" SG_ 2565925630 Snsr2PwrInRange 7662;
BA_ "SigType" SG_ 2565925630 PercentO22 1;
BA_ "SPN" SG_ 2565925630 PercentO22 7661;
BA_ "SigType" SG_ 2565925630 NOx2 1;
BA_ "SPN" SG_ 2565925630 NOx2 7660;
BA_ "SPN" SG_ 2565925374 O2Snsr2PreliminaryFMI 7659;
BA_ "SPN" SG_ 2565925374 NOxSnsr2SelfDiagStatus 7658;
BA_ "SPN" SG_ 2565925374 SCRInNOxSnsr2PreliminaryFMI 7657;
BA_ "SigType" SG_ 2565925374 Snsr2HtrCtrl 5;
BA_ "SPN" SG_ 2565925374 Snsr2HtrCtrl 7656;
BA_ "SPN" SG_ 2565925374 Snsr2HtrPreliminaryFMI 7655;
BA_ "SigType" SG_ 2565925374 WRPercentO22ReadingStable 5;
BA_ "SPN" SG_ 2565925374 WRPercentO22ReadingStable 7654;
BA_ "SigType" SG_ 2565925374 SCRInNOx2ReadingStable 5;
BA_ "SPN" SG_ 2565925374 SCRInNOx2ReadingStable 7653;
BA_ "SigType" SG_ 2565925374 Snsr2AtTemp 5;
BA_ "SPN" SG_ 2565925374 Snsr2AtTemp 7652;
BA_ "SigType" SG_ 2565925374 Snsr2PwrInRange 5;
BA_ "SPN" SG_ 2565925374 Snsr2PwrInRange 7651;
BA_ "SigType" SG_ 2565925374 PercentO22 1;
BA_ "SPN" SG_ 2565925374 PercentO22 7650;
BA_ "SigType" SG_ 2565925374 SCRInNOx2 1;
BA_ "SPN" SG_ 2565925374 SCRInNOx2 7649;
BA_ "SigType" SG_ 2364598526 FuelAct4CtrlCmd 1;
BA_ "SPN" SG_ 2364598526 FuelAct4CtrlCmd 7594;
BA_ "SigType" SG_ 2364598526 FuelAct3CtrlCmd 1;
BA_ "SPN" SG_ 2364598526 FuelAct3CtrlCmd 7593;
BA_ "SigType" SG_ 2558525182 Num7586 8;
BA_ "SPN" SG_ 2558525182 Num7586 7586;
BA_ "SPN" SG_ 2558525182 Location 7585;
BA_ "SigType" SG_ 2558525182 Num 1;
BA_ "SPN" SG_ 2558525182 Num 7584;
BA_ "SigType" SG_ 2558525182 NumOfTireSensors 1;
BA_ "SPN" SG_ 2558525182 NumOfTireSensors 7583;
BA_ "SigType" SG_ 2350841598 TrqRampMaxSpdCmd 1;
BA_ "SPN" SG_ 2350841598 TrqRampMaxSpdCmd 7592;
BA_ "SigType" SG_ 2350841598 TrqRampTimeCmd 1;
BA_ "GenSigStartValue" SG_ 2350841598 TrqRampTimeCmd 1;
BA_ "SPN" SG_ 2350841598 TrqRampTimeCmd 7591;
BA_ "SigType" SG_ 2350841598 ExcitationMaxCurrentLmt 1;
BA_ "SPN" SG_ 2350841598 ExcitationMaxCurrentLmt 7590;
BA_ "SigType" SG_ 2350841598 SetpointVoltageCmd 1;
BA_ "SPN" SG_ 2350841598 SetpointVoltageCmd 7589;
BA_ "SigType" SG_ 2566838014 ShutdownSw 4;
BA_ "SPN" SG_ 2566838014 ShutdownSw 7555;
BA_ "SigType" SG_ 2566838014 PropulsionDisableSw 4;
BA_ "SPN" SG_ 2566838014 PropulsionDisableSw 7554;
BA_ "SigType" SG_ 2566838014 HybrdSystmCstngRgnrtvBrkngLvlSlc 1;
BA_ "SPN" SG_ 2566838014 HybrdSystmCstngRgnrtvBrkngLvlSlc 7556;
BA_ "SigType" SG_ 2566838014 HybrdSystmBrkPdlRgnrtvBrkngDsblS 4;
BA_ "SPN" SG_ 2566838014 HybrdSystmBrkPdlRgnrtvBrkngDsblS 7553;
BA_ "SigType" SG_ 2566838014 HybrdSystmRgnrtvBrkngDsbleSwitch 4;
BA_ "SPN" SG_ 2566838014 HybrdSystmRgnrtvBrkngDsbleSwitch 7552;
BA_ "SigType" SG_ 2566838014 HybrdSystmOffBrdChrgrCnnctnSttus 4;
BA_ "SPN" SG_ 2566838014 HybrdSystmOffBrdChrgrCnnctnSttus 7551;
BA_ "SigType" SG_ 2566838014 HybrdSystmPwrElctrncsClntLvlSwtc 4;
BA_ "SPN" SG_ 2566838014 HybrdSystmPwrElctrncsClntLvlSwtc 7550;
BA_ "SigType" SG_ 2566838014 HybrdSystmPrplsnClantLevelSwitch 4;
BA_ "SPN" SG_ 2566838014 HybrdSystmPrplsnClantLevelSwitch 7549;
BA_ "SigType" SG_ 2566838014 HybrdSystmPrtctionOverrideSwitch 4;
BA_ "SPN" SG_ 2566838014 HybrdSystmPrtctionOverrideSwitch 7548;
BA_ "SigType" SG_ 2566761726 EngIdleFuelFlowRateThreshold 1;
BA_ "SPN" SG_ 2566761726 EngIdleFuelFlowRateThreshold 2778;
BA_ "SigType" SG_ 2566761726 NmbrOfFlCnsmptnMntrngTransducers 1;
BA_ "SPN" SG_ 2566761726 NmbrOfFlCnsmptnMntrngTransducers 2777;
BA_ "SigType" SG_ 2566756350 EngFuelReturnTemp 1;
BA_ "SPN" SG_ 2566756350 EngFuelReturnTemp 2776;
BA_ "SigType" SG_ 2566756350 EngFuelSupplyTemp 1;
BA_ "SPN" SG_ 2566756350 EngFuelSupplyTemp 2775;
BA_ "SigType" SG_ 2566756094 EngFuelReturnFlowRate 1;
BA_ "SPN" SG_ 2566756094 EngFuelReturnFlowRate 2774;
BA_ "SigType" SG_ 2566756094 EngFuelSupplyFlowRate 1;
BA_ "SPN" SG_ 2566756094 EngFuelSupplyFlowRate 2773;
BA_ "SigType" SG_ 2566687998 TimeBetweenRegens 1;
BA_ "SPN" SG_ 2566687998 TimeBetweenRegens 6776;
BA_ "SigType" SG_ 2566687998 ActiveAccumulationTime 1;
BA_ "SPN" SG_ 2566687998 ActiveAccumulationTime 6775;
BA_ "SPN" SG_ 2566687998 RegenSt 6774;
BA_ "SigType" SG_ 2566687998 RegenStatus 5;
BA_ "SPN" SG_ 2566687998 RegenStatus 6773;
BA_ "SigType" SG_ 2566687998 HtrSt 5;
BA_ "SPN" SG_ 2566687998 HtrSt 6772;
BA_ "SigType" SG_ 2566687998 Res 1;
BA_ "SPN" SG_ 2566687998 Res 6771;
BA_ "SigType" SG_ 2566687742 HtrRes 1;
BA_ "SPN" SG_ 2566687742 HtrRes 7070;
BA_ "SigType" SG_ 2566687742 MaxRes 1;
BA_ "SPN" SG_ 2566687742 MaxRes 6781;
BA_ "SigType" SG_ 2566687742 Temp 1;
BA_ "SPN" SG_ 2566687742 Temp 6780;
BA_ "SigType" SG_ 2566687742 RegenFailedCount 1;
BA_ "SPN" SG_ 2566687742 RegenFailedCount 6779;
BA_ "SigType" SG_ 2566687742 PwrSupply 4;
BA_ "SPN" SG_ 2566687742 PwrSupply 6778;
BA_ "SPN" SG_ 2566687742 DetectionStatus 6777;
BA_ "SPN" SG_ 2365348350 EngLoadShareStatus 6794;
BA_ "SigType" SG_ 2365348350 EngUnloadStatus 4;
BA_ "SPN" SG_ 2365348350 EngUnloadStatus 6793;
BA_ "SigType" SG_ 2566674686 EngTurbo4LubeOilPress 1;
BA_ "SPN" SG_ 2566674686 EngTurbo4LubeOilPress 6813;
BA_ "SigType" SG_ 2566674686 EngTurbo3LubeOilPress 1;
BA_ "SPN" SG_ 2566674686 EngTurbo3LubeOilPress 6812;
BA_ "SigType" SG_ 2566674686 EngTurbo2LubeOilPress 1;
BA_ "SPN" SG_ 2566674686 EngTurbo2LubeOilPress 6811;
BA_ "SigType" SG_ 2566674430 DslExhstFldQalityMalfunctionTime 1;
BA_ "SPN" SG_ 2566674430 DslExhstFldQalityMalfunctionTime 6818;
BA_ "SigType" SG_ 2566674430 DieselExhaustFluidTank1EmptyTime 1;
BA_ "SPN" SG_ 2566674430 DieselExhaustFluidTank1EmptyTime 6817;
BA_ "SigType" SG_ 2566674174 SCROperatorInducementTotalTime 1;
BA_ "SPN" SG_ 2566674174 SCROperatorInducementTotalTime 7095;
BA_ "SigType" SG_ 2566674174 AFTSCRMalfunctionTime 1;
BA_ "SPN" SG_ 2566674174 AFTSCRMalfunctionTime 6819;
BA_ "SigType" SG_ 2566673406 GasLeakageDetection3Press 1;
BA_ "SPN" SG_ 2566673406 GasLeakageDetection3Press 6839;
BA_ "SigType" SG_ 2566673406 GasLeakageDetection2Press 1;
BA_ "SPN" SG_ 2566673406 GasLeakageDetection2Press 6838;
BA_ "SigType" SG_ 2566673406 GasLeakageDetection1Press 1;
BA_ "SPN" SG_ 2566673406 GasLeakageDetection1Press 6837;
BA_ "SigType" SG_ 2566673406 GasFuelLeakage3Concentration 1;
BA_ "SPN" SG_ 2566673406 GasFuelLeakage3Concentration 6836;
BA_ "SigType" SG_ 2566673406 GasFuelLeakage2Concentration 1;
BA_ "SPN" SG_ 2566673406 GasFuelLeakage2Concentration 6835;
BA_ "SigType" SG_ 2566673406 GasFuelLeakage1Concentration 1;
BA_ "SPN" SG_ 2566673406 GasFuelLeakage1Concentration 6834;
BA_ "SigType" SG_ 2633782014 NetBinWeight 1;
BA_ "SPN" SG_ 2633782014 NetBinWeight 6841;
BA_ "SigType" SG_ 2633782014 BinLiftCount 1;
BA_ "SPN" SG_ 2633782014 BinLiftCount 6840;
BA_ "SPN" SG_ 2633782014 BinWeighingErrorStatus 6842;
BA_ "SPN" SG_ 2633782014 BinInstance 6845;
BA_ "SPN" SG_ 2365346302 LiftAxle2Status 6844;
BA_ "SPN" SG_ 2365346302 LiftAxle1Status 6843;
BA_ "SPN" SG_ 2566672638 DeliveryTransactionStatus 7702;
BA_ "SigType" SG_ 2566672638 DeliveredPayloadConfidence 1;
BA_ "SPN" SG_ 2566672638 DeliveredPayloadConfidence 6850;
BA_ "SPN" SG_ 2566672638 DeliveredPayloadWeight 6849;
BA_ "SPN" SG_ 2566672638 HaulModeStatus 6848;
BA_ "SigType" SG_ 2566672638 HaulCycleCount 1;
BA_ "SPN" SG_ 2566672638 HaulCycleCount 6847;
BA_ "SigType" SG_ 2566672382 PayloadWeightSensor8Status 5;
BA_ "SPN" SG_ 2566672382 PayloadWeightSensor8Status 6862;
BA_ "SigType" SG_ 2566672382 PayloadWeightSensor7Status 5;
BA_ "SPN" SG_ 2566672382 PayloadWeightSensor7Status 6861;
BA_ "SigType" SG_ 2566672382 PayloadWeightSensor6Status 5;
BA_ "SPN" SG_ 2566672382 PayloadWeightSensor6Status 6860;
BA_ "SigType" SG_ 2566672382 PayloadWeightSensor5Status 5;
BA_ "SPN" SG_ 2566672382 PayloadWeightSensor5Status 6859;
BA_ "SigType" SG_ 2566672382 PayloadWeightSensor4Status 5;
BA_ "SPN" SG_ 2566672382 PayloadWeightSensor4Status 6858;
BA_ "SigType" SG_ 2566672382 PayloadWeightSensor3Status 5;
BA_ "SPN" SG_ 2566672382 PayloadWeightSensor3Status 6857;
BA_ "SigType" SG_ 2566672382 PayloadWeightSensor2Status 5;
BA_ "SPN" SG_ 2566672382 PayloadWeightSensor2Status 6856;
BA_ "SigType" SG_ 2566672382 PayloadWeightSensor1Status 5;
BA_ "SPN" SG_ 2566672382 PayloadWeightSensor1Status 6855;
BA_ "SigType" SG_ 2566672126 DEFDoser2Temp 1;
BA_ "SPN" SG_ 2566672126 DEFDoser2Temp 7460;
BA_ "SigType" SG_ 2566672126 DEFDoser2AbsPress 1;
BA_ "SPN" SG_ 2566672126 DEFDoser2AbsPress 7459;
BA_ "SigType" SG_ 2566672126 DEFDosingPress 1;
BA_ "SPN" SG_ 2566672126 DEFDosingPress 6875;
BA_ "SigType" SG_ 2566671870 DEFDosing2Temp 1;
BA_ "SPN" SG_ 2566671870 DEFDosing2Temp 7465;
BA_ "SigType" SG_ 2566671870 DEFDoser2AbsPress 1;
BA_ "SPN" SG_ 2566671870 DEFDoser2AbsPress 7464;
BA_ "SigType" SG_ 2566671870 DEFDosingPress 1;
BA_ "SPN" SG_ 2566671870 DEFDosingPress 6876;
BA_ "SigType" SG_ 2566671614 TtlNmbrOfSCROprtrIndcmntOvrrdEvn 1;
BA_ "SPN" SG_ 2566671614 TtlNmbrOfSCROprtrIndcmntOvrrdEvn 6880;
BA_ "SigType" SG_ 2566671614 NmbrOfSCROprtrIndcmntOvrrdEvntsR 1;
BA_ "SPN" SG_ 2566671614 NmbrOfSCROprtrIndcmntOvrrdEvntsR 6879;
BA_ "SigType" SG_ 2566671614 SCROprtrIndcmntOvrrdTmeRemaining 1;
BA_ "SPN" SG_ 2566671614 SCROprtrIndcmntOvrrdTmeRemaining 6878;
BA_ "SigType" SG_ 2566671614 SCROprtrInducementOverrideEnable 5;
BA_ "SPN" SG_ 2566671614 SCROprtrInducementOverrideEnable 6877;
BA_ "SigType" SG_ 2566671358 CylFuelRate 1;
BA_ "SPN" SG_ 2566671358 CylFuelRate 7333;
BA_ "SigType" SG_ 2566671358 EngExhaustFlowRate 1;
BA_ "SPN" SG_ 2566671358 EngExhaustFlowRate 6895;
BA_ "SigType" SG_ 2566671358 VehicleFuelRate 1;
BA_ "SPN" SG_ 2566671358 VehicleFuelRate 6894;
BA_ "SigType" SG_ 2566671358 PEMSEngFuelMassFlowRate 1;
BA_ "SPN" SG_ 2566671358 PEMSEngFuelMassFlowRate 6893;
BA_ "SPN" SG_ 2566671102 SCRSystemCleaningForcedStatus 6934;
BA_ "SigType" SG_ 2566671102 SCRSystmClnngAtmtcIntationConfig 5;
BA_ "SPN" SG_ 2566671102 SCRSystmClnngAtmtcIntationConfig 6933;
BA_ "SigType" SG_ 2566671102 SCRSystmClnngInhbtdDTVhclSpdBlwA 5;
BA_ "SPN" SG_ 2566671102 SCRSystmClnngInhbtdDTVhclSpdBlwA 6932;
BA_ "SigType" SG_ 2566671102 SCRSystmClnngInhbtdDTEngNtWrmdUp 5;
BA_ "SPN" SG_ 2566671102 SCRSystmClnngInhbtdDTEngNtWrmdUp 6931;
BA_ "SigType" SG_ 2566671102 SCRSystmClnngInhbtdDTPrmnntSystm 5;
BA_ "SPN" SG_ 2566671102 SCRSystmClnngInhbtdDTPrmnntSystm 6930;
BA_ "SigType" SG_ 2566671102 SCRSystmClnngInhbtdDTTmprrySystm 5;
BA_ "SPN" SG_ 2566671102 SCRSystmClnngInhbtdDTTmprrySystm 6929;
BA_ "SigType" SG_ 2566671102 SCRSystmClnngInhbtdDTSystmTmeout 5;
BA_ "SPN" SG_ 2566671102 SCRSystmClnngInhbtdDTSystmTmeout 6928;
BA_ "SigType" SG_ 2566671102 SCRSystmClnngInhbtdDTSystmFltAct 5;
BA_ "SPN" SG_ 2566671102 SCRSystmClnngInhbtdDTSystmFltAct 6927;
BA_ "SigType" SG_ 2566671102 SCRSystmClnngInhbtdDTLwExhstTemp 5;
BA_ "SPN" SG_ 2566671102 SCRSystmClnngInhbtdDTLwExhstTemp 6926;
BA_ "SigType" SG_ 2566671102 SCRSystmClnngInhbtdDTPrkngBrkNtS 5;
BA_ "SPN" SG_ 2566671102 SCRSystmClnngInhbtdDTPrkngBrkNtS 6925;
BA_ "SigType" SG_ 2566671102 SCRSystmClnngInhbtdDTVhclSpdAbvA 5;
BA_ "SPN" SG_ 2566671102 SCRSystmClnngInhbtdDTVhclSpdAbvA 6924;
BA_ "SigType" SG_ 2566671102 SCRSystmClnngInhbtdDTOtOfNeutral 5;
BA_ "SPN" SG_ 2566671102 SCRSystmClnngInhbtdDTOtOfNeutral 6923;
BA_ "SigType" SG_ 2566671102 SCRSystmClnngInhbtdDTAcclPdlOffI 5;
BA_ "SPN" SG_ 2566671102 SCRSystmClnngInhbtdDTAcclPdlOffI 6922;
BA_ "SigType" SG_ 2566671102 SCRSystmClnngInhbtdDeToPTOActive 5;
BA_ "SPN" SG_ 2566671102 SCRSystmClnngInhbtdDeToPTOActive 6921;
BA_ "SigType" SG_ 2566671102 SCRSystmClnngInhbtdDTSrvcBrkActv 5;
BA_ "SPN" SG_ 2566671102 SCRSystmClnngInhbtdDTSrvcBrkActv 6920;
BA_ "SigType" SG_ 2566671102 SCRSystmClnngInhbtdDTCltchDsnggd 5;
BA_ "SPN" SG_ 2566671102 SCRSystmClnngInhbtdDTCltchDsnggd 6919;
BA_ "SigType" SG_ 2566671102 SCRSystmClnngInhbtdDTInhbtSwitch 5;
BA_ "SPN" SG_ 2566671102 SCRSystmClnngInhbtdDTInhbtSwitch 6918;
BA_ "SigType" SG_ 2566671102 SCRSystemCleaningInhibitedStatus 5;
BA_ "SPN" SG_ 2566671102 SCRSystemCleaningInhibitedStatus 6917;
BA_ "SigType" SG_ 2566671102 SCRSystemCleaningStatus 5;
BA_ "SPN" SG_ 2566671102 SCRSystemCleaningStatus 6916;
BA_ "SPN" SG_ 2566671102 SCRSystemCleaningLampCmd 6915;
BA_ "SigType" SG_ 2566670846 SCRSysAvgDistBetweenCleanEvents 1;
BA_ "SPN" SG_ 2566670846 SCRSysAvgDistBetweenCleanEvents 6940;
BA_ "SigType" SG_ 2566670846 SCRSysAvgTimeBetweenCleanEvents 1;
BA_ "SPN" SG_ 2566670846 SCRSysAvgTimeBetweenCleanEvents 6939;
BA_ "SigType" SG_ 2566670846 SCRSysTotalSysCleanManReq 1;
BA_ "SPN" SG_ 2566670846 SCRSysTotalSysCleanManReq 6938;
BA_ "SigType" SG_ 2566670846 SCRSysTotalSysCleanInhReq 1;
BA_ "SPN" SG_ 2566670846 SCRSysTotalSysCleanInhReq 6937;
BA_ "SigType" SG_ 2566670846 SCRSysTotalSysCleanEvents 1;
BA_ "SPN" SG_ 2566670846 SCRSysTotalSysCleanEvents 6936;
BA_ "SigType" SG_ 2566670846 SCRSysTotalCleanTime 1;
BA_ "SPN" SG_ 2566670846 SCRSysTotalCleanTime 6935;
BA_ "SigType" SG_ 2566670590 SCRSysAvgDistBetweenCleanEvents 1;
BA_ "SPN" SG_ 2566670590 SCRSysAvgDistBetweenCleanEvents 6947;
BA_ "SigType" SG_ 2566670590 SCRSysAvgTimeBetweenCleanEvents 1;
BA_ "SPN" SG_ 2566670590 SCRSysAvgTimeBetweenCleanEvents 6946;
BA_ "SigType" SG_ 2566670590 SCRSysTotalSysCleanManReq 1;
BA_ "SPN" SG_ 2566670590 SCRSysTotalSysCleanManReq 6945;
BA_ "SigType" SG_ 2566670590 SCRSysTotalSysCleanInhReq 1;
BA_ "SPN" SG_ 2566670590 SCRSysTotalSysCleanInhReq 6944;
BA_ "SigType" SG_ 2566670590 SCRSysTotalSysCleanEvents 1;
BA_ "SPN" SG_ 2566670590 SCRSysTotalSysCleanEvents 6943;
BA_ "SigType" SG_ 2566670590 SCRSysTotalSysCleanTime 1;
BA_ "SPN" SG_ 2566670590 SCRSysTotalSysCleanTime 6942;
BA_ "SPN" SG_ 2566670334 Axle12MonitoredTireCount 6962;
BA_ "SPN" SG_ 2566670334 Axle11MonitoredTireCount 6961;
BA_ "SPN" SG_ 2566670334 Axle10MonitoredTireCount 6960;
BA_ "SPN" SG_ 2566670334 Axle9MonitoredTireCount 6959;
BA_ "SPN" SG_ 2566670334 Axle8MonitoredTireCount 6958;
BA_ "SPN" SG_ 2566670334 Axle7MonitoredTireCount 6957;
BA_ "SPN" SG_ 2566670334 Axle6MonitoredTireCount 6956;
BA_ "SPN" SG_ 2566670334 Axle5MonitoredTireCount 6955;
BA_ "SPN" SG_ 2566670334 Axle4MonitoredTireCount 6954;
BA_ "SPN" SG_ 2566670334 Axle3MonitoredTireCount 6953;
BA_ "SPN" SG_ 2566670334 Axle2MonitoredTireCount 6952;
BA_ "SPN" SG_ 2566670334 Axle1MonitoredTireCount 6951;
BA_ "SigType" SG_ 2566670334 NumberOfTiresOnTheVehicle 1;
BA_ "SPN" SG_ 2566670334 NumberOfTiresOnTheVehicle 6950;
BA_ "SPN" SG_ 2566670334 NumberOfAxlesOnTheVehicle 6949;
BA_ "SigType" SG_ 2566670078 TireSensorIdentificationNumber 8;
BA_ "SPN" SG_ 2566670078 TireSensorIdentificationNumber 6966;
BA_ "SPN" SG_ 2566670078 TireSensorLocation 6965;
BA_ "SigType" SG_ 2566670078 TireSensorTireNumber 1;
BA_ "SPN" SG_ 2566670078 TireSensorTireNumber 6964;
BA_ "SigType" SG_ 2566670078 NumberOfTireSensors 1;
BA_ "SPN" SG_ 2566670078 NumberOfTireSensors 6963;
BA_ "SigType" SG_ 2566669822 TrWrelessSignalStrengthIndicator 1;
BA_ "SPN" SG_ 2566669822 TrWrelessSignalStrengthIndicator 6972;
BA_ "SPN" SG_ 2566669822 TireLocation 6971;
BA_ "SigType" SG_ 2566669822 TireSensorNumber 1;
BA_ "SPN" SG_ 2566669822 TireSensorNumber 6970;
BA_ "SigType" SG_ 2566669822 TtalNumberOfTireSensorsMonitored 1;
BA_ "SPN" SG_ 2566669822 TtalNumberOfTireSensorsMonitored 6969;
BA_ "SigType" SG_ 2566669822 AntennaNumber 1;
BA_ "SPN" SG_ 2566669822 AntennaNumber 6968;
BA_ "SigType" SG_ 2566669822 TotalNumberOfAntennasUsed 1;
BA_ "SPN" SG_ 2566669822 TotalNumberOfAntennasUsed 6967;
BA_ "SigType" SG_ 2566669310 OverTemp 1;
BA_ "SPN" SG_ 2566669310 OverTemp 6984;
BA_ "SigType" SG_ 2566669310 OverPressPercentageThreshold 1;
BA_ "SPN" SG_ 2566669310 OverPressPercentageThreshold 6983;
BA_ "SigType" SG_ 2566669310 ExtrmUndrPrssPercentageThreshold 1;
BA_ "SPN" SG_ 2566669310 ExtrmUndrPrssPercentageThreshold 6982;
BA_ "SigType" SG_ 2566669310 UnderPressPercentageThreshold 1;
BA_ "SPN" SG_ 2566669310 UnderPressPercentageThreshold 6981;
BA_ "SigType" SG_ 2566669310 ColdInflationPress 1;
BA_ "SPN" SG_ 2566669310 ColdInflationPress 6980;
BA_ "SPN" SG_ 2566669310 TireLocation 6979;
BA_ "SigType" SG_ 2566669054 RequiredTirePress 1;
BA_ "SPN" SG_ 2566669054 RequiredTirePress 6989;
BA_ "SigType" SG_ 2566669054 TirePress 1;
BA_ "SPN" SG_ 2566669054 TirePress 6988;
BA_ "SPN" SG_ 2566669054 TireLocation 6987;
BA_ "SigType" SG_ 2566668798 EngFl2InjctorMeteringRail1Press2 1;
BA_ "SPN" SG_ 2566668798 EngFl2InjctorMeteringRail1Press2 7513;
BA_ "SigType" SG_ 2566668798 EngFel2InjectorMeteringRail2Temp 1;
BA_ "SPN" SG_ 2566668798 EngFel2InjectorMeteringRail2Temp 7024;
BA_ "SigType" SG_ 2566668798 EngFel2InjectorMeteringRail1Temp 1;
BA_ "SPN" SG_ 2566668798 EngFel2InjectorMeteringRail1Temp 7023;
BA_ "SigType" SG_ 2566668798 EngFl2InjectorMeteringRail2Press 1;
BA_ "SPN" SG_ 2566668798 EngFl2InjectorMeteringRail2Press 7022;
BA_ "SigType" SG_ 2566668798 EngFl2InjectorMeteringRail1Press 1;
BA_ "SPN" SG_ 2566668798 EngFl2InjectorMeteringRail1Press 7021;
BA_ "SigType" SG_ 2566668542 EngFuel2PumpHydPress 1;
BA_ "SPN" SG_ 2566668542 EngFuel2PumpHydPress 7019;
BA_ "SigType" SG_ 2566668542 EngFuel2PumpHydDirectionalValve 1;
BA_ "SPN" SG_ 2566668542 EngFuel2PumpHydDirectionalValve 7018;
BA_ "SigType" SG_ 2566668542 EngFuel2PumpHydSwashPlateAngle 1;
BA_ "SPN" SG_ 2566668542 EngFuel2PumpHydSwashPlateAngle 7017;
BA_ "SigType" SG_ 2566668542 EngFuel2PumpHydFlowCtrlValve 1;
BA_ "SPN" SG_ 2566668542 EngFuel2PumpHydFlowCtrlValve 7016;
BA_ "SigType" SG_ 2566668286 EngStagedTurboSolenoidStatus 1;
BA_ "SPN" SG_ 2566668286 EngStagedTurboSolenoidStatus 7025;
BA_ "SigType" SG_ 2566668030 HtExchngerDebrisPurgeApproaching 5;
BA_ "SPN" SG_ 2566668030 HtExchngerDebrisPurgeApproaching 7036;
BA_ "SigType" SG_ 2566668030 HeatExchangerDebrisPurgeStatus 5;
BA_ "SPN" SG_ 2566668030 HeatExchangerDebrisPurgeStatus 7035;
BA_ "SigType" SG_ 2566667774 EngEndBearing8Temp 1;
BA_ "SPN" SG_ 2566667774 EngEndBearing8Temp 7050;
BA_ "SigType" SG_ 2566667774 EngEndBearing7Temp 1;
BA_ "SPN" SG_ 2566667774 EngEndBearing7Temp 7049;
BA_ "SigType" SG_ 2566667774 EngEndBearing6Temp 1;
BA_ "SPN" SG_ 2566667774 EngEndBearing6Temp 7048;
BA_ "SigType" SG_ 2566667774 EngEndBearing5Temp 1;
BA_ "SPN" SG_ 2566667774 EngEndBearing5Temp 7047;
BA_ "SigType" SG_ 2566667774 EngEndBearing4Temp 1;
BA_ "SPN" SG_ 2566667774 EngEndBearing4Temp 7046;
BA_ "SigType" SG_ 2566667774 EngEndBearing3Temp 1;
BA_ "SPN" SG_ 2566667774 EngEndBearing3Temp 7045;
BA_ "SigType" SG_ 2566667774 EngEndBearing2Temp 1;
BA_ "SPN" SG_ 2566667774 EngEndBearing2Temp 7044;
BA_ "SigType" SG_ 2566667774 EngEndBearing1Temp 1;
BA_ "SPN" SG_ 2566667774 EngEndBearing1Temp 7043;
BA_ "SigType" SG_ 2566667518 EngEndBearing16Temp 1;
BA_ "SPN" SG_ 2566667518 EngEndBearing16Temp 7058;
BA_ "SigType" SG_ 2566667518 EngEndBearing15Temp 1;
BA_ "SPN" SG_ 2566667518 EngEndBearing15Temp 7057;
BA_ "SigType" SG_ 2566667518 EngEndBearing14Temp 1;
BA_ "SPN" SG_ 2566667518 EngEndBearing14Temp 7056;
BA_ "SigType" SG_ 2566667518 EngEndBearing13Temp 1;
BA_ "SPN" SG_ 2566667518 EngEndBearing13Temp 7055;
BA_ "SigType" SG_ 2566667518 EngEndBearing12Temp 1;
BA_ "SPN" SG_ 2566667518 EngEndBearing12Temp 7054;
BA_ "SigType" SG_ 2566667518 EngEndBearing11Temp 1;
BA_ "SPN" SG_ 2566667518 EngEndBearing11Temp 7053;
BA_ "SigType" SG_ 2566667518 EngEndBearing10Temp 1;
BA_ "SPN" SG_ 2566667518 EngEndBearing10Temp 7052;
BA_ "SigType" SG_ 2566667518 EngEndBearing9Temp 1;
BA_ "SPN" SG_ 2566667518 EngEndBearing9Temp 7051;
BA_ "SigType" SG_ 2566667262 EngEndBearing20Temp 1;
BA_ "SPN" SG_ 2566667262 EngEndBearing20Temp 7062;
BA_ "SigType" SG_ 2566667262 EngEndBearing19Temp 1;
BA_ "SPN" SG_ 2566667262 EngEndBearing19Temp 7061;
BA_ "SigType" SG_ 2566667262 EngEndBearing18Temp 1;
BA_ "SPN" SG_ 2566667262 EngEndBearing18Temp 7060;
BA_ "SigType" SG_ 2566667262 EngEndBearing17Temp 1;
BA_ "SPN" SG_ 2566667262 EngEndBearing17Temp 7059;
BA_ "SigType" SG_ 2499558142 GsFlSpplyShtoffValve2IntakePress 1;
BA_ "SPN" SG_ 2499558142 GsFlSpplyShtoffValve2IntakePress 7066;
BA_ "SigType" SG_ 2499558142 GsFlSpplyShtoffValve1IntakePress 1;
BA_ "SPN" SG_ 2499558142 GsFlSpplyShtoffValve1IntakePress 7065;
BA_ "SigType" SG_ 2499558142 GasFuelSupplyUnitIntakePress 1;
BA_ "SPN" SG_ 2499558142 GasFuelSupplyUnitIntakePress 7064;
BA_ "SigType" SG_ 2499558142 EngGasFuelSupplyPress2 1;
BA_ "SPN" SG_ 2499558142 EngGasFuelSupplyPress2 7063;
BA_ "SigType" SG_ 2499557886 PlantInertGasSupplyOutletPress 1;
BA_ "SPN" SG_ 2499557886 PlantInertGasSupplyOutletPress 7068;
BA_ "SigType" SG_ 2499557886 PlantGasFuelSupplyOutletPress 1;
BA_ "SPN" SG_ 2499557886 PlantGasFuelSupplyOutletPress 7067;
BA_ "SigType" SG_ 2499557630 EngOilMist8Concentration 1;
BA_ "SPN" SG_ 2499557630 EngOilMist8Concentration 7078;
BA_ "SigType" SG_ 2499557630 EngOilMist7Concentration 1;
BA_ "SPN" SG_ 2499557630 EngOilMist7Concentration 7077;
BA_ "SigType" SG_ 2499557630 EngOilMist6Concentration 1;
BA_ "SPN" SG_ 2499557630 EngOilMist6Concentration 7076;
BA_ "SigType" SG_ 2499557630 EngOilMist5Concentration 1;
BA_ "SPN" SG_ 2499557630 EngOilMist5Concentration 7075;
BA_ "SigType" SG_ 2499557630 EngOilMist4Concentration 1;
BA_ "SPN" SG_ 2499557630 EngOilMist4Concentration 7074;
BA_ "SigType" SG_ 2499557630 EngOilMist3Concentration 1;
BA_ "SPN" SG_ 2499557630 EngOilMist3Concentration 7073;
BA_ "SigType" SG_ 2499557630 EngOilMist2Concentration 1;
BA_ "SPN" SG_ 2499557630 EngOilMist2Concentration 7072;
BA_ "SigType" SG_ 2499557630 EngOilMist1Concentration 1;
BA_ "SPN" SG_ 2499557630 EngOilMist1Concentration 7071;
BA_ "SigType" SG_ 2499557374 EngOilMist10Concentration 1;
BA_ "SPN" SG_ 2499557374 EngOilMist10Concentration 7080;
BA_ "SigType" SG_ 2499557374 EngOilMist9Concentration 1;
BA_ "SPN" SG_ 2499557374 EngOilMist9Concentration 7079;
BA_ "SigType" SG_ 2499557118 InertGasSupplyValvePos 1;
BA_ "SPN" SG_ 2499557118 InertGasSupplyValvePos 7442;
BA_ "SigType" SG_ 2499557118 GasFuelSupplyBleedValve3Pos 1;
BA_ "SPN" SG_ 2499557118 GasFuelSupplyBleedValve3Pos 7085;
BA_ "SigType" SG_ 2499557118 GasFuelSupplyBleedValve2Pos 1;
BA_ "SPN" SG_ 2499557118 GasFuelSupplyBleedValve2Pos 7084;
BA_ "SigType" SG_ 2499557118 GasFuelSupplyBleedValve1Pos 1;
BA_ "SPN" SG_ 2499557118 GasFuelSupplyBleedValve1Pos 7083;
BA_ "SigType" SG_ 2499557118 GasFuelSupplyShutoffValve2Pos 1;
BA_ "SPN" SG_ 2499557118 GasFuelSupplyShutoffValve2Pos 7082;
BA_ "SigType" SG_ 2499557118 GasFuelSupplyShutoffValve1Pos 1;
BA_ "SPN" SG_ 2499557118 GasFuelSupplyShutoffValve1Pos 7081;
BA_ "SigType" SG_ 2566665726 TwoMotorSpd 1;
BA_ "SPN" SG_ 2566665726 TwoMotorSpd 7466;
BA_ "SigType" SG_ 2566665726 Htr 1;
BA_ "SPN" SG_ 2566665726 Htr 7086;
BA_ "SigType" SG_ 2499556606 EngInjectorMeteringRail2Press2 1;
BA_ "SPN" SG_ 2499556606 EngInjectorMeteringRail2Press2 7099;
BA_ "SigType" SG_ 2499556606 EngInjectorMeteringRail2Press1 1;
BA_ "SPN" SG_ 2499556606 EngInjectorMeteringRail2Press1 7098;
BA_ "SigType" SG_ 2499556606 EngInjectorMeteringRail1Press2 1;
BA_ "SPN" SG_ 2499556606 EngInjectorMeteringRail1Press2 7097;
BA_ "SigType" SG_ 2499556606 EngInjectorMeteringRail1Press1 1;
BA_ "SPN" SG_ 2499556606 EngInjectorMeteringRail1Press1 7096;
BA_ "SigType" SG_ 2499556350 EngInjctrMtringRail2DesiredPress 1;
BA_ "SPN" SG_ 2499556350 EngInjctrMtringRail2DesiredPress 7101;
BA_ "SigType" SG_ 2499556350 EngInjctrMtringRail1DesiredPress 1;
BA_ "SPN" SG_ 2499556350 EngInjctrMtringRail1DesiredPress 7100;
BA_ "SPN" SG_ 2499556094 HtrPwrSupplyDiagnosticStatus 7330;
BA_ "SPN" SG_ 2499556094 HtrPwrSupplyPreliminaryFMI 7329;
BA_ "SPN" SG_ 2499556094 PwrSupplyDiagnosticStatus 7328;
BA_ "SPN" SG_ 2499556094 PwrSupplyPreliminaryFMI 7327;
BA_ "SPN" SG_ 2499556094 InputDiagnosticStatus 7326;
BA_ "SPN" SG_ 2499556094 InputPreliminaryFMI 7325;
BA_ "SPN" SG_ 2499556094 HtrLowSideDriverDiagnosticStatus 7324;
BA_ "SPN" SG_ 2499556094 HtrLowSideDriverPreliminaryFMI 7323;
BA_ "SPN" SG_ 2499556094 HtrHiSideDriverDiagnosticStatus 7322;
BA_ "SPN" SG_ 2499556094 HtrHiSideDriverPreliminaryFMI 7321;
BA_ "SigType" SG_ 2566664702 DEFTankTemp 1;
BA_ "SPN" SG_ 2566664702 DEFTankTemp 7607;
BA_ "SigType" SG_ 2566664702 DEFTankVolume 1;
BA_ "SPN" SG_ 2566664702 DEFTankVolume 7606;
BA_ "SigType" SG_ 2566664702 DEFHtrCircuitBreaker 5;
BA_ "SPN" SG_ 2566664702 DEFHtrCircuitBreaker 7588;
BA_ "SigType" SG_ 2566664702 AAT 1;
BA_ "SPN" SG_ 2566664702 AAT 7441;
BA_ "SigType" SG_ 2566664702 EngLoadReq 5;
BA_ "SPN" SG_ 2566664702 EngLoadReq 7503;
BA_ "SigType" SG_ 2566664702 EngSpdIncreaseReq 5;
BA_ "SPN" SG_ 2566664702 EngSpdIncreaseReq 7502;
BA_ "SigType" SG_ 2566664702 ActiveRegenInhibitedDueToLowEP 5;
BA_ "SPN" SG_ 2566664702 ActiveRegenInhibitedDueToLowEP 7440;
BA_ "SigType" SG_ 2566664702 ThermalManagementStatus 5;
BA_ "SPN" SG_ 2566664702 ThermalManagementStatus 7332;
BA_ "SigType" SG_ 2633773310 SCROprtrIndcmntOvrrdTmeRemaining 1;
BA_ "SPN" SG_ 2633773310 SCROprtrIndcmntOvrrdTmeRemaining 7344;
BA_ "SigType" SG_ 2633773310 SCROprtrIndcmntOvrrdRnwlRequired 5;
BA_ "SPN" SG_ 2633773310 SCROprtrIndcmntOvrrdRnwlRequired 7343;
BA_ "SPN" SG_ 2633773310 SCROpratorInducementOverrideMode 7342;
BA_ "SigType" SG_ 2633773310 SCROprtrIndcmntEmrgncyOvrrdTtlRs 1;
BA_ "SPN" SG_ 2633773310 SCROprtrIndcmntEmrgncyOvrrdTtlRs 7341;
BA_ "SigType" SG_ 2633773054 FrSpprssnCmprssdArFmSystmArPress 1;
BA_ "SPN" SG_ 2633773054 FrSpprssnCmprssdArFmSystmArPress 7350;
BA_ "SigType" SG_ 2633773054 FrSuppressionClassBFoamTankLevel 1;
BA_ "SPN" SG_ 2633773054 FrSuppressionClassBFoamTankLevel 7349;
BA_ "SigType" SG_ 2633773054 FrSuppressionClassAFoamTankLevel 1;
BA_ "SPN" SG_ 2633773054 FrSuppressionClassAFoamTankLevel 7348;
BA_ "SigType" SG_ 2633773054 FireSuppressionWaterTankLevel 1;
BA_ "SPN" SG_ 2633773054 FireSuppressionWaterTankLevel 7347;
BA_ "SigType" SG_ 2566663934 WastegateAct2MotorCurDis 5;
BA_ "SPN" SG_ 2566663934 WastegateAct2MotorCurDis 7710;
BA_ "SigType" SG_ 2566663934 CompressorBypassAct2MotorCurDis 5;
BA_ "SPN" SG_ 2566663934 CompressorBypassAct2MotorCurDis 7709;
BA_ "SigType" SG_ 2566663934 CompressorBypassAct1MotorCurDis 5;
BA_ "SPN" SG_ 2566663934 CompressorBypassAct1MotorCurDis 7708;
BA_ "SigType" SG_ 2566663934 EngThrttlVlv1MotorCurrentDisable 5;
BA_ "SPN" SG_ 2566663934 EngThrttlVlv1MotorCurrentDisable 7383;
BA_ "SigType" SG_ 2566663934 EngCylHdBypssActtr1MtrCrrntDsble 5;
BA_ "SPN" SG_ 2566663934 EngCylHdBypssActtr1MtrCrrntDsble 7382;
BA_ "SigType" SG_ 2566663934 EngTrbWstgtActtr1MtrCrrntDisable 5;
BA_ "SPN" SG_ 2566663934 EngTrbWstgtActtr1MtrCrrntDisable 7381;
BA_ "SigType" SG_ 2566663934 EngTrbCmprssrBlwffActtr1MtrCrrnt 5;
BA_ "SPN" SG_ 2566663934 EngTrbCmprssrBlwffActtr1MtrCrrnt 7380;
BA_ "SigType" SG_ 2566663678 EngFl2InjectorMeteringRail1Temp2 1;
BA_ "SPN" SG_ 2566663678 EngFl2InjectorMeteringRail1Temp2 7514;
BA_ "SigType" SG_ 2566663678 LNGTank2VaporPress 1;
BA_ "SPN" SG_ 2566663678 LNGTank2VaporPress 6788;
BA_ "SigType" SG_ 2566663678 LNGTank1VaporPress 1;
BA_ "SPN" SG_ 2566663678 LNGTank1VaporPress 6787;
VAL_ 3221225472 TirePressThresholdDetection 7 "Not available" 6 "Error indicator" 5 "Not defined" 4 "Extreme under pressure" 3 "Under pressure" 2 "No warning pressure" 1 "Over pressure" 0 "Extreme over pressure" ;
VAL_ 3221225472 CTIWheelEndElectricalFault 3 "Not Supported" 2 "Error" 1 "Not Defined" 0 "Ok  No Fault" ;
VAL_ 3221225472 CTITireStatus 3 "Not Supported" 2 "Error" 1 "Tire leak detected" 0 "Ok no fault" ;
VAL_ 3221225472 CTIWheelSensorStatus 3 "Not Supported" 2 "Not Defined" 1 "On tire is polled" 0 "Off / isolated from CTI Pressure Controller" ;
VAL_ 3221225472 EngTurningGearEngaged 1 "Engaged" 0 "Not engaged" 3 "Not available" 2 "Error" ;
VAL_ 2499548158 RightRearCabDoorLatchPos 7 "Not Available" 6 "Error" 5 "Reserved" 4 "Reserved" 3 "Reserved" 2 "Door Latch Ajar" 1 "Door Latch Fully Closed/Latched" 0 "Door Latch Open" ;
VAL_ 2499548158 LeftRearCabDoorLatchPos 7 "Not Available" 6 "Error" 5 "Reserved" 4 "Reserved" 3 "Reserved" 2 "Door Latch Ajar" 1 "Door Latch Fully Closed/Latched" 0 "Door Latch Open" ;
VAL_ 2499548158 RightFrontCabDoorLatchPos 7 "Not Available" 6 "Error" 5 "Reserved" 4 "Reserved" 3 "Reserved" 2 "Door Latch Ajar" 1 "Door Latch Fully Closed/Latched" 0 "Door Latch Open" ;
VAL_ 2499548158 LeftFrontCabDoorLatchPos 7 "Not Available" 6 "Error" 5 "Reserved" 4 "Reserved" 3 "Reserved" 2 "Door Latch Ajar" 1 "Door Latch Fully Closed/Latched" 0 "Door Latch Open" ;
VAL_ 2499547902 MirrorRight2HeatCmd 3 "Take no action" 2 "Reserved" 1 "Mirror heat on" 0 "Mirror heat off" ;
VAL_ 2499547902 MirrorLeft2HeatCmd 3 "Take no action" 2 "Reserved" 1 "Mirror heat on" 0 "Mirror heat off" ;
VAL_ 2499547902 MirrorRight1HeatCmd 3 "Take no action" 2 "Reserved" 1 "Mirror heat on" 0 "Mirror heat off" ;
VAL_ 2499547902 MirrorLeft1HeatCmd 3 "Take no action" 2 "Reserved" 1 "Mirror heat on" 0 "Mirror heat off" ;
VAL_ 2499547902 MirrorRight2VerticalCmd 3 "Take no action" 2 "Reserved" 1 "Move down" 0 "Move up" ;
VAL_ 2499547902 MirrorRight2HorizontalCmd 3 "Take no action" 2 "Reserved" 1 "Move right" 0 "Move left" ;
VAL_ 2499547902 MirrorLeft2VerticalCmd 3 "Take no action" 2 "Reserved" 1 "Move down" 0 "Move up" ;
VAL_ 2499547902 MirrorLeft2HorizontalCmd 3 "Take no action" 2 "Reserved" 1 "Move right" 0 "Move left" ;
VAL_ 2499547902 MirrorRight1VerticalCmd 3 "Take no action" 2 "Reserved" 1 "Move down" 0 "Move up" ;
VAL_ 2499547902 MirrorRight1HorizontalCmd 3 "Take no action" 2 "Reserved" 1 "Move right" 0 "Move left" ;
VAL_ 2499547902 MirrorLeft1VerticalCmd 3 "Take no action" 2 "Reserved" 1 "Move down" 0 "Move up" ;
VAL_ 2499547902 MirrorLeft1HorizontalCmd 3 "Take no action" 2 "Reserved" 1 "Move right" 0 "Move left" ;
VAL_ 2499547902 RightRearWindowPosCmd 7 "Take no action" 6 "Reserved" 5 "Reserved" 4 "Reserved" 3 "Window auto down" 2 "Window auto up" 1 "Window move down" 0 "Window move up" ;
VAL_ 2499547902 LeftRearWindowPosCmd 7 "Take no action" 6 "Reserved" 5 "Reserved" 4 "Reserved" 3 "Window auto down" 2 "Window auto up" 1 "Window move down" 0 "Window move up" ;
VAL_ 2499547902 RightFrontWindowPosCmd 7 "Take no action" 6 "Reserved" 5 "Reserved" 4 "Reserved" 3 "Window auto down" 2 "Window auto up" 1 "Window move down" 0 "Window move up" ;
VAL_ 2499547902 LeftFrontWindowPosCmd 7 "Take no action" 6 "Reserved" 5 "Reserved" 4 "Reserved" 3 "Window auto down" 2 "Window auto up" 1 "Window move down" 0 "Window move up" ;
VAL_ 2499547902 RemoteCabDoorLockReq 7 "Take no action" 6 "Reserved" 5 "Request lock all cab door latches" 4 "Request unlock all cab door latches" 3 "Request unlock right rear cab door latch" 2 "Request unlock left rear cab door latch" 1 "Request unlock right front cab door latch" 0 "Request unlock left front cab door latch" ;
VAL_ 2499547902 DoorsLockActCmd 7 "Take no action" 6 "Reserved" 5 "Lock all cab door latches" 4 "Unlock all cab door latches" 3 "Unlock right rear cab door latch" 2 "Unlock left rear cab door latch" 1 "Unlock right front cab door latch" 0 "Unlock left front cab door latch" ;
VAL_ 2431710718 AutomaticEngStartConsentSummary 3 "Not available" 2 "Error" 1 "Consent" 0 "No consent" ;
VAL_ 2431710718 OpEngStartConsentSummary 3 "Not available" 2 "Error" 1 "Consent" 0 "No consent" ;
VAL_ 2431710718 ReqLatchStatus 15 "Not available" 6 "Start request unlatched, start could not be completed because the starter command was not successful" 5 "Start request unlatched, start aborted due to abort request" 4 "Start request unlatched, consent not established within allowed time" 3 "Start request unlatched, start completed" 2 "Start request latched, consent confirmed" 1 "Start request latched, waiting for consent" 0 "Start request not received" ;
VAL_ 2431710718 StarterCmd 7 "Don't care / Take no action" 3 "Command withdrawn" 2 "Command active for starter 2" 1 "Command active for starter 1" 0 "Command not active" ;
VAL_ 2431710718 CtrlMessageRate 3 "Not available" 2 "Reserved" 1 "Once every 250 ms or on change but no faster than 20 ms" 0 "Once every 20 ms" ;
VAL_ 2431708670 Starter2Feedback 7 "Not available" 4 "Starter command unlatched,  start aborted by starter controller" 3 "Starter command unlatched,  start abort command received from arbitrator" 2 "Starter command unlatched,  start completed" 1 "Starter command latched" 0 "Starter not commanded" ;
VAL_ 2431708670 Starter1Feedback 7 "Not available" 4 "Starter command unlatched,  start aborted by starter controller" 3 "Starter command unlatched,  start abort command received from arbitrator" 2 "Starter command unlatched,  start completed" 1 "Starter command latched" 0 "Starter not commanded" ;
VAL_ 2431708670 AbortReq 3 "Don't care / Take no action" 2 "Reserved" 1 "Abort requested" 0 "Abort not requested" ;
VAL_ 2431708670 Consent 7 "Not available" 3 "Consent to both" 2 "Consent to automatic start only" 1 "Consent to operator-requested start only" 0 "No consent" ;
VAL_ 2431708670 Req 3 "Not available" 2 "Start requested,  automatic type" 1 "Start requested,  operator type" 0 "Start not requested" ;
VAL_ 2565926142 NOxSnsr2SelfDiagStatus 0 "Diagnosis not active" 7 "Not Supported" 4 "NOx Sensor ATO2 Self Diagnosis not possible" 3 "NOx Sensor ATO2 Self Diagnosis aborted" 2 "NOx Sensor ATO2 Self Diagnosis Result Complete" 1 "NOx Sensor ATO2 Self Diagnosis active flag" ;
VAL_ 2565926142 GasSnsr2HtrCtrl 3 "Heater off" 2 "Preheat 1" 1 "Preheat 2" 0 "Automatic" ;
VAL_ 2565926142 WRPercentO22ReadingStable 3 "Not available" 2 "Error" 1 "Stable" 0 "Not stable" ;
VAL_ 2565926142 NOx2ReadingStable 3 "Not available" 2 "Error" 1 "Stable" 0 "Not stable" ;
VAL_ 2565926142 GasSnsr2AtTemp 3 "Not available" 2 "Error" 1 "In range" 0 "Not in range" ;
VAL_ 2565926142 GasSnsr2PwrInRange 3 "Not available" 2 "Error" 1 "In range" 0 "Not in range" ;
VAL_ 2565925886 NOxSnsr2SelfDiagStatus 7 "Not Supported" 4 "NOx Sensor ATI2 Self Diagnosis not possible" 3 "NOx Sensor ATI2 Self Diagnosis aborted" 2 "NOx Sensor ATI2 Self Diagnosis Result Complete" 1 "NOx Sensor ATI2 Self Diagnosis active flag" 0 "Diagnosis not active" ;
VAL_ 2565925886 GasSnsr2HtrCtrl 3 "Heater off" 2 "Preheat 1" 1 "Preheat 2" 0 "Automatic" ;
VAL_ 2565925886 WRPercentO22ReadingStable 3 "Not available" 2 "Error" 1 "Stable" 0 "Not stable" ;
VAL_ 2565925886 SCRInNOx2ReadingStable 3 "Not available" 2 "Error" 1 "Stable" 0 "Not stable" ;
VAL_ 2565925886 GasSnsr2AtTemp 3 "Not available" 2 "Error" 1 "In range" 0 "Not in range" ;
VAL_ 2565925886 GasSnsr2PwrInRange 3 "Not available" 2 "Error" 1 "In range" 0 "Not in range" ;
VAL_ 2565925630 NOxSnsr2SelfDiagStatus 7 "Not Supported" 4 "NOx Sensor ATO1 Self Diagnosis not possible" 3 "NOx Sensor ATO1 Self Diagnosis aborted" 2 "NOx Sensor ATO1 Self Diagnosis Result Complete" 1 "NOx Sensor ATO1 Self Diagnosis active flag" 0 "Diagnosis not active" ;
VAL_ 2565925630 Snsr2HtrCtrl 3 "Heater off" 2 "Preheat 1" 1 "Preheat 2" 0 "Automatic" ;
VAL_ 2565925630 WRPercentO22ReadingStable 3 "Not available" 2 "Error" 1 "Stable" 0 "Not stable" ;
VAL_ 2565925630 NOx2ReadingStable 3 "Not available" 2 "Error" 1 "Stable" 0 "Not stable" ;
VAL_ 2565925630 Snsr2AtTemp 3 "Not available" 2 "Error" 1 "In range" 0 "Not in range" ;
VAL_ 2565925630 Snsr2PwrInRange 3 "Not available" 2 "Error" 1 "In range" 0 "Not in range" ;
VAL_ 2565925374 NOxSnsr2SelfDiagStatus 7 "Not Supported" 4 "NOx Sensor ATI1 Self Diagnosis not possible" 3 "NOx Sensor ATI1 Self Diagnosis aborted" 2 "NOx Sensor ATI1 Self Diagnosis Result Complete" 1 "NOx Sensor ATI1 Self Diagnosis active flag" 0 "Diagnosis not active" ;
VAL_ 2565925374 Snsr2HtrCtrl 3 "Heater off" 2 "Preheat 1" 1 "Preheat 2" 0 "Automatic" ;
VAL_ 2565925374 WRPercentO22ReadingStable 3 "Not available" 2 "Error" 1 "Stable" 0 "Not stable" ;
VAL_ 2565925374 SCRInNOx2ReadingStable 3 "Not available" 2 "Error" 1 "Stable" 0 "Not stable" ;
VAL_ 2565925374 Snsr2AtTemp 3 "Not available" 2 "Error" 1 "In range" 0 "Not in range" ;
VAL_ 2565925374 Snsr2PwrInRange 3 "Not available" 2 "Error" 1 "In range" 0 "Not in range" ;
VAL_ 2566838014 ShutdownSw 3 "Not Available" 2 "Error" 1 "On" 0 "Off" ;
VAL_ 2566838014 PropulsionDisableSw 3 "Not Available" 2 "Error" 1 "On" 0 "Off" ;
VAL_ 2566838014 HybrdSystmBrkPdlRgnrtvBrkngDsblS 3 "Not Available" 2 "Error" 1 "Brake pedal regenerative braking disable switch is on" 0 "Brake pedal regenerative braking disable switch is off" ;
VAL_ 2566838014 HybrdSystmRgnrtvBrkngDsbleSwitch 3 "Not Available" 2 "Error" 1 "Regenerative Braking  Disable Switch is on" 0 "Regenerative Braking Disable Switch is off" ;
VAL_ 2566838014 HybrdSystmOffBrdChrgrCnnctnSttus 3 "Not available" 2 "Error" 1 "Off-board charger is connected" 0 "Off-board charger is not connected" ;
VAL_ 2566838014 HybrdSystmPwrElctrncsClntLvlSwtc 3 "Not Available" 2 "Error" 1 "Coolant Level is sufficient" 0 "Coolant Level is not sufficient" ;
VAL_ 2566838014 HybrdSystmPrplsnClantLevelSwitch 3 "Not Available" 2 "Error" 1 "Coolant Level is sufficient" 0 "Coolant Level is not sufficient" ;
VAL_ 2566838014 HybrdSystmPrtctionOverrideSwitch 3 "Not Available" 2 "Error" 1 "Active" 0 "Not Active" ;
VAL_ 2566687998 RegenSt 15 "Not Available" 3 "Regeneration is active and has been initiated due to time based conditions" 2 "Regeneration is active and has been initiated because of sensor conditions" 1 "Regneration is active and has been initiated by request via SPN 6783" 0 "Regeneration is not active" ;
VAL_ 2566687998 RegenStatus 3 "not available" 2 "Regeneration failed" 1 "Regeneration was successful" 0 "Regeneration attempt has not occurred during this operational cycle" ;
VAL_ 2566687998 HtrSt 3 "Heater is off" 2 "Heater is in ramp up mode" 1 "Heater is being held at a specified level" 0 "Heater is in closed loop control" ;
VAL_ 2566687742 PwrSupply 3 "Unavailable" 2 "Error" 1 "On" 0 "Off" ;
VAL_ 2566687742 DetectionStatus 15 "Not supported" 8 "Halt particulate matter detection" 7 "Sensor regeneration did not complete due to system parameters out of range" 6 "Relearning particulate sensor resistance after particulate sensor regeneration" 5 "Heater diagnostics test" 4 "Cooling after particulate sensor regeneration" 3 "Heater is active for particulate sensor regeneration" 2 "Particulate matter detection" 1 "Waiting for dew point" 0 "Initialization for particulate matter detection" ;
VAL_ 2365348350 EngLoadShareStatus 15 "Unavailable" 14 "Error" 4 "Unloading" 3 "Loading" 2 "Slave" 1 "Master" 0 "Offline" ;
VAL_ 2365348350 EngUnloadStatus 3 "Not Available" 2 "Error" 1 "Requested" 0 "Not Requested" ;
VAL_ 2633782014 BinWeighingErrorStatus 15 "Not available / not applicable" 3 "Weighing error: empty bin lifted" 2 "Weighing error: bin lifted" 1 "Bad lift cycle" 0 "No error" ;
VAL_ 2365346302 LiftAxle2Status 7 "Not available" 6 "Error" 5 "Loading" 4 "Lowering" 3 "Up" 2 "Lifting" 1 "Unloading" 0 "Down" ;
VAL_ 2365346302 LiftAxle1Status 7 "Not available" 6 "Error" 5 "Loading" 4 "Lowering" 3 "Up" 2 "Lifting" 1 "Unloading" 0 "Down" ;
VAL_ 2566672638 DeliveryTransactionStatus 15 "Not Available" 14 "Error" 2 "Transaction Complete" 1 "Transaction In Progress" 0 "Transaction Not In Progress" ;
VAL_ 2566672638 HaulModeStatus 15 "Not Available" 14 "Error" 5 "Unloaded" 4 "Unloading" 3 "Loaded" 2 "Approaching Loaded" 1 "Loading" 0 "Not in Haul Mode" ;
VAL_ 2566672382 PayloadWeightSensor8Status 3 "Not available" 2 "Error" 1 "Sensor degraded" 0 "Sensor fully functional" ;
VAL_ 2566672382 PayloadWeightSensor7Status 3 "Not available" 2 "Error" 1 "Sensor degraded" 0 "Sensor fully functional" ;
VAL_ 2566672382 PayloadWeightSensor6Status 3 "Not available" 2 "Error" 1 "Sensor degraded" 0 "Sensor fully functional" ;
VAL_ 2566672382 PayloadWeightSensor5Status 3 "Not available" 2 "Error" 1 "Sensor degraded" 0 "Sensor fully functional" ;
VAL_ 2566672382 PayloadWeightSensor4Status 3 "Not available" 2 "Error" 1 "Sensor degraded" 0 "Sensor fully functional" ;
VAL_ 2566672382 PayloadWeightSensor3Status 3 "Not available" 2 "Error" 1 "Sensor degraded" 0 "Sensor fully functional" ;
VAL_ 2566672382 PayloadWeightSensor2Status 3 "Not available" 2 "Error" 1 "Sensor degraded" 0 "Sensor fully functional" ;
VAL_ 2566672382 PayloadWeightSensor1Status 2 "Error" 1 "Sensor degraded" 0 "Sensor fully functional" 3 "Not available" ;
VAL_ 2566671614 SCROprtrInducementOverrideEnable 3 "Not available" 2 "SAE Reserved" 1 "Override allowed" 0 "Override not allowed" ;
VAL_ 2566671102 SCRSystemCleaningForcedStatus 7 "not available" 6 "Reserved for SAE Assignment" 5 "Reserved for SAE Assignment" 4 "Reserved for SAE Assignment" 3 "Reserved for SAE Assignment" 2 "Active, Forced by Service Tool " 1 "Active, Forced by Switch" 0 "Not Active" ;
VAL_ 2566671102 SCRSystmClnngAtmtcIntationConfig 3 "not available" 2 "reserved for SAE assignment" 1 "enabled" 0 "not enabled" ;
VAL_ 2566671102 SCRSystmClnngInhbtdDTVhclSpdBlwA 3 "not available" 2 "reserved for SAE assignment" 1 "inhibited" 0 "not inhibited" ;
VAL_ 2566671102 SCRSystmClnngInhbtdDTEngNtWrmdUp 3 "not available" 2 "reserved for SAE assignment" 1 "inhibited" 0 "not inhibited" ;
VAL_ 2566671102 SCRSystmClnngInhbtdDTPrmnntSystm 3 "not available" 2 "reserved for SAE assignment" 1 "inhibited" 0 "not inhibited" ;
VAL_ 2566671102 SCRSystmClnngInhbtdDTTmprrySystm 3 "not available" 2 "reserved for SAE assignment" 1 "inhibited" 0 "not inhibited" ;
VAL_ 2566671102 SCRSystmClnngInhbtdDTSystmTmeout 3 "not available" 2 "reserved for SAE assignment" 1 "inhibited" 0 "not inhibited" ;
VAL_ 2566671102 SCRSystmClnngInhbtdDTSystmFltAct 3 "not available" 2 "reserved for SAE assignment" 1 "inhibited" 0 "not inhibited" ;
VAL_ 2566671102 SCRSystmClnngInhbtdDTLwExhstTemp 3 "not available" 2 "reserved for SAE assignment" 1 "inhibited" 0 "not inhibited" ;
VAL_ 2566671102 SCRSystmClnngInhbtdDTPrkngBrkNtS 3 "not available" 2 "reserved for SAE assignment" 1 "inhibited" 0 "not inhibited" ;
VAL_ 2566671102 SCRSystmClnngInhbtdDTVhclSpdAbvA 3 "not available" 2 "reserved for SAE assignment" 1 "inhibited" 0 "not inhibited" ;
VAL_ 2566671102 SCRSystmClnngInhbtdDTOtOfNeutral 3 "not available" 2 "reserved for SAE assignment" 1 "inhibited" 0 "not inhibited" ;
VAL_ 2566671102 SCRSystmClnngInhbtdDTAcclPdlOffI 3 "not available" 2 "reserved for SAE assignment" 1 "inhibited" 0 "not inhibited" ;
VAL_ 2566671102 SCRSystmClnngInhbtdDeToPTOActive 3 "not available" 2 "reserved for SAE assignment" 1 "inhibited" 0 "not inhibited" ;
VAL_ 2566671102 SCRSystmClnngInhbtdDTSrvcBrkActv 3 "not available" 2 "reserved for SAE assignment" 1 "inhibited" 0 "not inhibited" ;
VAL_ 2566671102 SCRSystmClnngInhbtdDTCltchDsnggd 3 "not available" 2 "reserved for SAE assignment" 1 "inhibited" 0 "not inhibited" ;
VAL_ 2566671102 SCRSystmClnngInhbtdDTInhbtSwitch 3 "not available" 2 "reserved for SAE assignment" 1 "inhibited" 0 "not inhibited" ;
VAL_ 2566671102 SCRSystemCleaningInhibitedStatus 3 "not available" 2 "reserved for SAE assignment" 1 "inhibited" 0 "not inhibited" ;
VAL_ 2566671102 SCRSystemCleaningStatus 3 "not available" 2 "SCR system cleaning is needed" 1 "active" 0 "not active" ;
VAL_ 2566671102 SCRSystemCleaningLampCmd 7 "not available" 6 "reserved for SAE assignment" 5 "reserved for SAE assignment" 4 "On, fast blink" 3 "reserved for SAE assignment" 2 "reserved for SAE assignment " 1 "On, solid" 0 "Off" ;
VAL_ 2566668030 HtExchngerDebrisPurgeApproaching 3 "Not available" 2 "SAE reserved" 1 "Approaching" 0 "Not approaching" ;
VAL_ 2566668030 HeatExchangerDebrisPurgeStatus 3 "Not available" 2 "SAE reserved" 1 "Active" 0 "Inactive" ;
VAL_ 2499556094 HtrPwrSupplyDiagnosticStatus 7 "Not Available" 3 "Enable or pause conditions have allowed tests to execute this power cycle" 2 "Enable or pause conditions have allowed tests to execute this power cycle" 1 "Tests supported but not completed this power cycle" 0 "Tests monitored continuously" ;
VAL_ 2499556094 PwrSupplyDiagnosticStatus 7 "Not Available" 3 "Enable or pause conditions have allowed tests to execute this power cycle" 2 "Enable or pause conditions have allowed tests to execute this power cycle" 1 "Tests supported but not completed this power cycle" 0 "Tests monitored continuously" ;
VAL_ 2499556094 InputDiagnosticStatus 7 "Not Available" 3 "Enable or pause conditions have allowed tests to execute this power cycle" 2 "Enable or pause conditions have allowed tests to execute this power cycle" 1 "Tests supported but not completed this power cycle" 0 "Tests monitored continuously" ;
VAL_ 2499556094 HtrLowSideDriverDiagnosticStatus 7 "Not Available" 3 "Enable or pause conditions have allowed tests to execute this power cycle" 2 "Enable or pause conditions have allowed tests to execute this power cycle" 1 "Tests supported but not completed this power cycle" 0 "Tests monitored continuously" ;
VAL_ 2499556094 HtrHiSideDriverDiagnosticStatus 7 "Not Available" 3 "Enable or pause conditions have allowed tests to execute this power cycle" 2 "Enable or pause conditions have allowed tests to execute this power cycle" 1 "Tests supported but not completed this power cycle" 0 "Tests monitored continuously" ;
VAL_ 2566664702 DEFHtrCircuitBreaker 3 "not available" 2 "error" 1 "on" 0 "off" ;
VAL_ 2566664702 EngLoadReq 3 "Not Available" 2 "Urgent Aftertreatment Engine Load Desired" 1 "Aftertreatment Engine Load Desired" 0 "No Request" ;
VAL_ 2566664702 EngSpdIncreaseReq 3 "Not Available" 2 "Urgent Aftertreatment Engine Speed Control Desired" 1 "Aftertreatment Engine Speed Control Desired" 0 "No Request" ;
VAL_ 2566664702 ActiveRegenInhibitedDueToLowEP 3 "Not Available" 2 "Reserved for SAE assignment" 1 "Inhibited" 0 "Not Inhibited" ;
VAL_ 2566664702 ThermalManagementStatus 3 "Not available" 2 "Reserved for SAE assignment" 1 "Active" 0 "Not active" ;
VAL_ 2633773310 SCROprtrIndcmntOvrrdRnwlRequired 3 "Not Available" 2 "Error" 1 "Required" 0 "Not Required" ;
VAL_ 2633773310 SCROpratorInducementOverrideMode 4 "Expired" 3 "Active Extended" 2 "Active" 1 "Available" 0 "Not Available" 7 "Not Available" ;
VAL_ 2566663934 WastegateAct2MotorCurDis 3 "Don't Care/Take No Action" 2 "Reserved" 1 "Disable" 0 "Do Not Disable" ;
VAL_ 2566663934 CompressorBypassAct2MotorCurDis 3 "Don't Care/Take No Action" 2 "Reserved" 1 "Disable" 0 "Do Not Disable" ;
VAL_ 2566663934 CompressorBypassAct1MotorCurDis 3 "Don't Care/Take No Action" 2 "Reserved" 1 "Disable" 0 "Do Not Disable" ;
VAL_ 2566663934 EngThrttlVlv1MotorCurrentDisable 3 "Don't Care/Take No Action" 2 "Reserved" 1 "Disable" 0 "Do Not Disable" ;
VAL_ 2566663934 EngCylHdBypssActtr1MtrCrrntDsble 3 "Don't Care/Take No Action" 2 "Reserved" 1 "Disable" 0 "Do Not Disable" ;
VAL_ 2566663934 EngTrbWstgtActtr1MtrCrrntDisable 3 "Don't Care/Take No Action" 2 "Reserved" 1 "Disable" 0 "Do Not Disable" ;
VAL_ 2566663934 EngTrbCmprssrBlwffActtr1MtrCrrnt 3 "Don't Care/Take No Action" 2 "Reserved" 1 "Disable" 0 "Do Not Disable" ;
